VERSION ""

NS_ :

BS_:

BU_: BCM BSM DASM DIAG_TEST ESM ETM EVCU IPC LTM ORC SGW TBM
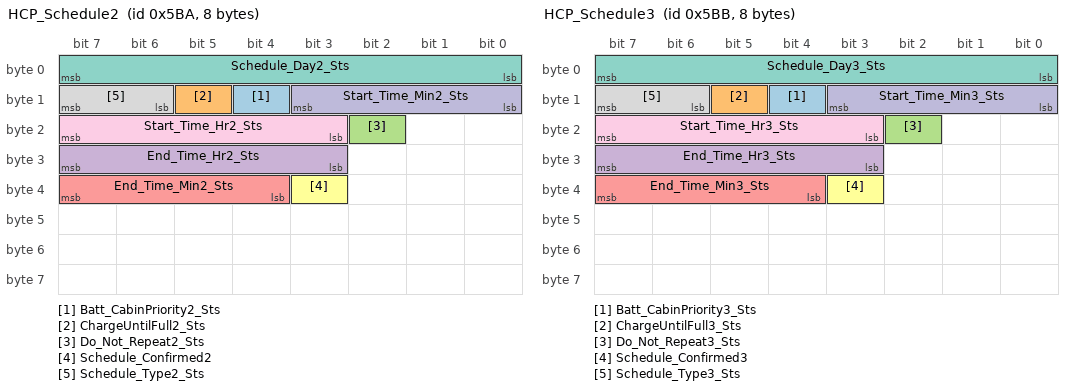
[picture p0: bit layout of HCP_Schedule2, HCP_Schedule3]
BO_ 1466 HCP_Schedule2: 8 EVCU
 SG_ Batt_CabinPriority2_Sts : 12|1@0+ (1,0) [0|1] "-" ETM,LTM,TBM
 SG_ ChargeUntilFull2_Sts : 13|1@0+ (1,0) [0|1] "-" ETM,LTM,TBM
 SG_ Do_Not_Repeat2_Sts : 18|1@0+ (1,0) [0|1] "-" ETM,LTM,TBM
 SG_ End_Time_Hr2_Sts : 31|5@0+ (1,0) [0|23] "Hours" ETM,LTM,TBM
 SG_ End_Time_Min2_Sts : 39|4@0+ (5,0) [0|55] "min" ETM,LTM,TBM
 SG_ Schedule_Confirmed2 : 35|1@0+ (1,0) [0|1] "-" ETM,LTM,TBM
 SG_ Schedule_Day2_Sts : 7|8@0+ (1,0) [0|255] "-" ETM,LTM,TBM
 SG_ Schedule_Type2_Sts : 15|2@0+ (1,0) [0|3] "-" ETM,LTM,TBM
 SG_ Start_Time_Hr2_Sts : 23|5@0+ (1,0) [0|23] "Hours" ETM,LTM,TBM
 SG_ Start_Time_Min2_Sts : 11|4@0+ (5,0) [0|55] "min" ETM,LTM,TBM

BO_ 1467 HCP_Schedule3: 8 EVCU
 SG_ Batt_CabinPriority3_Sts : 12|1@0+ (1,0) [0|1] "-" ETM,LTM,TBM
 SG_ ChargeUntilFull3_Sts : 13|1@0+ (1,0) [0|1] "-" ETM,LTM,TBM
 SG_ Do_Not_Repeat3_Sts : 18|1@0+ (1,0) [0|1] "-" ETM,LTM,TBM
 SG_ End_Time_Hr3_Sts : 31|5@0+ (1,0) [0|23] "Hours" ETM,LTM,TBM
 SG_ End_Time_Min3_Sts : 39|4@0+ (5,0) [0|55] "min" ETM,LTM,TBM
 SG_ Schedule_Confirmed3 : 35|1@0+ (1,0) [0|1] "-" ETM,LTM,TBM
 SG_ Schedule_Day3_Sts : 7|8@0+ (1,0) [0|255] "-" ETM,LTM,TBM
 SG_ Schedule_Type3_Sts : 15|2@0+ (1,0) [0|3] "-" ETM,LTM,TBM
 SG_ Start_Time_Hr3_Sts : 23|5@0+ (1,0) [0|23] "Hours" ETM,LTM,TBM
 SG_ Start_Time_Min3_Sts : 11|4@0+ (5,0) [0|55] "min" ETM,LTM,TBM

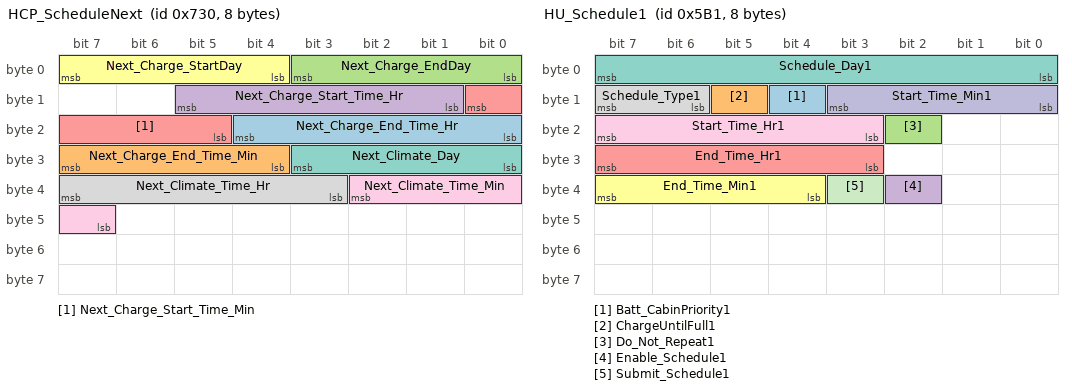
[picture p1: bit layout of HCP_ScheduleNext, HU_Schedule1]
BO_ 1840 HCP_ScheduleNext: 8 EVCU
 SG_ Next_Charge_End_Time_Hr : 20|5@0+ (1,0) [0|23] "Hours" ETM,IPC,LTM
 SG_ Next_Charge_End_Time_Min : 31|4@0+ (5,0) [0|55] "min" ETM,IPC,LTM
 SG_ Next_Charge_EndDay : 3|4@0+ (1,0) [0|15] "-" ETM,IPC,LTM
 SG_ Next_Charge_Start_Time_Hr : 13|5@0+ (1,0) [0|23] "Hours" ETM,IPC,LTM
 SG_ Next_Charge_Start_Time_Min : 8|4@0+ (5,0) [0|55] "min" ETM,IPC,LTM
 SG_ Next_Charge_StartDay : 7|4@0+ (1,0) [0|15] "-" ETM,IPC,LTM
 SG_ Next_Climate_Day : 27|4@0+ (1,0) [0|15] "-" ETM,LTM
 SG_ Next_Climate_Time_Hr : 39|5@0+ (1,0) [0|23] "Hours" ETM,LTM
 SG_ Next_Climate_Time_Min : 34|4@0+ (5,0) [0|55] "min" ETM,LTM

BO_ 2147565809 HP_DIAGNOSTIC_REQUEST_BCM: 8 DIAG_TEST
 SG_ N_PDU : 7|64@0+ (1,0) [0|0] "" BCM

BO_ 2147566833 HP_DIAGNOSTIC_REQUEST_BPCM: 8 DIAG_TEST
 SG_ N_PDU : 7|64@0+ (1,0) [0|0] "" EVCU

BO_ 2147560177 HP_DIAGNOSTIC_REQUEST_DASM: 8 DIAG_TEST
 SG_ N_PDU : 7|64@0+ (1,0) [0|0] "" DASM

BO_ 2147566321 HP_DIAGNOSTIC_REQUEST_EVCU: 8 DIAG_TEST
 SG_ N_PDU : 7|64@0+ (1,0) [0|0] "" EVCU

BO_ 2147569905 HP_DIAGNOSTIC_REQUEST_IDCM: 8 DIAG_TEST
 SG_ N_PDU : 7|64@0+ (1,0) [0|0] "" EVCU

BO_ 2147574001 HP_DIAGNOSTIC_REQUEST_IPC: 8 DIAG_TEST
 SG_ N_PDU : 7|64@0+ (1,0) [0|0] "-" IPC

BO_ 2147569649 HP_DIAGNOSTIC_REQUEST_RCU: 8 DIAG_TEST
 SG_ N_PDU : 7|64@0+ (1,0) [0|0] "" BCM

BO_ 2147601393 HP_DIAGNOSTIC_REQUEST_SGW: 8 DIAG_TEST
 SG_ N_PDU : 7|64@0+ (1,0) [0|0] "" SGW

BO_ 2147557361 HP_DIAGNOSTIC_REQUEST_SHIFTER: 8 DIAG_TEST
 SG_ N_PDU : 7|64@0+ (1,0) [0|0] "" ESM

BO_ 2147600113 HP_DIAGNOSTIC_REQUEST_TBM: 8 DIAG_TEST
 SG_ N_PDU : 7|64@0+ (1,0) [0|0] "" TBM

BO_ 2147571441 HP_DIAGNOSTIC_REQUEST_WSMD: 8 DIAG_TEST
 SG_ N_PDU : 7|64@0+ (1,0) [0|0] "" BCM

BO_ 2147571697 HP_DIAGNOSTIC_REQUEST_WSMP: 8 DIAG_TEST
 SG_ N_PDU : 7|64@0+ (1,0) [0|0] "" BCM

BO_ 1457 HU_Schedule1: 8 BCM
 SG_ Batt_CabinPriority1 : 12|1@0+ (1,0) [0|1] "-" EVCU
 SG_ ChargeUntilFull1 : 13|1@0+ (1,0) [0|1] "-" EVCU
 SG_ Do_Not_Repeat1 : 18|1@0+ (1,0) [0|1] "-" EVCU
 SG_ Enable_Schedule1 : 34|1@0+ (1,0) [0|1] "-" EVCU
 SG_ End_Time_Hr1 : 31|5@0+ (1,0) [0|23] "Hours" EVCU
 SG_ End_Time_Min1 : 39|4@0+ (5,0) [0|55] "min" EVCU
 SG_ Schedule_Day1 : 7|8@0+ (1,0) [0|255] "-" EVCU
 SG_ Schedule_Type1 : 15|2@0+ (1,0) [0|3] "-" EVCU
 SG_ Start_Time_Hr1 : 23|5@0+ (1,0) [0|23] "Hours" EVCU
 SG_ Start_Time_Min1 : 11|4@0+ (5,0) [0|55] "min" EVCU
 SG_ Submit_Schedule1 : 35|1@0+ (1,0) [0|1] "-" EVCU

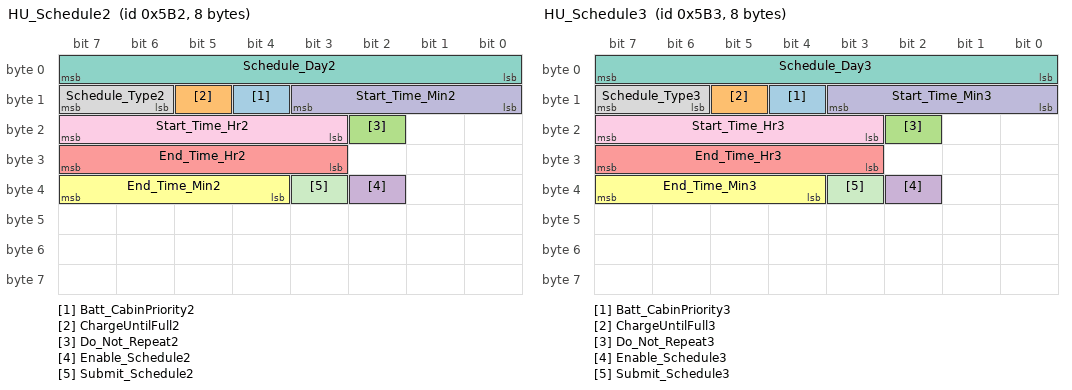
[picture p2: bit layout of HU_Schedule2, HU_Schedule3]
BO_ 1458 HU_Schedule2: 8 BCM
 SG_ Batt_CabinPriority2 : 12|1@0+ (1,0) [0|1] "-" EVCU
 SG_ ChargeUntilFull2 : 13|1@0+ (1,0) [0|1] "-" EVCU
 SG_ Do_Not_Repeat2 : 18|1@0+ (1,0) [0|1] "-" EVCU
 SG_ Enable_Schedule2 : 34|1@0+ (1,0) [0|1] "-" EVCU
 SG_ End_Time_Hr2 : 31|5@0+ (1,0) [0|23] "Hours" EVCU
 SG_ End_Time_Min2 : 39|4@0+ (5,0) [0|55] "min" EVCU
 SG_ Schedule_Day2 : 7|8@0+ (1,0) [0|255] "-" EVCU
 SG_ Schedule_Type2 : 15|2@0+ (1,0) [0|3] "-" EVCU
 SG_ Start_Time_Hr2 : 23|5@0+ (1,0) [0|23] "Hours" EVCU
 SG_ Start_Time_Min2 : 11|4@0+ (5,0) [0|55] "min" EVCU
 SG_ Submit_Schedule2 : 35|1@0+ (1,0) [0|1] "-" EVCU

BO_ 1459 HU_Schedule3: 8 BCM
 SG_ Batt_CabinPriority3 : 12|1@0+ (1,0) [0|1] "-" EVCU
 SG_ ChargeUntilFull3 : 13|1@0+ (1,0) [0|1] "-" EVCU
 SG_ Do_Not_Repeat3 : 18|1@0+ (1,0) [0|1] "-" EVCU
 SG_ Enable_Schedule3 : 34|1@0+ (1,0) [0|1] "-" EVCU
 SG_ End_Time_Hr3 : 31|5@0+ (1,0) [0|23] "Hours" EVCU
 SG_ End_Time_Min3 : 39|4@0+ (5,0) [0|55] "min" EVCU
 SG_ Schedule_Day3 : 7|8@0+ (1,0) [0|255] "-" EVCU
 SG_ Schedule_Type3 : 15|2@0+ (1,0) [0|3] "-" EVCU
 SG_ Start_Time_Hr3 : 23|5@0+ (1,0) [0|23] "Hours" EVCU
 SG_ Start_Time_Min3 : 11|4@0+ (5,0) [0|55] "min" EVCU
 SG_ Submit_Schedule3 : 35|1@0+ (1,0) [0|1] "-" EVCU

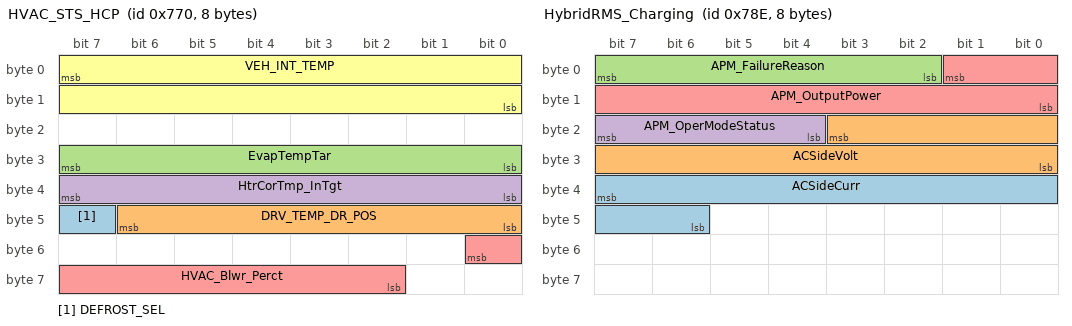
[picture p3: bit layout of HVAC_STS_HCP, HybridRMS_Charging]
BO_ 1904 HVAC_STS_HCP: 8 BCM
 SG_ DEFROST_SEL : 47|1@0+ (1,0) [0|1] "" EVCU
 SG_ DRV_TEMP_DR_POS : 46|7@0+ (1,0) [0|100] "%" EVCU
 SG_ EvapTempTar : 31|8@0+ (0.5,-20) [-20|107] "°C" EVCU
 SG_ HtrCorTmp_InTgt : 39|8@0+ (1,-40) [-40|214] "°C" EVCU
 SG_ HVAC_Blwr_Perct : 48|7@0+ (1,0) [0|100] "%" EVCU
 SG_ VEH_INT_TEMP : 7|16@0+ (0.01,-40) [-40|85] "°C" EVCU

BO_ 1933 HybridRMS_CellVoltage25: 8 Vector__XXX
 SG_ HVBatCellVltMax : 7|13@0+ (0.001,0) [0|5] "Volts" TBM

BO_ 1934 HybridRMS_Charging: 8 EVCU
 SG_ ACSideCurr : 39|10@0+ (0.1,-50) [-50|50] "Amp" TBM
 SG_ ACSideVolt : 19|12@0+ (0.1,0) [0|300] "Volt" TBM
 SG_ APM_FailureReason : 7|6@0+ (1,0) [0|62] "1" TBM
 SG_ APM_OperModeStatus : 23|4@0+ (1,0) [0|14] "" TBM
 SG_ APM_OutputPower : 1|10@0+ (3,0) [0|3066] "W" TBM

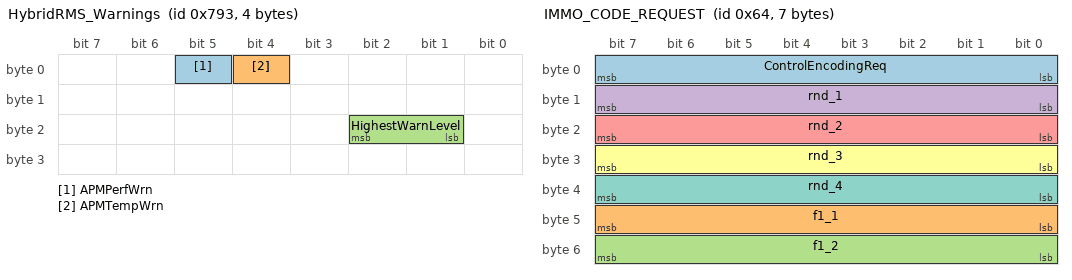
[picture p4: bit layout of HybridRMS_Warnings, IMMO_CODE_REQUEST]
BO_ 1939 HybridRMS_Warnings: 4 EVCU
 SG_ APMPerfWrn : 5|1@0+ (1,0) [0|1] "" Vector__XXX
 SG_ APMTempWrn : 4|1@0+ (1,0) [0|1] "" Vector__XXX
 SG_ HighestWarnLevel : 18|2@0+ (1,0) [0|3] "" TBM

BO_ 100 IMMO_CODE_REQUEST: 7 EVCU
 SG_ ControlEncodingReq : 7|8@0+ (1,0) [0|255] "-" BCM
 SG_ f1_1 : 47|8@0+ (1,0) [0|255] "-" BCM
 SG_ f1_2 : 55|8@0+ (1,0) [0|255] "-" BCM
 SG_ rnd_1 : 15|8@0+ (1,0) [0|255] "-" BCM
 SG_ rnd_2 : 23|8@0+ (1,0) [0|255] "-" BCM
 SG_ rnd_3 : 31|8@0+ (1,0) [0|255] "-" BCM
 SG_ rnd_4 : 39|8@0+ (1,0) [0|255] "-" BCM

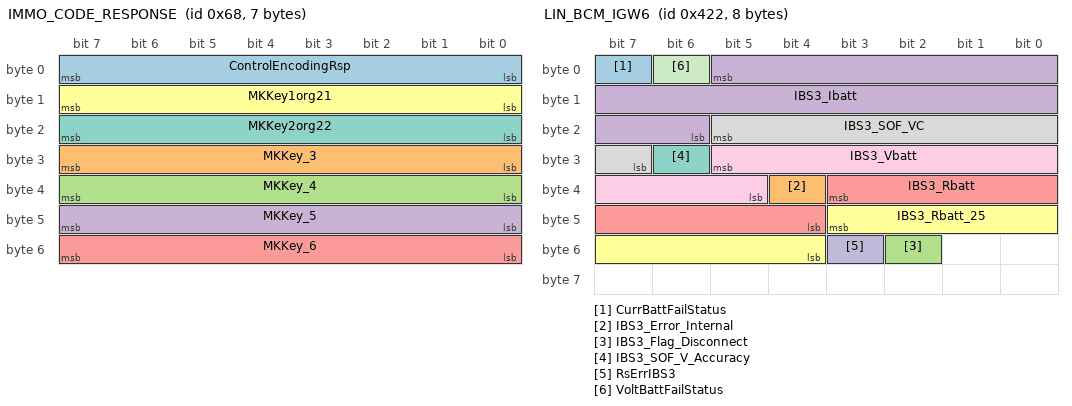
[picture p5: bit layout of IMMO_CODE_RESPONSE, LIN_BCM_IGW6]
BO_ 104 IMMO_CODE_RESPONSE: 7 BCM
 SG_ ControlEncodingRsp : 7|8@0+ (1,0) [0|255] "-" EVCU
 SG_ MKKey_3 : 31|8@0+ (1,0) [0|255] "-" EVCU
 SG_ MKKey_4 : 39|8@0+ (1,0) [0|255] "-" EVCU
 SG_ MKKey_5 : 47|8@0+ (1,0) [0|255] "-" EVCU
 SG_ MKKey_6 : 55|8@0+ (1,0) [0|255] "-" EVCU
 SG_ MKKey1org21 : 15|8@0+ (1,0) [0|255] "-" EVCU
 SG_ MKKey2org22 : 23|8@0+ (1,0) [0|255] "-" EVCU

BO_ 346 IMPACT_INFO: 4 ORC
 SG_ CRC_II : 31|8@0+ (1,0) [0|255] "" BCM,TBM
 SG_ IMPACT_A : 4|1@0+ (1,0) [0|1] "" TBM
 SG_ IMPACT_B : 3|1@0+ (1,0) [0|1] "" TBM
 SG_ IMPACT_C : 2|1@0+ (1,0) [0|1] "" TBM
 SG_ IMPACT_D : 1|1@0+ (1,0) [0|1] "" TBM
 SG_ IMPACT_E : 0|1@0+ (1,0) [0|1] "" TBM
 SG_ IMPACT_F : 15|1@0+ (1,0) [0|1] "" TBM
 SG_ IMPACT_G : 14|1@0+ (1,0) [0|1] "" TBM
 SG_ IMPACT_H : 13|1@0+ (1,0) [0|1] "" TBM
 SG_ IMPACT_I : 12|1@0+ (1,0) [0|1] "" TBM
 SG_ IMPACT_K : 11|1@0+ (1,0) [0|1] "" TBM
 SG_ IMPACT_L : 10|1@0+ (1,0) [0|1] "" TBM
 SG_ IMPACT_M : 9|1@0+ (1,0) [0|1] "" TBM
 SG_ IMPACT_O : 8|1@0+ (1,0) [0|1] "" TBM
 SG_ IMPACTCommand : 6|1@0+ (1,0) [0|1] "" BCM,EVCU,TBM
 SG_ IMPACTConfirm : 7|1@0+ (1,0) [0|1] "" BCM,EVCU,TBM
 SG_ IMPACTFailSts : 5|1@0+ (1,0) [0|1] "" BCM,TBM
 SG_ MessageCounter_II : 19|4@0+ (1,0) [0|15] "" BCM,TBM

BO_ 1058 LIN_BCM_IGW6: 8 BCM
 SG_ CurrBattFailStatus : 7|1@0+ (1,0) [0|1] "-" Vector__XXX
 SG_ IBS3_Error_Internal : 36|1@0+ (1,0) [0|1] "-" Vector__XXX
 SG_ IBS3_Flag_Disconnect : 50|1@0+ (1,0) [0|1] "-" Vector__XXX
 SG_ IBS3_Ibatt : 5|16@0+ (0.02,-1000) [-1000|310.7] "A" TBM
 SG_ IBS3_Rbatt : 35|8@0+ (0.1,0) [0|25.5] "mOhm" Vector__XXX
 SG_ IBS3_Rbatt_25 : 43|8@0+ (0.1,0) [0|25.5] "mOhm" Vector__XXX
 SG_ IBS3_SOF_V_Accuracy : 30|1@0+ (1,0) [0|1] "-" Vector__XXX
 SG_ IBS3_SOF_VC : 21|7@0+ (0.05,5) [5|11.35] "V" Vector__XXX
 SG_ IBS3_Vbatt : 29|9@0+ (0.025,5) [5|17.775] "V" EVCU,TBM
 SG_ RsErrIBS3 : 51|1@0+ (1,0) [0|1] "-" Vector__XXX
 SG_ VoltBattFailStatus : 6|1@0+ (1,0) [0|1] "-" EVCU

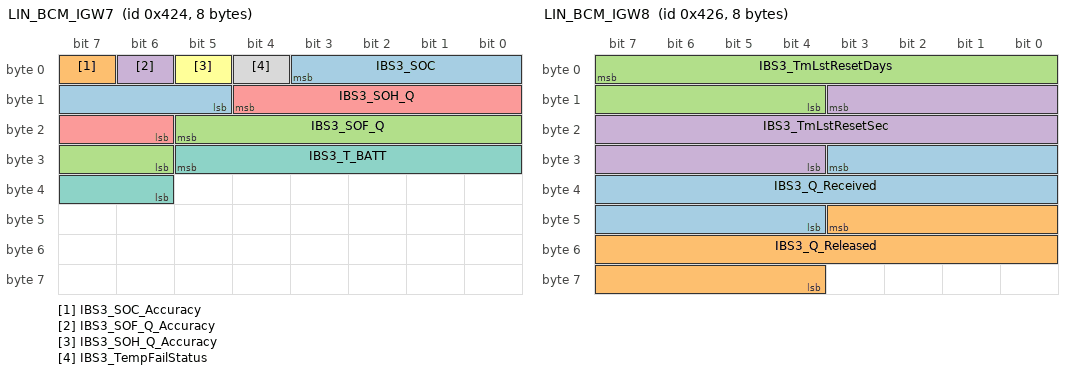
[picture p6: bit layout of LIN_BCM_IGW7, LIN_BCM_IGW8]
BO_ 1060 LIN_BCM_IGW7: 8 BCM
 SG_ IBS3_SOC : 3|7@0+ (1,0) [0|127] "%" EVCU,ORC,TBM
 SG_ IBS3_SOC_Accuracy : 7|1@0+ (1,0) [0|1] "-" EVCU,TBM
 SG_ IBS3_SOF_Q : 21|8@0+ (1,0) [0|255] "Ah" Vector__XXX
 SG_ IBS3_SOF_Q_Accuracy : 6|1@0+ (1,0) [0|1] "-" Vector__XXX
 SG_ IBS3_SOH_Q : 12|7@0+ (2,0) [0|254] "Ah" Vector__XXX
 SG_ IBS3_SOH_Q_Accuracy : 5|1@0+ (1,0) [0|1] "-" Vector__XXX
 SG_ IBS3_T_BATT : 29|8@0+ (1,-40) [-40|215] "°C" EVCU,TBM
 SG_ IBS3_TempFailStatus : 4|1@0+ (1,0) [0|1] "-" EVCU

BO_ 1062 LIN_BCM_IGW8: 8 BCM
 SG_ IBS3_Q_Received : 27|16@0+ (0.125,0) [0|8191] "Ah" Vector__XXX
 SG_ IBS3_Q_Released : 43|16@0+ (0.125,0) [0|8191] "Ah" Vector__XXX
 SG_ IBS3_TmLstResetDays : 7|12@0+ (1,0) [0|4094] "Days" Vector__XXX
 SG_ IBS3_TmLstResetSec : 11|16@0+ (2,0) [0|131068] "sec" Vector__XXX

BO_ 256 MOT_TRANSM1: 8 EVCU
 SG_ ECM_LHOM : 7|1@0+ (1,0) [0|1] "-" ORC

BO_ 500 MOT_TRANSM3: 8 EVCU
 SG_ CRC_MT3 : 63|8@0+ (1,0) [0|255] "" BCM,DASM
 SG_ Message_Counter_MT3 : 51|4@0+ (1,0) [0|15] "" BCM,DASM

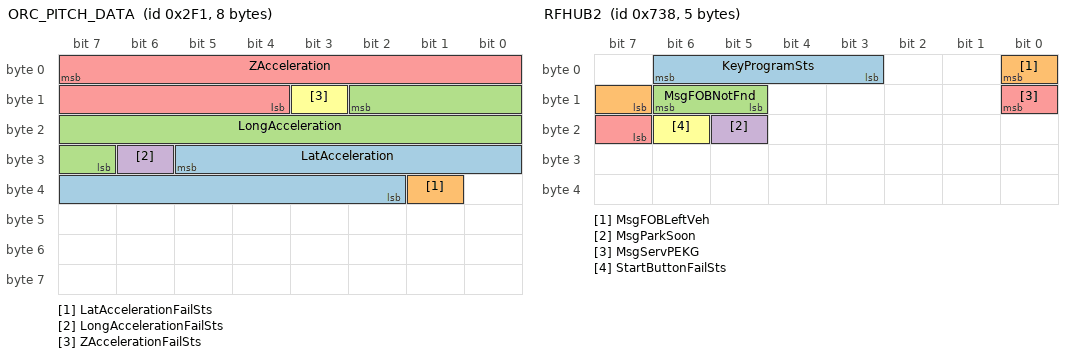
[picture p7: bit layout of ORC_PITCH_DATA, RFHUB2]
BO_ 753 ORC_PITCH_DATA: 8 ORC
 SG_ LatAcceleration : 29|12@0+ (0.02,-40.96) [-40.96|40.92] "m/s^2" Vector__XXX
 SG_ LatAccelerationFailSts : 33|1@0+ (1,0) [0|1] "-" Vector__XXX
 SG_ LongAcceleration : 10|12@0+ (0.02,-40.96) [-40.96|40.92] "m/s^2" Vector__XXX
 SG_ LongAccelerationFailSts : 30|1@0+ (1,0) [0|1] "-" Vector__XXX
 SG_ ZAcceleration : 7|12@0+ (0.02,-40.96) [-40.96|40.94] "m/s^2" TBM
 SG_ ZAccelerationFailSts : 11|1@0+ (1,0) [0|1] "-" Vector__XXX

BO_ 1848 RFHUB2: 5 BCM
 SG_ KeyProgramSts : 6|4@0+ (1,0) [0|15] "" IPC
 SG_ MsgFOBLeftVeh : 0|2@0+ (1,0) [0|2] "" IPC
 SG_ MsgFOBNotFnd : 14|2@0+ (1,0) [0|2] "" IPC
 SG_ MsgParkSoon : 21|1@0+ (1,0) [0|1] "" IPC
 SG_ MsgServPEKG : 8|2@0+ (1,0) [0|3] "" IPC
 SG_ StartButtonFailSts : 22|1@0+ (1,0) [0|1] "" IPC

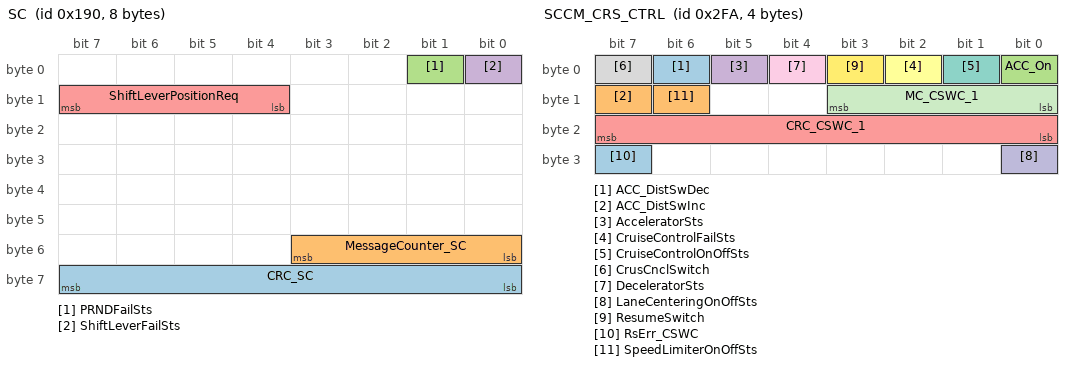
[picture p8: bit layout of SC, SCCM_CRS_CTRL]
BO_ 400 SC: 8 ESM
 SG_ CRC_SC : 63|8@0+ (1,0) [0|255] "" EVCU
 SG_ MessageCounter_SC : 51|4@0+ (1,0) [0|15] "" EVCU
 SG_ PRNDFailSts : 1|1@0+ (1,0) [0|1] "-" EVCU
 SG_ ShiftLeverFailSts : 0|1@0+ (1,0) [0|1] "-" EVCU,IPC
 SG_ ShiftLeverPositionReq : 15|4@0+ (1,0) [0|7] "-" EVCU

BO_ 762 SCCM_CRS_CTRL: 4 BCM
 SG_ ACC_DistSwDec : 6|1@0+ (1,0) [0|1] "" TBM
 SG_ ACC_DistSwInc : 15|1@0+ (1,0) [0|1] "" TBM
 SG_ ACC_On : 0|1@0+ (1,0) [0|1] "" EVCU,TBM
 SG_ AcceleratorSts : 5|1@0+ (1,0) [0|1] "" EVCU,TBM
 SG_ CRC_CSWC_1 : 23|8@0+ (1,0) [0|255] "" EVCU
 SG_ CruiseControlFailSts : 2|1@0+ (1,0) [0|1] "" EVCU,ORC
 SG_ CruiseControlOnOffSts : 1|1@0+ (1,0) [0|1] "" EVCU,ORC,TBM
 SG_ CrusCnclSwitch : 7|1@0+ (1,0) [0|1] "" EVCU,TBM
 SG_ DeceleratorSts : 4|1@0+ (1,0) [0|1] "" EVCU,TBM
 SG_ LaneCenteringOnOffSts : 24|1@0+ (1,0) [0|1] "" EVCU
 SG_ MC_CSWC_1 : 11|4@0+ (1,0) [0|15] "" EVCU
 SG_ ResumeSwitch : 3|1@0+ (1,0) [0|1] "" EVCU,TBM
 SG_ RsErr_CSWC : 31|1@0+ (1,0) [0|1] "" Vector__XXX
 SG_ SpeedLimiterOnOffSts : 14|1@0+ (1,0) [0|1] "" EVCU

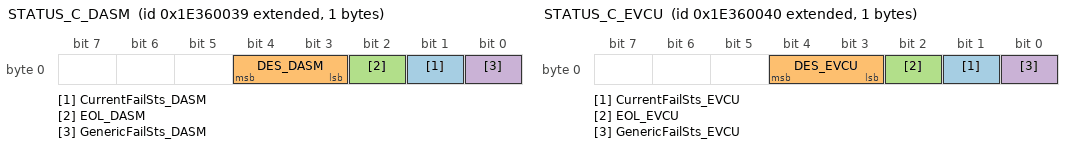
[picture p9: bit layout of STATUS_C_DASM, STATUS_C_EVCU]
BO_ 2654339129 STATUS_C_DASM: 1 DASM
 SG_ CurrentFailSts_DASM : 1|1@0+ (1,0) [0|1] "-" BCM
 SG_ DES_DASM : 4|2@0+ (1,0) [0|2] "-" Vector__XXX
 SG_ EOL_DASM : 2|1@0+ (1,0) [0|1] "-" BCM
 SG_ GenericFailSts_DASM : 0|1@0+ (1,0) [0|1] "-" BCM

BO_ 2654339136 STATUS_C_EVCU: 1 EVCU
 SG_ CurrentFailSts_EVCU : 1|1@0+ (1,0) [0|1] "-" BCM,TBM
 SG_ DES_EVCU : 4|2@0+ (1,0) [0|2] "-" Vector__XXX
 SG_ EOL_EVCU : 2|1@0+ (1,0) [0|1] "-" BCM
 SG_ GenericFailSts_EVCU : 0|1@0+ (1,0) [0|1] "-" BCM,TBM

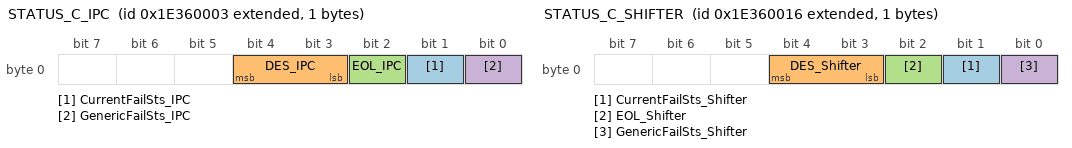
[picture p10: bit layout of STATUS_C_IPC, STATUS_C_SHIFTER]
BO_ 2654339075 STATUS_C_IPC: 1 IPC
 SG_ CurrentFailSts_IPC : 1|1@0+ (1,0) [0|1] "-" BCM
 SG_ DES_IPC : 4|2@0+ (1,0) [0|2] "-" Vector__XXX
 SG_ EOL_IPC : 2|1@0+ (1,0) [0|1] "-" BCM
 SG_ GenericFailSts_IPC : 0|1@0+ (1,0) [0|1] "-" BCM

BO_ 2654339094 STATUS_C_SHIFTER: 1 ESM
 SG_ CurrentFailSts_Shifter : 1|1@0+ (1,0) [0|1] "-" BCM
 SG_ DES_Shifter : 4|2@0+ (1,0) [0|2] "-" Vector__XXX
 SG_ EOL_Shifter : 2|1@0+ (1,0) [0|1] "-" BCM
 SG_ GenericFailSts_Shifter : 0|1@0+ (1,0) [0|1] "-" BCM

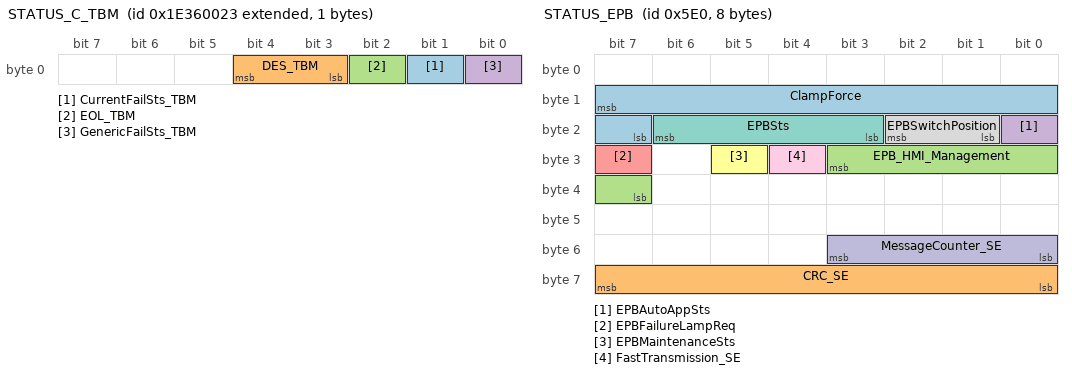
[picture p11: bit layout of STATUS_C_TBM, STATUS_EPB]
BO_ 2654339107 STATUS_C_TBM: 1 TBM
 SG_ CurrentFailSts_TBM : 1|1@0+ (1,0) [0|1] "-" BCM
 SG_ DES_TBM : 4|2@0+ (1,0) [0|2] "-" Vector__XXX
 SG_ EOL_TBM : 2|1@0+ (1,0) [0|1] "-" BCM
 SG_ GenericFailSts_TBM : 0|1@0+ (1,0) [0|1] "-" BCM

BO_ 1504 STATUS_EPB: 8 BSM
 SG_ ClampForce : 15|9@0+ (0.1,-0.1) [0|51] "KN" Vector__XXX
 SG_ CRC_SE : 63|8@0+ (1,0) [0|255] "" BCM,DASM,EVCU
 SG_ EPB_HMI_Management : 27|5@0+ (1,0) [0|31] "" IPC
 SG_ EPBAutoAppSts : 16|1@0+ (1,0) [0|1] "" IPC
 SG_ EPBFailureLampReq : 31|1@0+ (1,0) [0|1] "" IPC,ORC,TBM
 SG_ EPBMaintenanceSts : 29|1@0+ (1,0) [0|1] "" IPC
 SG_ EPBSts : 22|4@0+ (1,0) [0|14] "-" BCM,EVCU,IPC,ORC,TBM
 SG_ EPBSwitchPosition : 18|2@0+ (1,0) [0|3] "" Vector__XXX
 SG_ FastTransmission_SE : 28|1@0+ (1,0) [0|1] "" Vector__XXX
 SG_ MessageCounter_SE : 51|4@0+ (1,0) [0|15] "" BCM,DASM,EVCU

BO_ 1941 STATUS_EVCU: 8 EVCU
 SG_ PowerModeSts_EVCU : 7|2@0+ (1,0) [0|3] "-" BCM,TBM

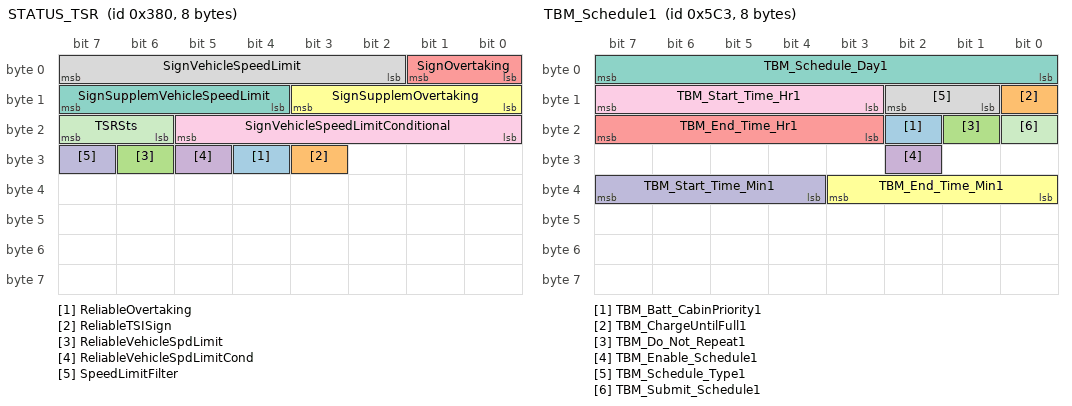
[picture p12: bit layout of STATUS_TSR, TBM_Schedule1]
BO_ 896 STATUS_TSR: 8 BCM
 SG_ ReliableOvertaking : 28|1@0+ (1,0) [0|1] "" IPC
 SG_ ReliableTSISign : 27|1@0+ (1,0) [0|1] "" IPC
 SG_ ReliableVehicleSpdLimit : 30|1@0+ (1,0) [0|1] "" IPC
 SG_ ReliableVehicleSpdLimitCond : 29|1@0+ (1,0) [0|1] "" IPC
 SG_ SignOvertaking : 1|2@0+ (1,0) [0|3] "" IPC
 SG_ SignSupplemOvertaking : 11|4@0+ (1,0) [0|15] "" IPC
 SG_ SignSupplemVehicleSpeedLimit : 15|4@0+ (1,0) [0|15] "" IPC
 SG_ SignVehicleSpeedLimit : 7|6@0+ (1,0) [0|63] "" IPC
 SG_ SignVehicleSpeedLimitConditional : 21|6@0+ (1,0) [0|63] "" IPC
 SG_ SpeedLimitFilter : 31|1@0+ (1,0) [0|1] "" IPC
 SG_ TSRSts : 23|2@0+ (1,0) [0|3] "" ETM,EVCU,IPC

BO_ 1475 TBM_Schedule1: 8 BCM
 SG_ TBM_Batt_CabinPriority1 : 18|1@0+ (1,0) [0|1] "-" EVCU
 SG_ TBM_ChargeUntilFull1 : 8|1@0+ (1,0) [0|1] "-" EVCU
 SG_ TBM_Do_Not_Repeat1 : 17|1@0+ (1,0) [0|1] "-" EVCU
 SG_ TBM_Enable_Schedule1 : 26|1@0+ (1,0) [0|1] "-" EVCU
 SG_ TBM_End_Time_Hr1 : 23|5@0+ (1,0) [0|23] "Hours" EVCU
 SG_ TBM_End_Time_Min1 : 35|4@0+ (5,0) [0|55] "min" EVCU
 SG_ TBM_Schedule_Day1 : 7|8@0+ (1,0) [0|255] "-" EVCU
 SG_ TBM_Schedule_Type1 : 10|2@0+ (1,0) [0|3] "-" EVCU
 SG_ TBM_Start_Time_Hr1 : 15|5@0+ (1,0) [0|23] "Hours" EVCU
 SG_ TBM_Start_Time_Min1 : 39|4@0+ (5,0) [0|55] "min" EVCU
 SG_ TBM_Submit_Schedule1 : 16|1@0+ (1,0) [0|1] "-" EVCU

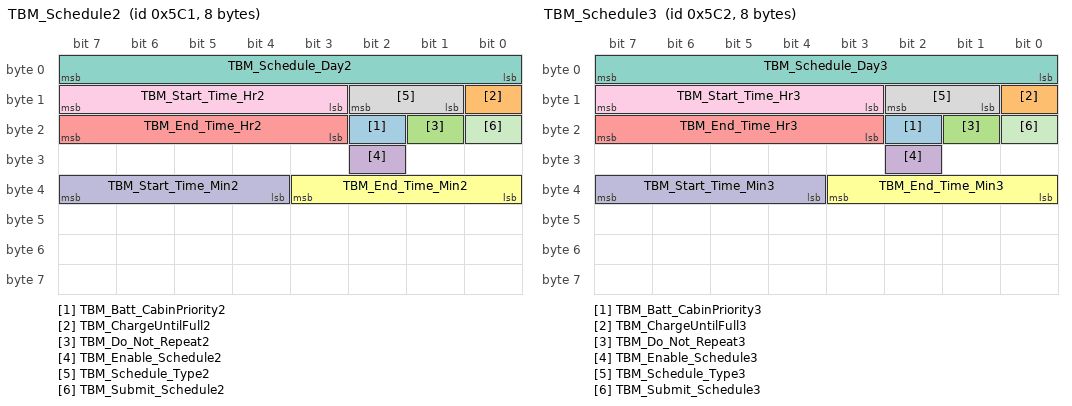
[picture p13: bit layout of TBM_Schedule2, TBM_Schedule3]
BO_ 1473 TBM_Schedule2: 8 BCM
 SG_ TBM_Batt_CabinPriority2 : 18|1@0+ (1,0) [0|1] "-" EVCU
 SG_ TBM_ChargeUntilFull2 : 8|1@0+ (1,0) [0|1] "-" EVCU
 SG_ TBM_Do_Not_Repeat2 : 17|1@0+ (1,0) [0|1] "-" EVCU
 SG_ TBM_Enable_Schedule2 : 26|1@0+ (1,0) [0|1] "-" EVCU
 SG_ TBM_End_Time_Hr2 : 23|5@0+ (1,0) [0|23] "Hours" EVCU
 SG_ TBM_End_Time_Min2 : 35|4@0+ (5,0) [0|55] "min" EVCU
 SG_ TBM_Schedule_Day2 : 7|8@0+ (1,0) [0|255] "-" EVCU
 SG_ TBM_Schedule_Type2 : 10|2@0+ (1,0) [0|3] "-" EVCU
 SG_ TBM_Start_Time_Hr2 : 15|5@0+ (1,0) [0|23] "Hours" EVCU
 SG_ TBM_Start_Time_Min2 : 39|4@0+ (5,0) [0|55] "min" EVCU
 SG_ TBM_Submit_Schedule2 : 16|1@0+ (1,0) [0|1] "-" EVCU

BO_ 1474 TBM_Schedule3: 8 BCM
 SG_ TBM_Batt_CabinPriority3 : 18|1@0+ (1,0) [0|1] "-" EVCU
 SG_ TBM_ChargeUntilFull3 : 8|1@0+ (1,0) [0|1] "-" EVCU
 SG_ TBM_Do_Not_Repeat3 : 17|1@0+ (1,0) [0|1] "-" EVCU
 SG_ TBM_Enable_Schedule3 : 26|1@0+ (1,0) [0|1] "-" EVCU
 SG_ TBM_End_Time_Hr3 : 23|5@0+ (1,0) [0|23] "Hours" EVCU
 SG_ TBM_End_Time_Min3 : 35|4@0+ (5,0) [0|55] "min" EVCU
 SG_ TBM_Schedule_Day3 : 7|8@0+ (1,0) [0|255] "-" EVCU
 SG_ TBM_Schedule_Type3 : 10|2@0+ (1,0) [0|3] "-" EVCU
 SG_ TBM_Start_Time_Hr3 : 15|5@0+ (1,0) [0|23] "Hours" EVCU
 SG_ TBM_Start_Time_Min3 : 39|4@0+ (5,0) [0|55] "min" EVCU
 SG_ TBM_Submit_Schedule3 : 16|1@0+ (1,0) [0|1] "-" EVCU

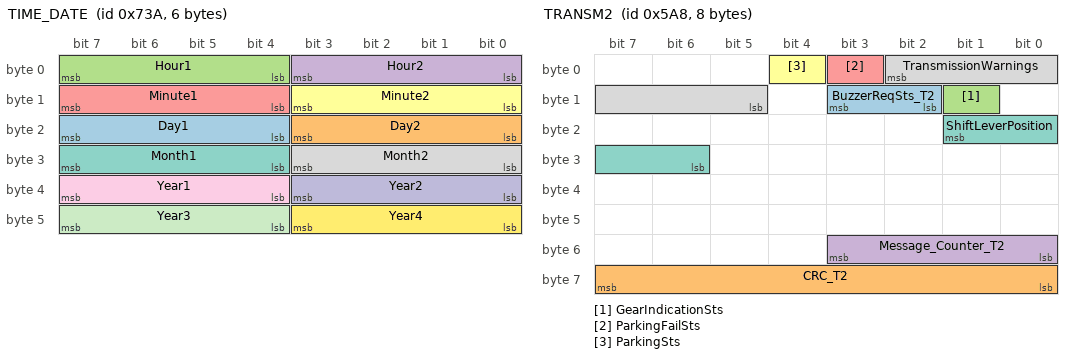
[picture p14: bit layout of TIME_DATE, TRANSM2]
BO_ 1850 TIME_DATE: 6 IPC
 SG_ Day1 : 23|4@0+ (1,0) [0|9] "-" BCM,BSM,EVCU
 SG_ Day2 : 19|4@0+ (1,0) [0|9] "-" BCM,BSM,EVCU
 SG_ Hour1 : 7|4@0+ (1,0) [0|9] "-" BCM,BSM,EVCU
 SG_ Hour2 : 3|4@0+ (1,0) [0|9] "-" BCM,BSM,EVCU
 SG_ Minute1 : 15|4@0+ (1,0) [0|9] "-" BCM,BSM,EVCU
 SG_ Minute2 : 11|4@0+ (1,0) [0|9] "-" BCM,BSM,EVCU
 SG_ Month1 : 31|4@0+ (1,0) [0|9] "-" BCM,BSM,EVCU
 SG_ Month2 : 27|4@0+ (1,0) [0|9] "-" BCM,BSM,EVCU
 SG_ Year1 : 39|4@0+ (1,0) [0|9] "-" BCM,BSM,EVCU
 SG_ Year2 : 35|4@0+ (1,0) [0|9] "-" BCM,BSM,EVCU
 SG_ Year3 : 47|4@0+ (1,0) [0|9] "-" BCM,BSM,EVCU
 SG_ Year4 : 43|4@0+ (1,0) [0|9] "-" BCM,BSM,EVCU

BO_ 1000 TPM_CAL: 1 BSM
 SG_ CalibrationAck : 5|2@0+ (1,0) [0|3] "-" IPC
 SG_ CalibrationSts : 7|2@0+ (1,0) [0|3] "-" Vector__XXX

BO_ 1448 TRANSM2: 8 EVCU
 SG_ BuzzerReqSts_T2 : 11|2@0+ (1,0) [0|3] "" IPC
 SG_ CRC_T2 : 63|8@0+ (1,0) [0|255] "count" BCM,BSM,DASM,ESM
 SG_ GearIndicationSts : 9|1@0+ (1,0) [0|1] "-" ESM,IPC
 SG_ Message_Counter_T2 : 51|4@0+ (1,0) [0|15] "" BCM,BSM,DASM,ESM
 SG_ ParkingFailSts : 3|1@0+ (1,0) [0|1] "-" BCM,IPC,TBM
 SG_ ParkingSts : 4|1@0+ (1,0) [0|1] "-" BCM
 SG_ ShiftLeverPosition : 17|4@0+ (1,0) [0|15] "-" BCM,BSM,ESM,ETM,IPC,LTM,TBM
 SG_ TransmissionWarnings : 2|6@0+ (1,0) [0|63] "-" IPC,TBM

BO_ 344 TRANSM3: 4 EVCU
 SG_ Vehicle_Hold_Rq : 5|1@0+ (1,0) [0|1] "-" BSM

BO_ 253 TRM_CODE_RESPONSE: 6 BCM
 SG_ TxpFound : 31|1@0+ (1,0) [0|1] "-" Vector__XXX
 SG_ TxpID : 30|4@0+ (1,0) [0|15] "-" Vector__XXX

BO_ 1046 VIN: 8 BCM
 SG_ VIN_DATA : 15|56@0+ (1,0) [0|7.20575940379279E+16] "" DASM,ESM,EVCU,IPC,ORC
 SG_ VIN_MSG : 1|2@0+ (1,0) [0|3] "" DASM,ESM,EVCU,IPC,ORC

BO_ 2654208000 WAKE_C_BCM: 8 BCM
 SG_ MainWakeSts_BCM : 7|1@0+ (1,0) [0|1] "-" BSM,ESM,EVCU,IPC,TBM
 SG_ Node0 : 40|1@0+ (1,0) [0|1] "-" BSM,ESM,EVCU,IPC,TBM
 SG_ Node1 : 41|1@0+ (1,0) [0|1] "-" BSM,ESM,EVCU,IPC,TBM
 SG_ Node10 : 34|1@0+ (1,0) [0|1] "-" BSM,ESM,EVCU,IPC,TBM
 SG_ Node11 : 35|1@0+ (1,0) [0|1] "-" BSM,ESM,EVCU,IPC,TBM
 SG_ Node12 : 36|1@0+ (1,0) [0|1] "-" BSM,ESM,EVCU,IPC,TBM
 SG_ Node13 : 37|1@0+ (1,0) [0|1] "-" BSM,ESM,EVCU,IPC,TBM
 SG_ Node14 : 38|1@0+ (1,0) [0|1] "-" BSM,ESM,EVCU,IPC,TBM
 SG_ Node15 : 39|1@0+ (1,0) [0|1] "-" BSM,ESM,EVCU,IPC,TBM
 SG_ Node16 : 24|1@0+ (1,0) [0|1] "-" BSM,ESM,EVCU,IPC,TBM
 SG_ Node17 : 25|1@0+ (1,0) [0|1] "-" BSM,ESM,EVCU,IPC,TBM
 SG_ Node18 : 26|1@0+ (1,0) [0|1] "-" BSM,ESM,EVCU,IPC,TBM
 SG_ Node19 : 27|1@0+ (1,0) [0|1] "-" BSM,ESM,EVCU,IPC,TBM
 SG_ Node2 : 42|1@0+ (1,0) [0|1] "-" BSM,ESM,EVCU,IPC,TBM
 SG_ Node20 : 28|1@0+ (1,0) [0|1] "-" BSM,ESM,EVCU,IPC,TBM
 SG_ Node21 : 29|1@0+ (1,0) [0|1] "-" BSM,ESM,EVCU,IPC,TBM
 SG_ Node22 : 30|1@0+ (1,0) [0|1] "-" BSM,ESM,EVCU,IPC,TBM
 SG_ Node23 : 31|1@0+ (1,0) [0|1] "-" BSM,ESM,EVCU,IPC,TBM
 SG_ Node24 : 16|1@0+ (1,0) [0|1] "-" BSM,ESM,EVCU,IPC,TBM
 SG_ Node25 : 17|1@0+ (1,0) [0|1] "-" BSM,ESM,EVCU,IPC,TBM
 SG_ Node26 : 18|1@0+ (1,0) [0|1] "-" BSM,ESM,EVCU,IPC,TBM
 SG_ Node27 : 19|1@0+ (1,0) [0|1] "-" BSM,ESM,EVCU,IPC,TBM
 SG_ Node28 : 20|1@0+ (1,0) [0|1] "-" BSM,ESM,EVCU,IPC,TBM
 SG_ Node29 : 21|1@0+ (1,0) [0|1] "-" BSM,ESM,EVCU,IPC,TBM
 SG_ Node3 : 43|1@0+ (1,0) [0|1] "-" BSM,ESM,EVCU,IPC,TBM
 SG_ Node30 : 22|1@0+ (1,0) [0|1] "-" BSM,ESM,EVCU,IPC,TBM
 SG_ Node31 : 23|1@0+ (1,0) [0|1] "-" BSM,ESM,EVCU,IPC,TBM
 SG_ Node4 : 44|1@0+ (1,0) [0|1] "-" BSM,ESM,EVCU,IPC,TBM
 SG_ Node5 : 45|1@0+ (1,0) [0|1] "-" BSM,ESM,EVCU,IPC,TBM
 SG_ Node6 : 46|1@0+ (1,0) [0|1] "-" BSM,ESM,EVCU,IPC,TBM
 SG_ Node7 : 47|1@0+ (1,0) [0|1] "-" BSM,ESM,EVCU,IPC,TBM
 SG_ Node8 : 32|1@0+ (1,0) [0|1] "-" BSM,ESM,EVCU,IPC,TBM
 SG_ Node9 : 33|1@0+ (1,0) [0|1] "-" BSM,ESM,EVCU,IPC,TBM
 SG_ WakeCntr_BCM : 15|8@0+ (1,0) [0|255] "-" Vector__XXX
 SG_ WakeRsn_BCM : 6|7@0+ (1,0) [0|127] "-" Vector__XXX

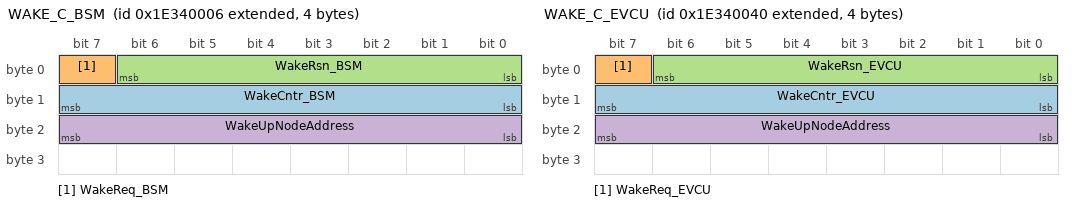
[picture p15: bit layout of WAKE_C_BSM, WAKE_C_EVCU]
BO_ 2654208006 WAKE_C_BSM: 4 BSM
 SG_ WakeCntr_BSM : 15|8@0+ (1,0) [0|255] "" Vector__XXX
 SG_ WakeReq_BSM : 7|1@0+ (1,0) [0|1] "" BCM
 SG_ WakeRsn_BSM : 6|7@0+ (1,0) [0|127] "" Vector__XXX
 SG_ WakeUpNodeAddress : 23|8@0+ (1,0) [0|255] "" BCM

BO_ 2654208064 WAKE_C_EVCU: 4 EVCU
 SG_ WakeCntr_EVCU : 15|8@0+ (1,0) [0|255] "" Vector__XXX
 SG_ WakeReq_EVCU : 7|1@0+ (1,0) [0|1] "" BCM
 SG_ WakeRsn_EVCU : 6|7@0+ (1,0) [0|127] "" TBM
 SG_ WakeUpNodeAddress : 23|8@0+ (1,0) [0|255] "" BCM

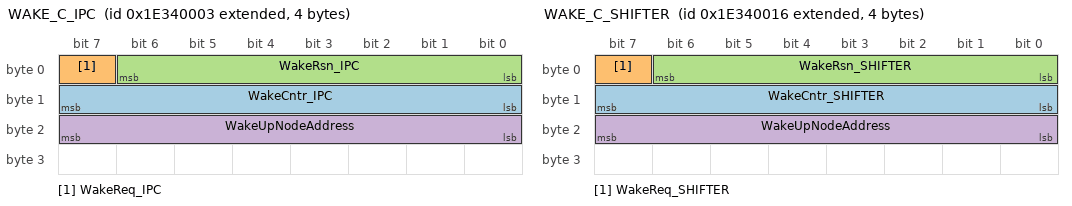
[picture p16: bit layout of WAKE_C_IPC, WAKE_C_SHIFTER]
BO_ 2654208003 WAKE_C_IPC: 4 IPC
 SG_ WakeCntr_IPC : 15|8@0+ (1,0) [0|255] "" Vector__XXX
 SG_ WakeReq_IPC : 7|1@0+ (1,0) [0|1] "" BCM
 SG_ WakeRsn_IPC : 6|7@0+ (1,0) [0|127] "" Vector__XXX
 SG_ WakeUpNodeAddress : 23|8@0+ (1,0) [0|255] "" BCM

BO_ 2654208022 WAKE_C_SHIFTER: 4 ESM
 SG_ WakeCntr_SHIFTER : 15|8@0+ (1,0) [0|255] "" Vector__XXX
 SG_ WakeReq_SHIFTER : 7|1@0+ (1,0) [0|1] "" BCM
 SG_ WakeRsn_SHIFTER : 6|7@0+ (1,0) [0|127] "" Vector__XXX
 SG_ WakeUpNodeAddress : 23|8@0+ (1,0) [0|255] "" BCM

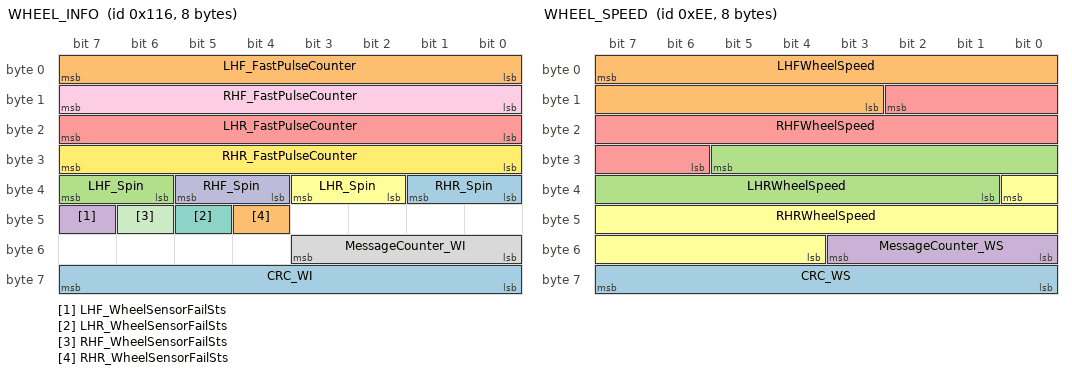
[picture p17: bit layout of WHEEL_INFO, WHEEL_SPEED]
BO_ 278 WHEEL_INFO: 8 BSM
 SG_ CRC_WI : 63|8@0+ (1,0) [0|255] "-" BCM,DASM
 SG_ LHF_FastPulseCounter : 7|8@0+ (1,0) [0|255] "pulse" BCM,DASM,TBM
 SG_ LHF_Spin : 39|2@0+ (1,0) [0|3] "-" EVCU,TBM
 SG_ LHF_WheelSensorFailSts : 47|1@0+ (1,0) [0|1] "-" BCM,DASM,EVCU,TBM
 SG_ LHR_FastPulseCounter : 23|8@0+ (1,0) [0|255] "pulse" BCM,DASM,ORC,TBM
 SG_ LHR_Spin : 35|2@0+ (1,0) [0|3] "-" BCM,DASM,EVCU,TBM
 SG_ LHR_WheelSensorFailSts : 45|1@0+ (1,0) [0|1] "-" BCM,DASM,EVCU,TBM
 SG_ MessageCounter_WI : 51|4@0+ (1,0) [0|15] "-" BCM,DASM
 SG_ RHF_FastPulseCounter : 15|8@0+ (1,0) [0|255] "pulse" BCM,DASM,TBM
 SG_ RHF_Spin : 37|2@0+ (1,0) [0|3] "-" EVCU,TBM
 SG_ RHF_WheelSensorFailSts : 46|1@0+ (1,0) [0|1] "-" BCM,DASM,EVCU,TBM
 SG_ RHR_FastPulseCounter : 31|8@0+ (1,0) [0|255] "pulse" BCM,DASM,ORC,TBM
 SG_ RHR_Spin : 33|2@0+ (1,0) [0|3] "-" BCM,DASM,EVCU,TBM
 SG_ RHR_WheelSensorFailSts : 44|1@0+ (1,0) [0|1] "-" BCM,DASM,EVCU,TBM

BO_ 238 WHEEL_SPEED: 8 BSM
 SG_ CRC_WS : 63|8@0+ (1,0) [0|255] "" DASM,EVCU
 SG_ LHFWheelSpeed : 7|13@0+ (0.0625,0) [0|511.875] "Km/h" DASM,EVCU,ORC,TBM
 SG_ LHRWheelSpeed : 29|13@0+ (0.0625,0) [0|511.875] "Km/h" DASM,EVCU,ORC,TBM
 SG_ MessageCounter_WS : 51|4@0+ (1,0) [0|15] "" DASM,EVCU
 SG_ RHFWheelSpeed : 10|13@0+ (0.0625,0) [0|511.875] "Km/h" DASM,EVCU,ORC,TBM
 SG_ RHRWheelSpeed : 32|13@0+ (0.0625,0) [0|511.875] "Km/h" DASM,EVCU,ORC,TBM

CM_ SG_ 1466 Batt_CabinPriority2_Sts "Confirmation to the bit to prioritize battery charging or cabin conditioning under schedule 2";
CM_ SG_ 1466 ChargeUntilFull2_Sts "Charge until battery is fully charged with schedule 2 confirmation";
CM_ SG_ 1466 Do_Not_Repeat2_Sts "Do not repeat the set Schedule confirmation";
CM_ SG_ 1466 End_Time_Hr2_Sts "End Time of schedule  2 (hours in 24 hrs. format) feedback";
CM_ SG_ 1466 End_Time_Min2_Sts "End Time of schedule  2 (Minutes) feedback";
CM_ SG_ 1466 Schedule_Confirmed2 "Confirm the requested schedule 2";
CM_ SG_ 1466 Schedule_Day2_Sts "Scheduled#2 Day for charging or cabin conditioning confirmation";
CM_ SG_ 1466 Schedule_Type2_Sts "Type of charging and climate schedule confirmation";
CM_ SG_ 1466 Start_Time_Hr2_Sts "Start Time of schedule  2(hours in 24 hrs. format) feedback";
CM_ SG_ 1466 Start_Time_Min2_Sts "Start Time of schedule  2 (minutes) feedback";
CM_ SG_ 1467 Batt_CabinPriority3_Sts "Confirmation to the bit to prioritize battery charging or cabin conditioning under schedule 3";
CM_ SG_ 1467 ChargeUntilFull3_Sts "Charge until battery is fully charged with schedule 3 confirmation";
CM_ SG_ 1467 Do_Not_Repeat3_Sts "Do not repeat the set Schedule confirmation";
CM_ SG_ 1467 End_Time_Hr3_Sts "End Time of schedule 3 (hours in 24 hrs. format) feedback";
CM_ SG_ 1467 End_Time_Min3_Sts "End Time of schedule 3 (Minutes) feedback";
CM_ SG_ 1467 Schedule_Confirmed3 "Confirm the requested schedule 3";
CM_ SG_ 1467 Schedule_Day3_Sts "Scheduled#3 Day for charging or cabin conditioning confirmation";
CM_ SG_ 1467 Schedule_Type3_Sts "Type of charging and climate schedule confirmation";
CM_ SG_ 1467 Start_Time_Hr3_Sts "Start Time of schedule 3 (hours in 24 hrs. format) feedback";
CM_ SG_ 1467 Start_Time_Min3_Sts "Start Time of schedule 3 (minutes) feedback";
CM_ SG_ 1840 Next_Charge_End_Time_Hr "End Time of next charge schedule (hours in 24 hrs. format)";
CM_ SG_ 1840 Next_Charge_End_Time_Min "End Time of next charge schedule (Minutes)";
CM_ SG_ 1840 Next_Charge_EndDay "Next Schedule End Day to stop charging";
CM_ SG_ 1840 Next_Charge_Start_Time_Hr "Start Time of next charge schedule (hours in 24 hrs. format)";
CM_ SG_ 1840 Next_Charge_Start_Time_Min "Start Time of next charge schedule (minutes)";
CM_ SG_ 1840 Next_Charge_StartDay "Next Schedule Start Day for charging.";
CM_ SG_ 1840 Next_Climate_Day "Next Climate schedule departure day.";
CM_ SG_ 1840 Next_Climate_Time_Hr "Next Climate schedule departure time (hours in 24 hrs. format).";
CM_ SG_ 1840 Next_Climate_Time_Min "Next Climate schedule departure time (Minutes).";
CM_ SG_ 2147565809 N_PDU "This signal is used for diagnostic purposes";
CM_ SG_ 2147566833 N_PDU "This signal is used for diagnostic purposes";
CM_ SG_ 2147560177 N_PDU "This signal is used for diagnostic purposes";
CM_ SG_ 2147566321 N_PDU "This signal is used for diagnostic purposes";
CM_ SG_ 2147569905 N_PDU "This signal is used for diagnostic purposes";
CM_ SG_ 2147574001 N_PDU "-";
CM_ SG_ 2147569649 N_PDU "This signal is used for diagnostic purposes";
CM_ SG_ 2147601393 N_PDU "This signal is used for diagnostic purposes";
CM_ SG_ 2147557361 N_PDU "This signal is used for diagnostic purposes.";
CM_ SG_ 2147600113 N_PDU "This signal is used for diagnostic purposes";
CM_ SG_ 2147571441 N_PDU "This signal is used for diagnostic purposes";
CM_ SG_ 2147571697 N_PDU "This signal is used for diagnostic purposes";
CM_ SG_ 1457 Batt_CabinPriority1 "Bit to prioritize cabin conditioning under schedule 1";
CM_ SG_ 1457 ChargeUntilFull1 "Charge until battery is fully charged with schedule 1";
CM_ SG_ 1457 Do_Not_Repeat1 "Do not repeat the set Schedule";
CM_ SG_ 1457 Enable_Schedule1 "Schedule 1 checkbox enabled";
CM_ SG_ 1457 End_Time_Hr1 "End Time of schedule 1 (hours in 24 hrs. format)";
CM_ SG_ 1457 End_Time_Min1 "End Time of schedule 1(Minutes)";
CM_ SG_ 1457 Schedule_Day1 "Schedule#1 Day for charging or cabin conditioning";
CM_ SG_ 1457 Schedule_Type1 "Type of charging and climate schedule";
CM_ SG_ 1457 Start_Time_Hr1 "Start Time of schedule  1 (hours in 24 hrs. format)";
CM_ SG_ 1457 Start_Time_Min1 "Start Time of schedule  1 (minutes)";
CM_ SG_ 1457 Submit_Schedule1 "Schedule 1 submitted";
CM_ SG_ 1458 Batt_CabinPriority2 "Bit to prioritize battery charging or cabin conditioning under schedule 2";
CM_ SG_ 1458 ChargeUntilFull2 "Charge until battery is fully charged with schedule 2";
CM_ SG_ 1458 Do_Not_Repeat2 "Do not repeat the set Schedule";
CM_ SG_ 1458 Enable_Schedule2 "Schedule 2 checkbox enabled";
CM_ SG_ 1458 End_Time_Hr2 "End Time of schedule  2 (hours in 24 hrs. format)";
CM_ SG_ 1458 End_Time_Min2 "End Time of schedule  2(Minutes)";
CM_ SG_ 1458 Schedule_Day2 "Schedule#2 Day for charging or cabin conditioning";
CM_ SG_ 1458 Schedule_Type2 "Type of charging and climate schedule";
CM_ SG_ 1458 Start_Time_Hr2 "Start Time of schedule  2(hours in 24 hrs. format)";
CM_ SG_ 1458 Start_Time_Min2 "Start Time of schedule  2 (minutes)";
CM_ SG_ 1458 Submit_Schedule2 "Schedule 2 submitted";
CM_ SG_ 1459 Batt_CabinPriority3 "Bit to prioritize battery charging or cabin conditioning under schedule 3";
CM_ SG_ 1459 ChargeUntilFull3 "Charge until battery is fully charged with schedule 3";
CM_ SG_ 1459 Do_Not_Repeat3 "Do not repeat the set Schedule";
CM_ SG_ 1459 Enable_Schedule3 "Schedule 3 checkbox enabled";
CM_ SG_ 1459 End_Time_Hr3 "End Time of schedule  3 (hours in 24 hrs. format)";
CM_ SG_ 1459 End_Time_Min3 "End Time of schedule  3 (Minutes)";
CM_ SG_ 1459 Schedule_Day3 "Schedule#3 Day for charging or cabin conditioning";
CM_ SG_ 1459 Schedule_Type3 "Type of charging and climate schedule";
CM_ SG_ 1459 Start_Time_Hr3 "Start Time of schedule  3 (hours in 24 hrs. format)";
CM_ SG_ 1459 Start_Time_Min3 "Start Time of schedule  3 (minutes)";
CM_ SG_ 1459 Submit_Schedule3 "Schedule 3 submitted";
CM_ SG_ 1904 DEFROST_SEL "Defrost select switch";
CM_ SG_ 1904 DRV_TEMP_DR_POS "Driver temperature door postion";
CM_ SG_ 1904 EvapTempTar "Evaporator temperature target";
CM_ SG_ 1904 HtrCorTmp_InTgt "Heater core temp target";
CM_ SG_ 1904 HVAC_Blwr_Perct "HVAC blower PWM percentage for service mode";
CM_ SG_ 1904 VEH_INT_TEMP "Vehicle interior temperature";
CM_ SG_ 1933 HVBatCellVltMax "Max cell voltage";
CM_ SG_ 1934 ACSideCurr "AC side current";
CM_ SG_ 1934 ACSideVolt "AC side voltage";
CM_ SG_ 1934 APM_FailureReason "FailureReason";
CM_ SG_ 1934 APM_OperModeStatus "APM Operation  mode  Status";
CM_ SG_ 1934 APM_OutputPower "APM output power";
CM_ SG_ 1939 APMPerfWrn "APM performance warning";
CM_ SG_ 1939 APMTempWrn "APM temperature warning";
CM_ SG_ 1939 HighestWarnLevel "Highest warning level detected";
CM_ SG_ 100 ControlEncodingReq "This signal is used for IMMO communication";
CM_ SG_ 100 f1_1 "This signal is used for IMMO communication";
CM_ SG_ 100 f1_2 "This signal is used for IMMO communication";
CM_ SG_ 100 rnd_1 "This signal is used for IMMO communication";
CM_ SG_ 100 rnd_2 "This signal is used for IMMO communication";
CM_ SG_ 100 rnd_3 "This signal is used for IMMO communication";
CM_ SG_ 100 rnd_4 "This signal is used for IMMO communication";
CM_ SG_ 104 ControlEncodingRsp "This signal is used for IMMO communication";
CM_ SG_ 104 MKKey_3 "This signal is used for IMMO communication";
CM_ SG_ 104 MKKey_4 "This signal is used for IMMO communication";
CM_ SG_ 104 MKKey_5 "This signal is used for IMMO communication";
CM_ SG_ 104 MKKey_6 "This signal is used for IMMO communication";
CM_ SG_ 104 MKKey1org21 "This signal is used for IMMO communication";
CM_ SG_ 104 MKKey2org22 "This signal is used for IMMO communication";
CM_ SG_ 346 CRC_II "CRC according to SAE J1850 standard that has to be calculated from bit 63 to bit 8 at each frame transmission.";
CM_ SG_ 346 IMPACT_A "Front Pretensioner Event";
CM_ SG_ 346 IMPACT_B "EARS Rear Event";
CM_ SG_ 346 IMPACT_C "EARS Higher Severity Front Event";
CM_ SG_ 346 IMPACT_D "Less Severe Side Event";
CM_ SG_ 346 IMPACT_E "Rear Event";
CM_ SG_ 346 IMPACT_F "EARS Lower Severity Front Event";
CM_ SG_ 346 IMPACT_G "Not Used";
CM_ SG_ 346 IMPACT_H "Non-EARS RolloverEvent";
CM_ SG_ 346 IMPACT_I "EARS RolloverEvent";
CM_ SG_ 346 IMPACT_K "EARS Driver/Left Side Event";
CM_ SG_ 346 IMPACT_L "EARS Side Event";
CM_ SG_ 346 IMPACT_M "EARS Passenger/Right Side Event";
CM_ SG_ 346 IMPACT_O "Pedestrain Crash Event";
CM_ SG_ 346 IMPACTCommand "This signal is used to indicate that a crash happened";
CM_ SG_ 346 IMPACTConfirm "This signal is used to confirm that a crash happened";
CM_ SG_ 346 IMPACTFailSts "This signal is used to inform that an internal fault is present in the ORC";
CM_ SG_ 346 MessageCounter_II "This signal is a counter used for safety checks strategies. This counter is incremented of 1 (one) unit at each frame transmission.";
CM_ SG_ 1058 CurrBattFailStatus "Signal about the IBS3";
CM_ SG_ 1058 IBS3_Error_Internal "Signal about the IBS3";
CM_ SG_ 1058 IBS3_Flag_Disconnect "Signal about the IBS3";
CM_ SG_ 1058 IBS3_Ibatt "Signal about the IBS3";
CM_ SG_ 1058 IBS3_Rbatt "Signal about the IBS3";
CM_ SG_ 1058 IBS3_Rbatt_25 "Signal about the IBS3";
CM_ SG_ 1058 IBS3_SOF_V_Accuracy "Signal about the IBS3";
CM_ SG_ 1058 IBS3_SOF_VC "Signal about the IBS3";
CM_ SG_ 1058 IBS3_Vbatt "Signal about the IBS3";
CM_ SG_ 1058 RsErrIBS3 "Signal about the IBS3";
CM_ SG_ 1058 VoltBattFailStatus "Signal about the IBS3";
CM_ SG_ 1060 IBS3_SOC "Signal about the IBS3";
CM_ SG_ 1060 IBS3_SOC_Accuracy "Signal about the IBS3";
CM_ SG_ 1060 IBS3_SOF_Q "Signal about the IBS3";
CM_ SG_ 1060 IBS3_SOF_Q_Accuracy "Signal about the IBS3";
CM_ SG_ 1060 IBS3_SOH_Q "Signal about the IBS3";
CM_ SG_ 1060 IBS3_SOH_Q_Accuracy "Signal about the IBS3";
CM_ SG_ 1060 IBS3_T_BATT "Signal about the IBS3";
CM_ SG_ 1060 IBS3_TempFailStatus "Signal about the IBS3";
CM_ SG_ 1062 IBS3_Q_Received "Signal about the IBS3";
CM_ SG_ 1062 IBS3_Q_Released "Signal about the IBS3";
CM_ SG_ 1062 IBS3_TmLstResetDays "Signal about the IBS3";
CM_ SG_ 1062 IBS3_TmLstResetSec "Signal about the IBS3";
CM_ SG_ 753 LatAcceleration "This signal indicates the Lateral Acceleration Value";
CM_ SG_ 753 LatAccelerationFailSts "This signal indicates the status of Lateral acceleration signal";
CM_ SG_ 753 LongAcceleration "This signal indicates the Longitudinal Acceleration Value";
CM_ SG_ 753 LongAccelerationFailSts "This signal indicates the status of Longitudinal acceleration signal";
CM_ SG_ 753 ZAcceleration "This signal indicates the Z Acceleration Value";
CM_ SG_ 753 ZAccelerationFailSts "This signal indicates the status of Z acceleration signal";
CM_ SG_ 1848 MsgFOBLeftVeh "FOB left vehicle";
CM_ SG_ 1848 MsgFOBNotFnd "FOB Not Detected.";
CM_ SG_ 1848 MsgParkSoon "Signal used to activate the indication for soon Park position insertion.";
CM_ SG_ 1848 StartButtonFailSts "This signal is used to inform about the fail status of stop start button.";
CM_ SG_ 762 ACC_DistSwDec "ACC distance switch decrement";
CM_ SG_ 762 ACC_DistSwInc "ACC distance switch increment";
CM_ SG_ 762 ACC_On "ACC on/off";
CM_ SG_ 762 AcceleratorSts "This signal is used to give information about cruise control accelerator button activation.";
CM_ SG_ 762 CRC_CSWC_1 "CRC according to SAE J1850 standard that has to be calculated from bit 63 to bit 48 at each frame transmission.";
CM_ SG_ 762 CruiseControlFailSts "This signal is used to give information about a fault on cruise control commands.";
CM_ SG_ 762 CruiseControlOnOffSts "This signal is used to give information about cruise control on/off button activation.";
CM_ SG_ 762 CrusCnclSwitch "Cruise Switch:  Cancel Pressed.";
CM_ SG_ 762 DeceleratorSts "This signal is used to give information about cruise control decelerator button activation.";
CM_ SG_ 762 LaneCenteringOnOffSts "This signal is used to give information about Lane Centering on/off button activation.";
CM_ SG_ 762 MC_CSWC_1 "This signal is a counter used for safety checks strategies. This counter is incremented of 1 (one) unit at each frame transmission.";
CM_ SG_ 762 ResumeSwitch "This signal is used to give information about cruise control RESUME button activation.";
CM_ SG_ 762 SpeedLimiterOnOffSts "The signal is sent from SCCM to the ECM for turning the Speed Limter Function ON and OFF.";
CM_ SG_ 2654339129 CurrentFailSts_DASM "The signal indicates that a present fault exists on node";
CM_ SG_ 2654339129 DES_DASM "The signal indicates the CAN Controller status";
CM_ SG_ 2654339129 EOL_DASM "This signal indicates if it is required/not required to the node to partecipate to the PROXI procedure.";
CM_ SG_ 2654339129 GenericFailSts_DASM "The signal indicates that one or more cells containing fault information exist on node memory.";
CM_ SG_ 2654339136 CurrentFailSts_EVCU "The signal indicates that a present fault exists on node";
CM_ SG_ 2654339136 DES_EVCU "The signal indicates the CAN Controller status";
CM_ SG_ 2654339136 EOL_EVCU "This signal indicates if it is required/not required to the node to partecipate to the PROXI procedure.";
CM_ SG_ 2654339136 GenericFailSts_EVCU "The signal indicates that one or more cells containing fault information exist on node memory.";
CM_ SG_ 2654339075 CurrentFailSts_IPC "The signal indicates that a present fault exists on node";
CM_ SG_ 2654339075 DES_IPC "The signal indicates the CAN Controller status";
CM_ SG_ 2654339075 EOL_IPC "This signal indicates if it is required/not required to the node to partecipate to the PROXI procedure.";
CM_ SG_ 2654339075 GenericFailSts_IPC "The signal indicates that one or more cells containing fault information exist on node memory.";
CM_ SG_ 2654339094 CurrentFailSts_Shifter "The signal indicates that a present fault exists on node";
CM_ SG_ 2654339094 DES_Shifter "The signal indicates the CAN Controller status";
CM_ SG_ 2654339094 EOL_Shifter "This signal indicates if it is required/not required to the node to partecipate to the PROXI procedure.";
CM_ SG_ 2654339094 GenericFailSts_Shifter "The signal indicates that one or more cells containing fault information exist on node memory.";
CM_ SG_ 2654339107 CurrentFailSts_TBM "The signal indicates that a present fault exists on node";
CM_ SG_ 2654339107 DES_TBM "The signal indicates the CAN Controller status";
CM_ SG_ 2654339107 EOL_TBM "This signal indicates if it is required/not required to the node to partecipate to the PROXI procedure.";
CM_ SG_ 2654339107 GenericFailSts_TBM "The signal indicates that one or more cells containing fault information exist on node memory.";
CM_ SG_ 1504 ClampForce "This signal is used to give information about the EPB Clamp Force";
CM_ SG_ 1504 EPB_HMI_Management "Management IPC/VP pop-up";
CM_ SG_ 1504 EPBAutoAppSts "Status of AutoApply Functionality";
CM_ SG_ 1504 EPBFailureLampReq "This signal is used to request the EPB failure indication";
CM_ SG_ 1504 EPBMaintenanceSts "Status of Maintenance Functionality";
CM_ SG_ 1504 EPBSts "This signal describes the EPB status";
CM_ SG_ 1504 EPBSwitchPosition "This signal is used to give information about the postition of the EPB switch";
CM_ SG_ 896 ReliableOvertaking "This signal indicates the reliability of road sign of overtaking";
CM_ SG_ 896 ReliableTSISign "This signal indicates the reliability of road Sign for TSI";
CM_ SG_ 896 ReliableVehicleSpdLimit "This signal indicates the reliability of inconditional sign of vehicle speed limit";
CM_ SG_ 896 ReliableVehicleSpdLimitCond "This signal indicates the reliability of conditional sign of vehicle speed limit";
CM_ SG_ 896 SignOvertaking "This signal indicates the road sign of no overtaking";
CM_ SG_ 896 SignSupplemOvertaking "This signal indicates the supplementary road sign related to no overtaking";
CM_ SG_ 896 SignSupplemVehicleSpeedLimit "This signal indicates the supplementary road sign  related to vehicle speed limit";
CM_ SG_ 896 SignVehicleSpeedLimit "This signal indicates the road sign of vehicle speed limit";
CM_ SG_ 896 SignVehicleSpeedLimitConditional "This signal indicates the conditional road sign of vehicle speed limit";
CM_ SG_ 896 SpeedLimitFilter "This signal indicates which road sign of vehicle speed limit shall be shown from IPC";
CM_ SG_ 896 TSRSts "This signal indicates the Traffic Sign Recognition status";
CM_ SG_ 1475 TBM_Batt_CabinPriority1 "Bit to prioritize cabin conditioning under schedule 1";
CM_ SG_ 1475 TBM_ChargeUntilFull1 "Charge until battery is fully charged with schedule 1";
CM_ SG_ 1475 TBM_Do_Not_Repeat1 "Do not repeat the set Schedule";
CM_ SG_ 1475 TBM_Enable_Schedule1 "Schedule 1 checkbox enabled";
CM_ SG_ 1475 TBM_End_Time_Hr1 "End Time of schedule 1 (hours in 24 hrs. format)";
CM_ SG_ 1475 TBM_End_Time_Min1 "End Time of schedule 1(Minutes)";
CM_ SG_ 1475 TBM_Schedule_Day1 "Schedule#1 Day for charging or cabin conditioning";
CM_ SG_ 1475 TBM_Schedule_Type1 "Type of charging and climate schedule";
CM_ SG_ 1475 TBM_Start_Time_Hr1 "Start Time of schedule  1 (hours in 24 hrs. format)";
CM_ SG_ 1475 TBM_Start_Time_Min1 "Start Time of schedule  1 (minutes)";
CM_ SG_ 1475 TBM_Submit_Schedule1 "Schedule 1 submitted";
CM_ SG_ 1473 TBM_Batt_CabinPriority2 "Bit to prioritize battery charging or cabin conditioning under schedule 2";
CM_ SG_ 1473 TBM_ChargeUntilFull2 "Charge until battery is fully charged with schedule 2";
CM_ SG_ 1473 TBM_Do_Not_Repeat2 "Do not repeat the set Schedule";
CM_ SG_ 1473 TBM_Enable_Schedule2 "Schedule 2 checkbox enabled";
CM_ SG_ 1473 TBM_End_Time_Hr2 "End Time of schedule  2 (hours in 24 hrs. format)";
CM_ SG_ 1473 TBM_End_Time_Min2 "End Time of schedule  2(Minutes)";
CM_ SG_ 1473 TBM_Schedule_Day2 "Schedule#2 Day for charging or cabin conditioning";
CM_ SG_ 1473 TBM_Schedule_Type2 "Type of charging and climate schedule";
CM_ SG_ 1473 TBM_Start_Time_Hr2 "Start Time of schedule  2(hours in 24 hrs. format)";
CM_ SG_ 1473 TBM_Start_Time_Min2 "Start Time of schedule  2 (minutes)";
CM_ SG_ 1473 TBM_Submit_Schedule2 "Schedule 2 submitted";
CM_ SG_ 1474 TBM_Batt_CabinPriority3 "Bit to prioritize battery charging or cabin conditioning under schedule 3";
CM_ SG_ 1474 TBM_ChargeUntilFull3 "Charge until battery is fully charged with schedule 3";
CM_ SG_ 1474 TBM_Do_Not_Repeat3 "Do not repeat the set Schedule";
CM_ SG_ 1474 TBM_Enable_Schedule3 "Schedule 3 checkbox enabled";
CM_ SG_ 1474 TBM_End_Time_Hr3 "End Time of schedule  3 (hours in 24 hrs. format)";
CM_ SG_ 1474 TBM_End_Time_Min3 "End Time of schedule  3 (Minutes)";
CM_ SG_ 1474 TBM_Schedule_Day3 "Schedule#3 Day for charging or cabin conditioning";
CM_ SG_ 1474 TBM_Schedule_Type3 "Type of charging and climate schedule";
CM_ SG_ 1474 TBM_Start_Time_Hr3 "Start Time of schedule  3 (hours in 24 hrs. format)";
CM_ SG_ 1474 TBM_Start_Time_Min3 "Start Time of schedule  3 (minutes)";
CM_ SG_ 1474 TBM_Submit_Schedule3 "Schedule 3 submitted";
CM_ SG_ 1850 Day1 "It is the first digit of the day for the date visualization";
CM_ SG_ 1850 Day2 "It is the second digit of the day for the date visualization";
CM_ SG_ 1850 Hour1 "It is the first digit of the hours for the clock visualization";
CM_ SG_ 1850 Hour2 "It is the second digit of the hours for the clock visualization";
CM_ SG_ 1850 Minute1 "It is  the first digit of the minutes for the clock visualization";
CM_ SG_ 1850 Minute2 "It is the second digit of the minutes for the clock visualization";
CM_ SG_ 1850 Month1 "It is the first digit of the month for the date visualization";
CM_ SG_ 1850 Month2 "It is the second digit of the month for the date visualization";
CM_ SG_ 1850 Year1 "It is the first digit of the year for the date visualization";
CM_ SG_ 1850 Year2 "It is the second digit of the year for the date visualization";
CM_ SG_ 1850 Year3 "It is the third digit of the year for the date visualization";
CM_ SG_ 1850 Year4 "It is the fourth digit of the year for the date visualization";
CM_ SG_ 1000 CalibrationAck "It indicates the acknoledgment of calibration procedure request.";
CM_ SG_ 1000 CalibrationSts "It indicates the current status of the calibration procedure.";
CM_ SG_ 1448 ShiftLeverPosition "This signal indicates the executed shift lever position.";
CM_ SG_ 344 Vehicle_Hold_Rq "Transmission vehicle hold request";
CM_ SG_ 253 TxpFound "This signal is used to give information about the presence of a transponder";
CM_ SG_ 253 TxpID "This signal is used to give information about the transponder authentication.";
CM_ SG_ 1046 VIN_DATA "VIN Digits (8 bit ascii encoded)";
CM_ SG_ 1046 VIN_MSG "VIN Message Information";
CM_ SG_ 2654208000 MainWakeSts_BCM "Main wakeup status from BCM";
CM_ SG_ 2654208000 Node0 "Node 0 wakeup active";
CM_ SG_ 2654208000 Node1 "Node 1 wakeup active";
CM_ SG_ 2654208000 Node10 "Node 10 wakeup active";
CM_ SG_ 2654208000 Node11 "Node 11 wakeup active";
CM_ SG_ 2654208000 Node12 "Node 12 wakeup active";
CM_ SG_ 2654208000 Node13 "Node 13 wakeup active";
CM_ SG_ 2654208000 Node14 "Node 14 wakeup active";
CM_ SG_ 2654208000 Node15 "Node 15 wakeup active";
CM_ SG_ 2654208000 Node16 "Node 16 wakeup active";
CM_ SG_ 2654208000 Node17 "Node 17 wakeup active";
CM_ SG_ 2654208000 Node18 "Node 18 wakeup active";
CM_ SG_ 2654208000 Node19 "Node 19 wakeup active";
CM_ SG_ 2654208000 Node2 "Node 2 wakeup active";
CM_ SG_ 2654208000 Node20 "Node 20 wakeup active";
CM_ SG_ 2654208000 Node21 "Node 21 wakeup active";
CM_ SG_ 2654208000 Node22 "Node 22 wakeup active";
CM_ SG_ 2654208000 Node23 "Node 23 wakeup active";
CM_ SG_ 2654208000 Node24 "Node 24 wakeup active";
CM_ SG_ 2654208000 Node25 "Node 25 wakeup active";
CM_ SG_ 2654208000 Node26 "Node 26 wakeup active";
CM_ SG_ 2654208000 Node27 "Node 27 wakeup active";
CM_ SG_ 2654208000 Node28 "Node 28 wakeup active";
CM_ SG_ 2654208000 Node29 "Node 29 wakeup active";
CM_ SG_ 2654208000 Node3 "Node 3 wakeup active";
CM_ SG_ 2654208000 Node30 "Node 30 wakeup active";
CM_ SG_ 2654208000 Node31 "Node 31 wakeup active";
CM_ SG_ 2654208000 Node4 "Node 4 wakeup active";
CM_ SG_ 2654208000 Node5 "Node 5 wakeup active";
CM_ SG_ 2654208000 Node6 "Node 6 wakeup active";
CM_ SG_ 2654208000 Node7 "Node 7 wakeup active";
CM_ SG_ 2654208000 Node8 "Node 8 wakeup active";
CM_ SG_ 2654208000 Node9 "Node 9 wakeup active";
CM_ SG_ 2654208000 WakeCntr_BCM "Wakeup counter for BCM";
CM_ SG_ 2654208000 WakeRsn_BCM "Wakeup reason for BCM";
CM_ SG_ 2654208006 WakeCntr_BSM "Wakeup counter for BSM.";
CM_ SG_ 2654208006 WakeReq_BSM "Wakeup request bit for BSM.";
CM_ SG_ 2654208006 WakeRsn_BSM "Wakeup reason for BSM.";
CM_ SG_ 2654208064 WakeCntr_EVCU "Wakeup counter for EVCU";
CM_ SG_ 2654208064 WakeReq_EVCU "Wakeup request bit for EVCU";
CM_ SG_ 2654208064 WakeRsn_EVCU "Wakeup reason for EVCU";
CM_ SG_ 2654208003 WakeCntr_IPC "Wakeup counter for IPC";
CM_ SG_ 2654208003 WakeReq_IPC "Wakeup request bit for IPC";
CM_ SG_ 2654208003 WakeRsn_IPC "Wakeup reason for IPC";
CM_ SG_ 2654208022 WakeCntr_SHIFTER "Wakeup counter for ESM";
CM_ SG_ 2654208022 WakeReq_SHIFTER "Wakeup request bit for ESM";
CM_ SG_ 2654208022 WakeRsn_SHIFTER "Wakeup reason for ESM";
CM_ SG_ 278 CRC_WI "CRC according to SAE J1850 standard that has to be calculated from bit 63 to bit 8 at each frame transmission.";
CM_ SG_ 278 LHF_FastPulseCounter "This signal is the left front wheel pulse counter.";
CM_ SG_ 278 LHF_Spin "This signal indicates the left hand front wheel status";
CM_ SG_ 278 LHF_WheelSensorFailSts "This signal indicates the fail status of LHF sensor";
CM_ SG_ 278 LHR_FastPulseCounter "This signal is the left rear wheel pulse counter.";
CM_ SG_ 278 LHR_Spin "This signal indicates the left hand rear wheel status";
CM_ SG_ 278 LHR_WheelSensorFailSts "This signal indicates the fail status of LHR sensor";
CM_ SG_ 278 MessageCounter_WI "This signal is a counter used for safety checks strategies. This counter is incremented of 1 (one) unit at each frame transmission.";
CM_ SG_ 278 RHF_FastPulseCounter "This signal is the right front wheel pulse counter.";
CM_ SG_ 278 RHF_Spin "This signal indicates the right hand front wheel status";
CM_ SG_ 278 RHF_WheelSensorFailSts "This signal indicates the fail status of RHF sensor";
CM_ SG_ 278 RHR_FastPulseCounter "This signal is the right rear wheel pulse counter.";
CM_ SG_ 278 RHR_Spin "This signal indicates the right hand rear wheel status";
CM_ SG_ 278 RHR_WheelSensorFailSts "This signal indicates the fail status of RHR sensor";
CM_ SG_ 238 CRC_WS "CRC according to SAE J1850 standard that has to be calculated from bit 63 to bit 8 at each frame transmission.";
CM_ SG_ 238 LHFWheelSpeed "This is the value of the left front wheel speed";
CM_ SG_ 238 LHRWheelSpeed "This is the value of the left rear wheel speed";
CM_ SG_ 238 MessageCounter_WS "This signal is a counter used for safety checks strategies. This counter is incremented of 1 (one) unit at each frame transmission.";
CM_ SG_ 238 RHFWheelSpeed "This is the value of the right front wheel speed";
CM_ SG_ 238 RHRWheelSpeed "This is the value of the right rear wheel speed";

BA_DEF_ SG_ "Accuracy" STRING ;
BA_DEF_ SG_ "Event trans." ENUM "Yes","No";
BA_DEF_ SG_ "GenSigStartValue" INT 0 2147483647;
BA_DEF_ SG_ "GenSigInactiveValue" INT 0 2147483647;
BA_DEF_ SG_ "GenSigSendType" ENUM "NotUsed","OnWrite","OnWriteWithRepetition","OnChange","OnChangeWithRepetition","IfActive","IfActiveWithRepetition","NoSigSendType";
BA_DEF_ BO_ "DiagRequest" ENUM "No","Yes";
BA_DEF_ BO_ "Period [ms]" INT 0 65535;
BA_DEF_ BO_ "Type" ENUM "P","C","PE","COC","PE_Cntrl","E","E_Cntrl","OC","S","BAF","DC","EM","MM","-";
BA_DEF_ BO_ "DiagResponse" ENUM "No","Yes";
BA_DEF_ BO_ "NmMessage" ENUM "No","Yes";
BA_DEF_ BO_ "GenMsgSendType" ENUM "Cyclic","NotUsed","NotUsed","NotUsed","NotUsed","NotUsed","NotUsed","NotUsed","NoMsgSendType";
BA_DEF_ BO_ "GenMsgTimeoutTime" INT 0 10000;
BA_DEF_ BO_ "GenMsgNrOfRepetition" INT 0 255;
BA_DEF_ BO_ "GenMsgILSupport" ENUM "No","Yes";
BA_DEF_ BO_ "GenMsgStartDelayTime" INT 0 65535;
BA_DEF_ BO_ "GenMsgCycleTimeFast" INT 0 65535;
BA_DEF_ BO_ "GenMsgCycleTime" INT 0 65535;
BA_DEF_ BO_ "GenMsgDelayTime" INT 0 65535;
BA_DEF_ BO_ "DiagState" ENUM "No","Yes";
BA_DEF_DEF_ "Accuracy" "";
BA_DEF_DEF_ "Event trans." "No";
BA_DEF_DEF_ "GenSigStartValue" 0;
BA_DEF_DEF_ "GenSigInactiveValue" 0;
BA_DEF_DEF_ "GenSigSendType" "NoSigSendType";
BA_DEF_DEF_ "DiagRequest" "No";
BA_DEF_DEF_ "Period [ms]" 0;
BA_DEF_DEF_ "Type" "-";
BA_DEF_DEF_ "DiagResponse" "No";
BA_DEF_DEF_ "NmMessage" "No";
BA_DEF_DEF_ "GenMsgSendType" "NoMsgSendType";
BA_DEF_DEF_ "GenMsgTimeoutTime" 0;
BA_DEF_DEF_ "GenMsgNrOfRepetition" 0;
BA_DEF_DEF_ "GenMsgILSupport" "No";
BA_DEF_DEF_ "GenMsgStartDelayTime" 0;
BA_DEF_DEF_ "GenMsgCycleTimeFast" 0;
BA_DEF_DEF_ "GenMsgCycleTime" 0;
BA_DEF_DEF_ "GenMsgDelayTime" 0;
BA_DEF_DEF_ "DiagState" "No";
BA_ "Period [ms]" BO_ 1466 1000;
BA_ "Type" BO_ 1466 3;
BA_ "GenMsgSendType" BO_ 1466 0;
BA_ "GenMsgILSupport" BO_ 1466 1;
BA_ "GenMsgCycleTime" BO_ 1466 1000;
BA_ "GenMsgDelayTime" BO_ 1466 20;
BA_ "Period [ms]" BO_ 1467 1000;
BA_ "Type" BO_ 1467 3;
BA_ "GenMsgSendType" BO_ 1467 0;
BA_ "GenMsgILSupport" BO_ 1467 1;
BA_ "GenMsgCycleTime" BO_ 1467 1000;
BA_ "GenMsgDelayTime" BO_ 1467 20;
BA_ "Period [ms]" BO_ 1840 1000;
BA_ "Type" BO_ 1840 1;
BA_ "GenMsgSendType" BO_ 1840 0;
BA_ "GenMsgILSupport" BO_ 1840 1;
BA_ "GenMsgCycleTime" BO_ 1840 1000;
BA_ "GenMsgDelayTime" BO_ 1840 20;
BA_ "DiagRequest" BO_ 2147565809 1;
BA_ "Type" BO_ 2147565809 8;
BA_ "DiagRequest" BO_ 2147566833 1;
BA_ "Type" BO_ 2147566833 8;
BA_ "DiagRequest" BO_ 2147560177 1;
BA_ "Type" BO_ 2147560177 8;
BA_ "GenMsgTimeoutTime" BO_ 2147560177 2500;
BA_ "DiagRequest" BO_ 2147566321 1;
BA_ "Type" BO_ 2147566321 8;
BA_ "DiagRequest" BO_ 2147569905 1;
BA_ "Type" BO_ 2147569905 8;
BA_ "DiagRequest" BO_ 2147574001 1;
BA_ "Type" BO_ 2147574001 8;
BA_ "DiagRequest" BO_ 2147569649 1;
BA_ "Type" BO_ 2147569649 8;
BA_ "DiagRequest" BO_ 2147601393 1;
BA_ "Type" BO_ 2147601393 8;
BA_ "GenMsgTimeoutTime" BO_ 2147601393 2500;
BA_ "DiagRequest" BO_ 2147557361 1;
BA_ "Type" BO_ 2147557361 8;
BA_ "DiagRequest" BO_ 2147600113 1;
BA_ "Type" BO_ 2147600113 8;
BA_ "DiagRequest" BO_ 2147571441 1;
BA_ "Type" BO_ 2147571441 8;
BA_ "DiagRequest" BO_ 2147571697 1;
BA_ "Type" BO_ 2147571697 8;
BA_ "Period [ms]" BO_ 1457 1000;
BA_ "Type" BO_ 1457 3;
BA_ "GenMsgSendType" BO_ 1457 0;
BA_ "GenMsgILSupport" BO_ 1457 1;
BA_ "GenMsgCycleTime" BO_ 1457 1000;
BA_ "GenMsgDelayTime" BO_ 1457 20;
BA_ "Period [ms]" BO_ 1458 1000;
BA_ "Type" BO_ 1458 3;
BA_ "GenMsgSendType" BO_ 1458 0;
BA_ "GenMsgILSupport" BO_ 1458 1;
BA_ "GenMsgCycleTime" BO_ 1458 1000;
BA_ "GenMsgDelayTime" BO_ 1458 20;
BA_ "Period [ms]" BO_ 1459 1000;
BA_ "Type" BO_ 1459 3;
BA_ "GenMsgSendType" BO_ 1459 0;
BA_ "GenMsgILSupport" BO_ 1459 1;
BA_ "GenMsgCycleTime" BO_ 1459 1000;
BA_ "GenMsgDelayTime" BO_ 1459 20;
BA_ "Period [ms]" BO_ 1904 1000;
BA_ "Type" BO_ 1904 1;
BA_ "GenMsgSendType" BO_ 1904 0;
BA_ "GenMsgILSupport" BO_ 1904 1;
BA_ "GenMsgCycleTime" BO_ 1904 1000;
BA_ "GenMsgDelayTime" BO_ 1904 20;
BA_ "Period [ms]" BO_ 1933 1000;
BA_ "Type" BO_ 1933 1;
BA_ "GenMsgSendType" BO_ 1933 0;
BA_ "GenMsgTimeoutTime" BO_ 1933 2500;
BA_ "GenMsgILSupport" BO_ 1933 1;
BA_ "GenMsgCycleTime" BO_ 1933 1000;
BA_ "Period [ms]" BO_ 1934 1000;
BA_ "Type" BO_ 1934 1;
BA_ "GenMsgSendType" BO_ 1934 0;
BA_ "GenMsgTimeoutTime" BO_ 1934 2500;
BA_ "GenMsgILSupport" BO_ 1934 1;
BA_ "GenMsgStartDelayTime" BO_ 1934 400;
BA_ "GenMsgCycleTime" BO_ 1934 1000;
BA_ "Period [ms]" BO_ 1939 1000;
BA_ "Type" BO_ 1939 1;
BA_ "GenMsgSendType" BO_ 1939 0;
BA_ "GenMsgTimeoutTime" BO_ 1939 2500;
BA_ "GenMsgILSupport" BO_ 1939 1;
BA_ "GenMsgStartDelayTime" BO_ 1939 400;
BA_ "GenMsgCycleTime" BO_ 1939 1000;
BA_ "Type" BO_ 100 8;
BA_ "GenMsgILSupport" BO_ 100 1;
BA_ "GenMsgDelayTime" BO_ 100 10;
BA_ "Type" BO_ 104 11;
BA_ "GenMsgILSupport" BO_ 104 1;
BA_ "GenMsgDelayTime" BO_ 104 10;
BA_ "Period [ms]" BO_ 346 500;
BA_ "Type" BO_ 346 10;
BA_ "GenMsgSendType" BO_ 346 0;
BA_ "GenMsgILSupport" BO_ 346 1;
BA_ "GenMsgStartDelayTime" BO_ 346 500;
BA_ "GenMsgCycleTimeFast" BO_ 346 10;
BA_ "GenMsgCycleTime" BO_ 346 500;
BA_ "GenMsgDelayTime" BO_ 346 10;
BA_ "Period [ms]" BO_ 1058 100;
BA_ "Type" BO_ 1058 1;
BA_ "GenMsgSendType" BO_ 1058 0;
BA_ "GenMsgILSupport" BO_ 1058 1;
BA_ "GenMsgCycleTime" BO_ 1058 100;
BA_ "Period [ms]" BO_ 1060 100;
BA_ "Type" BO_ 1060 1;
BA_ "GenMsgSendType" BO_ 1060 0;
BA_ "GenMsgILSupport" BO_ 1060 1;
BA_ "GenMsgCycleTime" BO_ 1060 100;
BA_ "Period [ms]" BO_ 1062 100;
BA_ "Type" BO_ 1062 1;
BA_ "GenMsgSendType" BO_ 1062 0;
BA_ "GenMsgILSupport" BO_ 1062 1;
BA_ "GenMsgCycleTime" BO_ 1062 100;
BA_ "Period [ms]" BO_ 256 10;
BA_ "Type" BO_ 256 1;
BA_ "GenMsgSendType" BO_ 256 0;
BA_ "GenMsgILSupport" BO_ 256 1;
BA_ "GenMsgStartDelayTime" BO_ 256 6;
BA_ "GenMsgCycleTime" BO_ 256 10;
BA_ "Period [ms]" BO_ 500 20;
BA_ "Type" BO_ 500 1;
BA_ "GenMsgSendType" BO_ 500 0;
BA_ "GenMsgILSupport" BO_ 500 1;
BA_ "GenMsgStartDelayTime" BO_ 500 10;
BA_ "GenMsgCycleTime" BO_ 500 20;
BA_ "Period [ms]" BO_ 753 50;
BA_ "Type" BO_ 753 1;
BA_ "GenMsgSendType" BO_ 753 0;
BA_ "GenMsgILSupport" BO_ 753 1;
BA_ "GenMsgStartDelayTime" BO_ 753 20;
BA_ "GenMsgCycleTime" BO_ 753 50;
BA_ "Period [ms]" BO_ 1848 1000;
BA_ "Type" BO_ 1848 3;
BA_ "GenMsgSendType" BO_ 1848 0;
BA_ "GenMsgILSupport" BO_ 1848 1;
BA_ "GenMsgStartDelayTime" BO_ 1848 500;
BA_ "GenMsgCycleTime" BO_ 1848 1000;
BA_ "GenMsgDelayTime" BO_ 1848 20;
BA_ "Period [ms]" BO_ 400 50;
BA_ "Type" BO_ 400 3;
BA_ "GenMsgSendType" BO_ 400 0;
BA_ "GenMsgILSupport" BO_ 400 1;
BA_ "GenMsgCycleTime" BO_ 400 50;
BA_ "GenMsgDelayTime" BO_ 400 10;
BA_ "Type" BO_ 762 11;
BA_ "GenMsgTimeoutTime" BO_ 762 2500;
BA_ "GenMsgILSupport" BO_ 762 1;
BA_ "Period [ms]" BO_ 2654339129 1000;
BA_ "Type" BO_ 2654339129 1;
BA_ "GenMsgSendType" BO_ 2654339129 0;
BA_ "GenMsgTimeoutTime" BO_ 2654339129 2500;
BA_ "GenMsgILSupport" BO_ 2654339129 1;
BA_ "GenMsgStartDelayTime" BO_ 2654339129 500;
BA_ "GenMsgCycleTime" BO_ 2654339129 1000;
BA_ "Period [ms]" BO_ 2654339136 1000;
BA_ "Type" BO_ 2654339136 1;
BA_ "GenMsgSendType" BO_ 2654339136 0;
BA_ "GenMsgTimeoutTime" BO_ 2654339136 2500;
BA_ "GenMsgILSupport" BO_ 2654339136 1;
BA_ "GenMsgCycleTime" BO_ 2654339136 1000;
BA_ "Period [ms]" BO_ 2654339075 1000;
BA_ "Type" BO_ 2654339075 1;
BA_ "GenMsgSendType" BO_ 2654339075 0;
BA_ "GenMsgTimeoutTime" BO_ 2654339075 2500;
BA_ "GenMsgILSupport" BO_ 2654339075 1;
BA_ "GenMsgStartDelayTime" BO_ 2654339075 250;
BA_ "GenMsgCycleTime" BO_ 2654339075 1000;
BA_ "Period [ms]" BO_ 2654339094 1000;
BA_ "Type" BO_ 2654339094 1;
BA_ "GenMsgSendType" BO_ 2654339094 0;
BA_ "GenMsgTimeoutTime" BO_ 2654339094 2500;
BA_ "GenMsgILSupport" BO_ 2654339094 1;
BA_ "GenMsgStartDelayTime" BO_ 2654339094 500;
BA_ "GenMsgCycleTime" BO_ 2654339094 1000;
BA_ "Period [ms]" BO_ 2654339107 1000;
BA_ "Type" BO_ 2654339107 1;
BA_ "GenMsgSendType" BO_ 2654339107 0;
BA_ "GenMsgTimeoutTime" BO_ 2654339107 2500;
BA_ "GenMsgILSupport" BO_ 2654339107 1;
BA_ "GenMsgCycleTime" BO_ 2654339107 1000;
BA_ "Period [ms]" BO_ 1504 250;
BA_ "Type" BO_ 1504 10;
BA_ "GenMsgSendType" BO_ 1504 0;
BA_ "GenMsgILSupport" BO_ 1504 1;
BA_ "GenMsgStartDelayTime" BO_ 1504 130;
BA_ "GenMsgCycleTimeFast" BO_ 1504 20;
BA_ "GenMsgCycleTime" BO_ 1504 250;
BA_ "GenMsgDelayTime" BO_ 1504 10;
BA_ "Period [ms]" BO_ 1941 1000;
BA_ "Type" BO_ 1941 1;
BA_ "GenMsgSendType" BO_ 1941 0;
BA_ "GenMsgILSupport" BO_ 1941 1;
BA_ "GenMsgStartDelayTime" BO_ 1941 400;
BA_ "GenMsgCycleTime" BO_ 1941 1000;
BA_ "GenMsgDelayTime" BO_ 1941 20;
BA_ "Type" BO_ 896 11;
BA_ "GenMsgILSupport" BO_ 896 1;
BA_ "GenMsgDelayTime" BO_ 896 10;
BA_ "Period [ms]" BO_ 1475 1000;
BA_ "Type" BO_ 1475 3;
BA_ "GenMsgSendType" BO_ 1475 0;
BA_ "GenMsgTimeoutTime" BO_ 1475 2500;
BA_ "GenMsgILSupport" BO_ 1475 1;
BA_ "GenMsgCycleTime" BO_ 1475 1000;
BA_ "GenMsgDelayTime" BO_ 1475 20;
BA_ "Period [ms]" BO_ 1473 1000;
BA_ "Type" BO_ 1473 3;
BA_ "GenMsgSendType" BO_ 1473 0;
BA_ "GenMsgTimeoutTime" BO_ 1473 2500;
BA_ "GenMsgILSupport" BO_ 1473 1;
BA_ "GenMsgCycleTime" BO_ 1473 1000;
BA_ "GenMsgDelayTime" BO_ 1473 20;
BA_ "Period [ms]" BO_ 1474 1000;
BA_ "Type" BO_ 1474 3;
BA_ "GenMsgSendType" BO_ 1474 0;
BA_ "GenMsgTimeoutTime" BO_ 1474 2500;
BA_ "GenMsgILSupport" BO_ 1474 1;
BA_ "GenMsgCycleTime" BO_ 1474 1000;
BA_ "GenMsgDelayTime" BO_ 1474 20;
BA_ "Period [ms]" BO_ 1850 1000;
BA_ "Type" BO_ 1850 3;
BA_ "GenMsgSendType" BO_ 1850 0;
BA_ "GenMsgILSupport" BO_ 1850 1;
BA_ "GenMsgStartDelayTime" BO_ 1850 750;
BA_ "GenMsgCycleTime" BO_ 1850 1000;
BA_ "GenMsgDelayTime" BO_ 1850 20;
BA_ "Type" BO_ 1000 9;
BA_ "GenMsgNrOfRepetition" BO_ 1000 3;
BA_ "GenMsgILSupport" BO_ 1000 1;
BA_ "GenMsgCycleTimeFast" BO_ 1000 500;
BA_ "GenMsgDelayTime" BO_ 1000 10;
BA_ "Period [ms]" BO_ 1448 1000;
BA_ "Type" BO_ 1448 3;
BA_ "GenMsgSendType" BO_ 1448 0;
BA_ "GenMsgILSupport" BO_ 1448 1;
BA_ "GenMsgCycleTime" BO_ 1448 1000;
BA_ "GenMsgDelayTime" BO_ 1448 20;
BA_ "Period [ms]" BO_ 344 500;
BA_ "Type" BO_ 344 10;
BA_ "GenMsgSendType" BO_ 344 0;
BA_ "GenMsgNrOfRepetition" BO_ 344 3;
BA_ "GenMsgILSupport" BO_ 344 1;
BA_ "GenMsgCycleTimeFast" BO_ 344 10;
BA_ "GenMsgCycleTime" BO_ 344 500;
BA_ "GenMsgDelayTime" BO_ 344 10;
BA_ "Type" BO_ 253 8;
BA_ "GenMsgTimeoutTime" BO_ 253 2500;
BA_ "GenMsgILSupport" BO_ 253 1;
BA_ "GenMsgDelayTime" BO_ 253 10;
BA_ "Period [ms]" BO_ 1046 100;
BA_ "Type" BO_ 1046 1;
BA_ "GenMsgSendType" BO_ 1046 0;
BA_ "GenMsgILSupport" BO_ 1046 1;
BA_ "GenMsgStartDelayTime" BO_ 1046 40;
BA_ "GenMsgCycleTime" BO_ 1046 100;
BA_ "Period [ms]" BO_ 2654208000 200;
BA_ "Type" BO_ 2654208000 3;
BA_ "NmMessage" BO_ 2654208000 1;
BA_ "GenMsgSendType" BO_ 2654208000 0;
BA_ "GenMsgTimeoutTime" BO_ 2654208000 2500;
BA_ "GenMsgCycleTime" BO_ 2654208000 200;
BA_ "GenMsgDelayTime" BO_ 2654208000 10;
BA_ "Type" BO_ 2654208006 8;
BA_ "NmMessage" BO_ 2654208006 1;
BA_ "GenMsgDelayTime" BO_ 2654208006 10;
BA_ "Type" BO_ 2654208064 8;
BA_ "NmMessage" BO_ 2654208064 1;
BA_ "GenMsgDelayTime" BO_ 2654208064 10;
BA_ "Type" BO_ 2654208003 8;
BA_ "NmMessage" BO_ 2654208003 1;
BA_ "GenMsgTimeoutTime" BO_ 2654208003 2500;
BA_ "GenMsgDelayTime" BO_ 2654208003 10;
BA_ "Type" BO_ 2654208022 8;
BA_ "NmMessage" BO_ 2654208022 1;
BA_ "GenMsgDelayTime" BO_ 2654208022 10;
BA_ "Period [ms]" BO_ 278 10;
BA_ "Type" BO_ 278 1;
BA_ "GenMsgSendType" BO_ 278 0;
BA_ "GenMsgILSupport" BO_ 278 1;
BA_ "GenMsgStartDelayTime" BO_ 278 10;
BA_ "GenMsgCycleTime" BO_ 278 10;
BA_ "Period [ms]" BO_ 238 10;
BA_ "Type" BO_ 238 1;
BA_ "GenMsgSendType" BO_ 238 0;
BA_ "GenMsgILSupport" BO_ 238 1;
BA_ "GenMsgCycleTime" BO_ 238 10;
BA_ "Event trans." SG_ 1466 Batt_CabinPriority2_Sts 0;
BA_ "GenSigSendType" SG_ 1466 Batt_CabinPriority2_Sts 3;
BA_ "Event trans." SG_ 1466 ChargeUntilFull2_Sts 0;
BA_ "GenSigSendType" SG_ 1466 ChargeUntilFull2_Sts 3;
BA_ "Event trans." SG_ 1466 Do_Not_Repeat2_Sts 0;
BA_ "GenSigSendType" SG_ 1466 Do_Not_Repeat2_Sts 3;
BA_ "Event trans." SG_ 1466 End_Time_Hr2_Sts 0;
BA_ "GenSigSendType" SG_ 1466 End_Time_Hr2_Sts 3;
BA_ "Event trans." SG_ 1466 End_Time_Min2_Sts 0;
BA_ "GenSigSendType" SG_ 1466 End_Time_Min2_Sts 3;
BA_ "Event trans." SG_ 1466 Schedule_Confirmed2 0;
BA_ "GenSigSendType" SG_ 1466 Schedule_Confirmed2 3;
BA_ "Event trans." SG_ 1466 Schedule_Day2_Sts 0;
BA_ "GenSigSendType" SG_ 1466 Schedule_Day2_Sts 3;
BA_ "Event trans." SG_ 1466 Schedule_Type2_Sts 0;
BA_ "GenSigSendType" SG_ 1466 Schedule_Type2_Sts 3;
BA_ "Event trans." SG_ 1466 Start_Time_Hr2_Sts 0;
BA_ "GenSigSendType" SG_ 1466 Start_Time_Hr2_Sts 3;
BA_ "Event trans." SG_ 1466 Start_Time_Min2_Sts 0;
BA_ "GenSigSendType" SG_ 1466 Start_Time_Min2_Sts 3;
BA_ "Event trans." SG_ 1467 Batt_CabinPriority3_Sts 0;
BA_ "GenSigSendType" SG_ 1467 Batt_CabinPriority3_Sts 3;
BA_ "Event trans." SG_ 1467 ChargeUntilFull3_Sts 0;
BA_ "GenSigSendType" SG_ 1467 ChargeUntilFull3_Sts 3;
BA_ "Event trans." SG_ 1467 Do_Not_Repeat3_Sts 0;
BA_ "GenSigSendType" SG_ 1467 Do_Not_Repeat3_Sts 3;
BA_ "Event trans." SG_ 1467 End_Time_Hr3_Sts 0;
BA_ "GenSigSendType" SG_ 1467 End_Time_Hr3_Sts 3;
BA_ "Event trans." SG_ 1467 End_Time_Min3_Sts 0;
BA_ "GenSigSendType" SG_ 1467 End_Time_Min3_Sts 3;
BA_ "Event trans." SG_ 1467 Schedule_Confirmed3 0;
BA_ "GenSigSendType" SG_ 1467 Schedule_Confirmed3 3;
BA_ "Event trans." SG_ 1467 Schedule_Day3_Sts 0;
BA_ "GenSigSendType" SG_ 1467 Schedule_Day3_Sts 3;
BA_ "Event trans." SG_ 1467 Schedule_Type3_Sts 0;
BA_ "GenSigSendType" SG_ 1467 Schedule_Type3_Sts 3;
BA_ "Event trans." SG_ 1467 Start_Time_Hr3_Sts 0;
BA_ "GenSigSendType" SG_ 1467 Start_Time_Hr3_Sts 3;
BA_ "Event trans." SG_ 1467 Start_Time_Min3_Sts 0;
BA_ "GenSigSendType" SG_ 1467 Start_Time_Min3_Sts 3;
BA_ "Accuracy" SG_ 2147574001 N_PDU "-";
BA_ "Event trans." SG_ 1457 Batt_CabinPriority1 0;
BA_ "GenSigSendType" SG_ 1457 Batt_CabinPriority1 3;
BA_ "Event trans." SG_ 1457 ChargeUntilFull1 0;
BA_ "GenSigSendType" SG_ 1457 ChargeUntilFull1 3;
BA_ "Event trans." SG_ 1457 Do_Not_Repeat1 0;
BA_ "GenSigSendType" SG_ 1457 Do_Not_Repeat1 3;
BA_ "Event trans." SG_ 1457 Enable_Schedule1 0;
BA_ "GenSigSendType" SG_ 1457 Enable_Schedule1 3;
BA_ "Event trans." SG_ 1457 End_Time_Hr1 0;
BA_ "GenSigSendType" SG_ 1457 End_Time_Hr1 3;
BA_ "Event trans." SG_ 1457 End_Time_Min1 0;
BA_ "GenSigSendType" SG_ 1457 End_Time_Min1 3;
BA_ "Event trans." SG_ 1457 Schedule_Day1 0;
BA_ "GenSigSendType" SG_ 1457 Schedule_Day1 3;
BA_ "Event trans." SG_ 1457 Schedule_Type1 0;
BA_ "GenSigSendType" SG_ 1457 Schedule_Type1 3;
BA_ "Event trans." SG_ 1457 Start_Time_Hr1 0;
BA_ "GenSigSendType" SG_ 1457 Start_Time_Hr1 3;
BA_ "Event trans." SG_ 1457 Start_Time_Min1 0;
BA_ "GenSigSendType" SG_ 1457 Start_Time_Min1 3;
BA_ "Event trans." SG_ 1457 Submit_Schedule1 0;
BA_ "GenSigSendType" SG_ 1457 Submit_Schedule1 3;
BA_ "Event trans." SG_ 1458 Batt_CabinPriority2 0;
BA_ "GenSigSendType" SG_ 1458 Batt_CabinPriority2 3;
BA_ "Event trans." SG_ 1458 ChargeUntilFull2 0;
BA_ "GenSigSendType" SG_ 1458 ChargeUntilFull2 3;
BA_ "Event trans." SG_ 1458 Do_Not_Repeat2 0;
BA_ "GenSigSendType" SG_ 1458 Do_Not_Repeat2 3;
BA_ "Event trans." SG_ 1458 Enable_Schedule2 0;
BA_ "GenSigSendType" SG_ 1458 Enable_Schedule2 3;
BA_ "Event trans." SG_ 1458 End_Time_Hr2 0;
BA_ "GenSigSendType" SG_ 1458 End_Time_Hr2 3;
BA_ "Event trans." SG_ 1458 End_Time_Min2 0;
BA_ "GenSigSendType" SG_ 1458 End_Time_Min2 3;
BA_ "Event trans." SG_ 1458 Schedule_Day2 0;
BA_ "GenSigSendType" SG_ 1458 Schedule_Day2 3;
BA_ "Event trans." SG_ 1458 Schedule_Type2 0;
BA_ "GenSigSendType" SG_ 1458 Schedule_Type2 3;
BA_ "Event trans." SG_ 1458 Start_Time_Hr2 0;
BA_ "GenSigSendType" SG_ 1458 Start_Time_Hr2 3;
BA_ "Event trans." SG_ 1458 Start_Time_Min2 0;
BA_ "GenSigSendType" SG_ 1458 Start_Time_Min2 3;
BA_ "Event trans." SG_ 1458 Submit_Schedule2 0;
BA_ "GenSigSendType" SG_ 1458 Submit_Schedule2 3;
BA_ "Event trans." SG_ 1459 Batt_CabinPriority3 0;
BA_ "GenSigSendType" SG_ 1459 Batt_CabinPriority3 3;
BA_ "Event trans." SG_ 1459 ChargeUntilFull3 0;
BA_ "GenSigSendType" SG_ 1459 ChargeUntilFull3 3;
BA_ "Event trans." SG_ 1459 Do_Not_Repeat3 0;
BA_ "GenSigSendType" SG_ 1459 Do_Not_Repeat3 3;
BA_ "Event trans." SG_ 1459 Enable_Schedule3 0;
BA_ "GenSigSendType" SG_ 1459 Enable_Schedule3 3;
BA_ "Event trans." SG_ 1459 End_Time_Hr3 0;
BA_ "GenSigSendType" SG_ 1459 End_Time_Hr3 3;
BA_ "Event trans." SG_ 1459 End_Time_Min3 0;
BA_ "GenSigSendType" SG_ 1459 End_Time_Min3 3;
BA_ "Event trans." SG_ 1459 Schedule_Day3 0;
BA_ "GenSigSendType" SG_ 1459 Schedule_Day3 3;
BA_ "Event trans." SG_ 1459 Schedule_Type3 0;
BA_ "GenSigSendType" SG_ 1459 Schedule_Type3 3;
BA_ "Event trans." SG_ 1459 Start_Time_Hr3 0;
BA_ "GenSigSendType" SG_ 1459 Start_Time_Hr3 3;
BA_ "Event trans." SG_ 1459 Start_Time_Min3 0;
BA_ "GenSigSendType" SG_ 1459 Start_Time_Min3 3;
BA_ "Event trans." SG_ 1459 Submit_Schedule3 0;
BA_ "GenSigSendType" SG_ 1459 Submit_Schedule3 3;
BA_ "Accuracy" SG_ 1904 DEFROST_SEL "-";
BA_ "Accuracy" SG_ 1904 DRV_TEMP_DR_POS "-";
BA_ "GenSigStartValue" SG_ 1904 DRV_TEMP_DR_POS 127;
BA_ "Accuracy" SG_ 1904 EvapTempTar "-";
BA_ "Accuracy" SG_ 1904 HtrCorTmp_InTgt "-";
BA_ "GenSigStartValue" SG_ 1904 HtrCorTmp_InTgt 215;
BA_ "Accuracy" SG_ 1904 HVAC_Blwr_Perct "-";
BA_ "GenSigStartValue" SG_ 1904 HVAC_Blwr_Perct 127;
BA_ "Accuracy" SG_ 1904 VEH_INT_TEMP "-";
BA_ "GenSigStartValue" SG_ 1904 VEH_INT_TEMP 65535;
BA_ "Accuracy" SG_ 100 ControlEncodingReq "-";
BA_ "Event trans." SG_ 100 ControlEncodingReq 0;
BA_ "GenSigSendType" SG_ 100 ControlEncodingReq 1;
BA_ "Accuracy" SG_ 100 f1_1 "-";
BA_ "Accuracy" SG_ 100 f1_2 "-";
BA_ "Accuracy" SG_ 100 rnd_1 "-";
BA_ "Accuracy" SG_ 100 rnd_2 "-";
BA_ "Accuracy" SG_ 100 rnd_3 "-";
BA_ "Accuracy" SG_ 100 rnd_4 "-";
BA_ "Accuracy" SG_ 104 ControlEncodingRsp "-";
BA_ "Event trans." SG_ 104 ControlEncodingRsp 0;
BA_ "GenSigSendType" SG_ 104 ControlEncodingRsp 1;
BA_ "Accuracy" SG_ 104 MKKey_3 "-";
BA_ "Accuracy" SG_ 104 MKKey_4 "-";
BA_ "Accuracy" SG_ 104 MKKey_5 "-";
BA_ "Accuracy" SG_ 104 MKKey_6 "-";
BA_ "Accuracy" SG_ 104 MKKey1org21 "-";
BA_ "Accuracy" SG_ 104 MKKey2org22 "-";
BA_ "Event trans." SG_ 346 IMPACTCommand 0;
BA_ "GenSigSendType" SG_ 346 IMPACTCommand 5;
BA_ "Event trans." SG_ 346 IMPACTConfirm 0;
BA_ "GenSigStartValue" SG_ 346 IMPACTConfirm 1;
BA_ "GenSigInactiveValue" SG_ 346 IMPACTConfirm 1;
BA_ "GenSigSendType" SG_ 346 IMPACTConfirm 5;
BA_ "Event trans." SG_ 346 IMPACTFailSts 0;
BA_ "GenSigSendType" SG_ 346 IMPACTFailSts 5;
BA_ "GenSigStartValue" SG_ 1058 IBS3_Ibatt 65535;
BA_ "GenSigStartValue" SG_ 1058 IBS3_Rbatt 255;
BA_ "GenSigStartValue" SG_ 1058 IBS3_Rbatt_25 255;
BA_ "GenSigStartValue" SG_ 1058 IBS3_Vbatt 511;
BA_ "GenSigStartValue" SG_ 1060 IBS3_SOC 127;
BA_ "GenSigStartValue" SG_ 1060 IBS3_SOF_Q 255;
BA_ "GenSigStartValue" SG_ 1060 IBS3_SOH_Q 127;
BA_ "GenSigStartValue" SG_ 1060 IBS3_T_BATT 255;
BA_ "GenSigStartValue" SG_ 1062 IBS3_Q_Received 65535;
BA_ "GenSigStartValue" SG_ 1062 IBS3_Q_Released 65535;
BA_ "Accuracy" SG_ 753 LatAcceleration "0,02";
BA_ "Accuracy" SG_ 753 LatAccelerationFailSts "-";
BA_ "Accuracy" SG_ 753 LongAcceleration "0,02";
BA_ "Accuracy" SG_ 753 LongAccelerationFailSts "-";
BA_ "Accuracy" SG_ 753 ZAcceleration "0,02";
BA_ "Accuracy" SG_ 753 ZAccelerationFailSts "-";
BA_ "Event trans." SG_ 1848 KeyProgramSts 0;
BA_ "GenSigSendType" SG_ 1848 KeyProgramSts 3;
BA_ "Event trans." SG_ 1848 MsgFOBLeftVeh 0;
BA_ "GenSigSendType" SG_ 1848 MsgFOBLeftVeh 3;
BA_ "Event trans." SG_ 1848 MsgFOBNotFnd 0;
BA_ "GenSigSendType" SG_ 1848 MsgFOBNotFnd 3;
BA_ "Event trans." SG_ 1848 MsgParkSoon 0;
BA_ "GenSigSendType" SG_ 1848 MsgParkSoon 3;
BA_ "Event trans." SG_ 1848 MsgServPEKG 0;
BA_ "GenSigSendType" SG_ 1848 MsgServPEKG 3;
BA_ "Event trans." SG_ 1848 StartButtonFailSts 0;
BA_ "GenSigSendType" SG_ 1848 StartButtonFailSts 3;
BA_ "Event trans." SG_ 400 ShiftLeverPositionReq 0;
BA_ "GenSigSendType" SG_ 400 ShiftLeverPositionReq 3;
BA_ "Event trans." SG_ 762 ACC_DistSwDec 0;
BA_ "GenSigSendType" SG_ 762 ACC_DistSwDec 1;
BA_ "Event trans." SG_ 762 ACC_DistSwInc 0;
BA_ "GenSigSendType" SG_ 762 ACC_DistSwInc 1;
BA_ "Event trans." SG_ 762 ACC_On 0;
BA_ "GenSigSendType" SG_ 762 ACC_On 1;
BA_ "Event trans." SG_ 762 AcceleratorSts 0;
BA_ "GenSigSendType" SG_ 762 AcceleratorSts 1;
BA_ "Event trans." SG_ 762 CRC_CSWC_1 0;
BA_ "GenSigStartValue" SG_ 762 CRC_CSWC_1 255;
BA_ "GenSigSendType" SG_ 762 CRC_CSWC_1 1;
BA_ "Event trans." SG_ 762 CruiseControlFailSts 0;
BA_ "GenSigSendType" SG_ 762 CruiseControlFailSts 1;
BA_ "Event trans." SG_ 762 CruiseControlOnOffSts 0;
BA_ "GenSigSendType" SG_ 762 CruiseControlOnOffSts 1;
BA_ "Event trans." SG_ 762 CrusCnclSwitch 0;
BA_ "GenSigSendType" SG_ 762 CrusCnclSwitch 1;
BA_ "Event trans." SG_ 762 DeceleratorSts 0;
BA_ "GenSigSendType" SG_ 762 DeceleratorSts 1;
BA_ "Event trans." SG_ 762 LaneCenteringOnOffSts 0;
BA_ "GenSigSendType" SG_ 762 LaneCenteringOnOffSts 1;
BA_ "Event trans." SG_ 762 MC_CSWC_1 0;
BA_ "GenSigSendType" SG_ 762 MC_CSWC_1 1;
BA_ "Event trans." SG_ 762 ResumeSwitch 0;
BA_ "GenSigSendType" SG_ 762 ResumeSwitch 1;
BA_ "Event trans." SG_ 762 RsErr_CSWC 0;
BA_ "GenSigSendType" SG_ 762 RsErr_CSWC 1;
BA_ "Event trans." SG_ 762 SpeedLimiterOnOffSts 0;
BA_ "GenSigSendType" SG_ 762 SpeedLimiterOnOffSts 1;
BA_ "Accuracy" SG_ 2654339129 CurrentFailSts_DASM "-";
BA_ "Accuracy" SG_ 2654339129 DES_DASM "-";
BA_ "Accuracy" SG_ 2654339129 EOL_DASM "-";
BA_ "Accuracy" SG_ 2654339129 GenericFailSts_DASM "-";
BA_ "Accuracy" SG_ 2654339136 CurrentFailSts_EVCU "-";
BA_ "Accuracy" SG_ 2654339136 DES_EVCU "-";
BA_ "Accuracy" SG_ 2654339136 EOL_EVCU "-";
BA_ "Accuracy" SG_ 2654339136 GenericFailSts_EVCU "-";
BA_ "Accuracy" SG_ 2654339075 CurrentFailSts_IPC "-";
BA_ "Accuracy" SG_ 2654339075 DES_IPC "-";
BA_ "Accuracy" SG_ 2654339075 EOL_IPC "-";
BA_ "Accuracy" SG_ 2654339075 GenericFailSts_IPC "-";
BA_ "Accuracy" SG_ 2654339094 CurrentFailSts_Shifter "-";
BA_ "Accuracy" SG_ 2654339094 DES_Shifter "-";
BA_ "Accuracy" SG_ 2654339094 EOL_Shifter "-";
BA_ "Accuracy" SG_ 2654339094 GenericFailSts_Shifter "-";
BA_ "Accuracy" SG_ 2654339107 CurrentFailSts_TBM "-";
BA_ "Accuracy" SG_ 2654339107 DES_TBM "-";
BA_ "Accuracy" SG_ 2654339107 EOL_TBM "-";
BA_ "Accuracy" SG_ 2654339107 GenericFailSts_TBM "-";
BA_ "GenSigStartValue" SG_ 1504 EPBAutoAppSts 1;
BA_ "Event trans." SG_ 1504 FastTransmission_SE 0;
BA_ "GenSigSendType" SG_ 1504 FastTransmission_SE 5;
BA_ "Accuracy" SG_ 1941 PowerModeSts_EVCU "-";
BA_ "Event trans." SG_ 896 ReliableOvertaking 0;
BA_ "GenSigSendType" SG_ 896 ReliableOvertaking 1;
BA_ "Event trans." SG_ 896 ReliableTSISign 0;
BA_ "GenSigSendType" SG_ 896 ReliableTSISign 1;
BA_ "Event trans." SG_ 896 ReliableVehicleSpdLimit 0;
BA_ "GenSigSendType" SG_ 896 ReliableVehicleSpdLimit 1;
BA_ "Event trans." SG_ 896 ReliableVehicleSpdLimitCond 0;
BA_ "GenSigSendType" SG_ 896 ReliableVehicleSpdLimitCond 1;
BA_ "Event trans." SG_ 896 SignOvertaking 0;
BA_ "GenSigSendType" SG_ 896 SignOvertaking 1;
BA_ "Event trans." SG_ 896 SignSupplemOvertaking 0;
BA_ "GenSigSendType" SG_ 896 SignSupplemOvertaking 1;
BA_ "Event trans." SG_ 896 SignSupplemVehicleSpeedLimit 0;
BA_ "GenSigSendType" SG_ 896 SignSupplemVehicleSpeedLimit 1;
BA_ "Event trans." SG_ 896 SignVehicleSpeedLimit 0;
BA_ "GenSigSendType" SG_ 896 SignVehicleSpeedLimit 1;
BA_ "Event trans." SG_ 896 SignVehicleSpeedLimitConditional 0;
BA_ "GenSigSendType" SG_ 896 SignVehicleSpeedLimitConditional 1;
BA_ "Event trans." SG_ 896 SpeedLimitFilter 0;
BA_ "GenSigSendType" SG_ 896 SpeedLimitFilter 1;
BA_ "Event trans." SG_ 896 TSRSts 0;
BA_ "GenSigSendType" SG_ 896 TSRSts 1;
BA_ "Event trans." SG_ 1475 TBM_Batt_CabinPriority1 0;
BA_ "GenSigSendType" SG_ 1475 TBM_Batt_CabinPriority1 3;
BA_ "Event trans." SG_ 1475 TBM_ChargeUntilFull1 0;
BA_ "GenSigSendType" SG_ 1475 TBM_ChargeUntilFull1 3;
BA_ "Event trans." SG_ 1475 TBM_Do_Not_Repeat1 0;
BA_ "GenSigSendType" SG_ 1475 TBM_Do_Not_Repeat1 3;
BA_ "Event trans." SG_ 1475 TBM_Enable_Schedule1 0;
BA_ "GenSigSendType" SG_ 1475 TBM_Enable_Schedule1 3;
BA_ "Event trans." SG_ 1475 TBM_End_Time_Hr1 0;
BA_ "GenSigSendType" SG_ 1475 TBM_End_Time_Hr1 3;
BA_ "Event trans." SG_ 1475 TBM_End_Time_Min1 0;
BA_ "GenSigSendType" SG_ 1475 TBM_End_Time_Min1 3;
BA_ "Event trans." SG_ 1475 TBM_Schedule_Day1 0;
BA_ "GenSigSendType" SG_ 1475 TBM_Schedule_Day1 3;
BA_ "Event trans." SG_ 1475 TBM_Schedule_Type1 0;
BA_ "GenSigSendType" SG_ 1475 TBM_Schedule_Type1 3;
BA_ "Event trans." SG_ 1475 TBM_Start_Time_Hr1 0;
BA_ "GenSigSendType" SG_ 1475 TBM_Start_Time_Hr1 3;
BA_ "Event trans." SG_ 1475 TBM_Start_Time_Min1 0;
BA_ "GenSigSendType" SG_ 1475 TBM_Start_Time_Min1 3;
BA_ "Event trans." SG_ 1475 TBM_Submit_Schedule1 0;
BA_ "GenSigSendType" SG_ 1475 TBM_Submit_Schedule1 3;
BA_ "Event trans." SG_ 1473 TBM_Batt_CabinPriority2 0;
BA_ "GenSigSendType" SG_ 1473 TBM_Batt_CabinPriority2 3;
BA_ "Event trans." SG_ 1473 TBM_ChargeUntilFull2 0;
BA_ "GenSigSendType" SG_ 1473 TBM_ChargeUntilFull2 3;
BA_ "Event trans." SG_ 1473 TBM_Do_Not_Repeat2 0;
BA_ "GenSigSendType" SG_ 1473 TBM_Do_Not_Repeat2 3;
BA_ "Event trans." SG_ 1473 TBM_Enable_Schedule2 0;
BA_ "GenSigSendType" SG_ 1473 TBM_Enable_Schedule2 3;
BA_ "Event trans." SG_ 1473 TBM_End_Time_Hr2 0;
BA_ "GenSigSendType" SG_ 1473 TBM_End_Time_Hr2 3;
BA_ "Event trans." SG_ 1473 TBM_End_Time_Min2 0;
BA_ "GenSigSendType" SG_ 1473 TBM_End_Time_Min2 3;
BA_ "Event trans." SG_ 1473 TBM_Schedule_Day2 0;
BA_ "GenSigSendType" SG_ 1473 TBM_Schedule_Day2 3;
BA_ "Event trans." SG_ 1473 TBM_Schedule_Type2 0;
BA_ "GenSigSendType" SG_ 1473 TBM_Schedule_Type2 3;
BA_ "Event trans." SG_ 1473 TBM_Start_Time_Hr2 0;
BA_ "GenSigSendType" SG_ 1473 TBM_Start_Time_Hr2 3;
BA_ "Event trans." SG_ 1473 TBM_Start_Time_Min2 0;
BA_ "GenSigSendType" SG_ 1473 TBM_Start_Time_Min2 3;
BA_ "Event trans." SG_ 1473 TBM_Submit_Schedule2 0;
BA_ "GenSigSendType" SG_ 1473 TBM_Submit_Schedule2 3;
BA_ "Event trans." SG_ 1474 TBM_Batt_CabinPriority3 0;
BA_ "GenSigSendType" SG_ 1474 TBM_Batt_CabinPriority3 3;
BA_ "Event trans." SG_ 1474 TBM_ChargeUntilFull3 0;
BA_ "GenSigSendType" SG_ 1474 TBM_ChargeUntilFull3 3;
BA_ "Event trans." SG_ 1474 TBM_Do_Not_Repeat3 0;
BA_ "GenSigSendType" SG_ 1474 TBM_Do_Not_Repeat3 3;
BA_ "Event trans." SG_ 1474 TBM_Enable_Schedule3 0;
BA_ "GenSigSendType" SG_ 1474 TBM_Enable_Schedule3 3;
BA_ "Event trans." SG_ 1474 TBM_End_Time_Hr3 0;
BA_ "GenSigSendType" SG_ 1474 TBM_End_Time_Hr3 3;
BA_ "Event trans." SG_ 1474 TBM_End_Time_Min3 0;
BA_ "GenSigSendType" SG_ 1474 TBM_End_Time_Min3 3;
BA_ "Event trans." SG_ 1474 TBM_Schedule_Day3 0;
BA_ "GenSigSendType" SG_ 1474 TBM_Schedule_Day3 3;
BA_ "Event trans." SG_ 1474 TBM_Schedule_Type3 0;
BA_ "GenSigSendType" SG_ 1474 TBM_Schedule_Type3 3;
BA_ "Event trans." SG_ 1474 TBM_Start_Time_Hr3 0;
BA_ "GenSigSendType" SG_ 1474 TBM_Start_Time_Hr3 3;
BA_ "Event trans." SG_ 1474 TBM_Start_Time_Min3 0;
BA_ "GenSigSendType" SG_ 1474 TBM_Start_Time_Min3 3;
BA_ "Event trans." SG_ 1474 TBM_Submit_Schedule3 0;
BA_ "GenSigSendType" SG_ 1474 TBM_Submit_Schedule3 3;
BA_ "Accuracy" SG_ 1850 Day1 "-";
BA_ "Event trans." SG_ 1850 Day1 0;
BA_ "GenSigSendType" SG_ 1850 Day1 3;
BA_ "Accuracy" SG_ 1850 Day2 "-";
BA_ "Event trans." SG_ 1850 Day2 0;
BA_ "GenSigSendType" SG_ 1850 Day2 3;
BA_ "Accuracy" SG_ 1850 Hour1 "-";
BA_ "Event trans." SG_ 1850 Hour1 0;
BA_ "GenSigSendType" SG_ 1850 Hour1 3;
BA_ "Accuracy" SG_ 1850 Hour2 "-";
BA_ "Event trans." SG_ 1850 Hour2 0;
BA_ "GenSigSendType" SG_ 1850 Hour2 3;
BA_ "Accuracy" SG_ 1850 Minute1 "-";
BA_ "Event trans." SG_ 1850 Minute1 0;
BA_ "GenSigSendType" SG_ 1850 Minute1 3;
BA_ "Accuracy" SG_ 1850 Minute2 "-";
BA_ "Event trans." SG_ 1850 Minute2 0;
BA_ "GenSigSendType" SG_ 1850 Minute2 3;
BA_ "Accuracy" SG_ 1850 Month1 "-";
BA_ "Event trans." SG_ 1850 Month1 0;
BA_ "GenSigSendType" SG_ 1850 Month1 3;
BA_ "Accuracy" SG_ 1850 Month2 "-";
BA_ "Event trans." SG_ 1850 Month2 0;
BA_ "GenSigSendType" SG_ 1850 Month2 3;
BA_ "Accuracy" SG_ 1850 Year1 "-";
BA_ "Event trans." SG_ 1850 Year1 0;
BA_ "GenSigSendType" SG_ 1850 Year1 3;
BA_ "Accuracy" SG_ 1850 Year2 "-";
BA_ "Event trans." SG_ 1850 Year2 0;
BA_ "GenSigSendType" SG_ 1850 Year2 3;
BA_ "Accuracy" SG_ 1850 Year3 "-";
BA_ "Event trans." SG_ 1850 Year3 0;
BA_ "GenSigSendType" SG_ 1850 Year3 3;
BA_ "Accuracy" SG_ 1850 Year4 "-";
BA_ "Event trans." SG_ 1850 Year4 0;
BA_ "GenSigSendType" SG_ 1850 Year4 3;
BA_ "Accuracy" SG_ 1000 CalibrationAck "-";
BA_ "Event trans." SG_ 1000 CalibrationAck 0;
BA_ "GenSigSendType" SG_ 1000 CalibrationAck 6;
BA_ "Accuracy" SG_ 1000 CalibrationSts "-";
BA_ "Event trans." SG_ 1000 CalibrationSts 0;
BA_ "GenSigSendType" SG_ 1000 CalibrationSts 4;
BA_ "Event trans." SG_ 1448 BuzzerReqSts_T2 0;
BA_ "GenSigSendType" SG_ 1448 BuzzerReqSts_T2 3;
BA_ "Event trans." SG_ 1448 GearIndicationSts 0;
BA_ "GenSigSendType" SG_ 1448 GearIndicationSts 3;
BA_ "Event trans." SG_ 1448 ParkingFailSts 0;
BA_ "GenSigSendType" SG_ 1448 ParkingFailSts 3;
BA_ "Event trans." SG_ 1448 ParkingSts 0;
BA_ "GenSigSendType" SG_ 1448 ParkingSts 3;
BA_ "Event trans." SG_ 1448 ShiftLeverPosition 0;
BA_ "GenSigSendType" SG_ 1448 ShiftLeverPosition 3;
BA_ "Event trans." SG_ 1448 TransmissionWarnings 0;
BA_ "GenSigSendType" SG_ 1448 TransmissionWarnings 3;
BA_ "Event trans." SG_ 344 Vehicle_Hold_Rq 0;
BA_ "GenSigSendType" SG_ 344 Vehicle_Hold_Rq 5;
BA_ "GenSigStartValue" SG_ 253 TxpFound 1;
BA_ "GenSigStartValue" SG_ 1046 VIN_MSG 3;
BA_ "Accuracy" SG_ 2654208000 MainWakeSts_BCM "-";
BA_ "Accuracy" SG_ 2654208000 Node0 "-";
BA_ "Accuracy" SG_ 2654208000 Node1 "-";
BA_ "Accuracy" SG_ 2654208000 Node10 "-";
BA_ "Accuracy" SG_ 2654208000 Node11 "-";
BA_ "Accuracy" SG_ 2654208000 Node12 "-";
BA_ "Accuracy" SG_ 2654208000 Node13 "-";
BA_ "Accuracy" SG_ 2654208000 Node14 "-";
BA_ "Accuracy" SG_ 2654208000 Node15 "-";
BA_ "Accuracy" SG_ 2654208000 Node16 "-";
BA_ "Accuracy" SG_ 2654208000 Node17 "-";
BA_ "Accuracy" SG_ 2654208000 Node18 "-";
BA_ "Accuracy" SG_ 2654208000 Node19 "-";
BA_ "Accuracy" SG_ 2654208000 Node2 "-";
BA_ "Accuracy" SG_ 2654208000 Node20 "-";
BA_ "Accuracy" SG_ 2654208000 Node21 "-";
BA_ "Accuracy" SG_ 2654208000 Node22 "-";
BA_ "Accuracy" SG_ 2654208000 Node23 "-";
BA_ "Accuracy" SG_ 2654208000 Node24 "-";
BA_ "Accuracy" SG_ 2654208000 Node25 "-";
BA_ "Accuracy" SG_ 2654208000 Node26 "-";
BA_ "Accuracy" SG_ 2654208000 Node27 "-";
BA_ "Accuracy" SG_ 2654208000 Node28 "-";
BA_ "Accuracy" SG_ 2654208000 Node29 "-";
BA_ "Accuracy" SG_ 2654208000 Node3 "-";
BA_ "Accuracy" SG_ 2654208000 Node30 "-";
BA_ "Accuracy" SG_ 2654208000 Node31 "-";
BA_ "Accuracy" SG_ 2654208000 Node4 "-";
BA_ "Accuracy" SG_ 2654208000 Node5 "-";
BA_ "Accuracy" SG_ 2654208000 Node6 "-";
BA_ "Accuracy" SG_ 2654208000 Node7 "-";
BA_ "Accuracy" SG_ 2654208000 Node8 "-";
BA_ "Accuracy" SG_ 2654208000 Node9 "-";
BA_ "Accuracy" SG_ 2654208000 WakeCntr_BCM "-";
BA_ "Accuracy" SG_ 2654208000 WakeRsn_BCM "-";
BA_ "GenSigStartValue" SG_ 2654208006 WakeUpNodeAddress 1;
BA_ "GenSigStartValue" SG_ 2654208064 WakeUpNodeAddress 10;
BA_ "GenSigStartValue" SG_ 2654208003 WakeUpNodeAddress 6;
BA_ "GenSigStartValue" SG_ 2654208022 WakeUpNodeAddress 13;
BA_ "Accuracy" SG_ 278 CRC_WI "-";
BA_ "Accuracy" SG_ 278 LHF_FastPulseCounter "-";
BA_ "Accuracy" SG_ 278 LHF_Spin "-";
BA_ "Accuracy" SG_ 278 LHF_WheelSensorFailSts "-";
BA_ "Accuracy" SG_ 278 LHR_FastPulseCounter "-";
BA_ "Accuracy" SG_ 278 LHR_Spin "-";
BA_ "Accuracy" SG_ 278 LHR_WheelSensorFailSts "-";
BA_ "Accuracy" SG_ 278 MessageCounter_WI "-";
BA_ "Accuracy" SG_ 278 RHF_FastPulseCounter "-";
BA_ "Accuracy" SG_ 278 RHF_Spin "-";
BA_ "Accuracy" SG_ 278 RHF_WheelSensorFailSts "-";
BA_ "Accuracy" SG_ 278 RHR_FastPulseCounter "-";
BA_ "Accuracy" SG_ 278 RHR_Spin "-";
BA_ "Accuracy" SG_ 278 RHR_WheelSensorFailSts "-";
BA_ "Accuracy" SG_ 238 LHFWheelSpeed "-";
BA_ "Accuracy" SG_ 238 LHRWheelSpeed "-";
BA_ "Accuracy" SG_ 238 RHFWheelSpeed "-";
BA_ "Accuracy" SG_ 238 RHRWheelSpeed "-";
VAL_ 1466 Batt_CabinPriority2_Sts 0 "Battery charging on priority" 1 "Cabin conditioning on priority";
VAL_ 1466 ChargeUntilFull2_Sts 0 "Charge Until Full Not selected" 1 "Charge Until Full";
VAL_ 1466 Do_Not_Repeat2_Sts 0 "Repeat" 1 "Do Not Repeat";
VAL_ 1466 End_Time_Hr2_Sts 31 "SNA";
VAL_ 1466 End_Time_Min2_Sts 15 "SNA";
VAL_ 1466 Schedule_Confirmed2 0 "Disable" 1 "Enable";
VAL_ 1466 Schedule_Day2_Sts 0 "No Selection" 1 "M" 2 "T" 3 "TM" 4 "W" 5 "WM" 6 "WT" 7 "WTM" 8 "Th" 9 "ThM" 10 "ThT" 11 "ThTM" 12 "ThW" 13 "ThWM" 14 "ThWT" 15 "ThWTM" 16 "F" 17 "FM" 18 "FT" 19 "FTM" 20 "FW" 21 "FWM" 22 "FWT" 23 "FWTM" 24 "FTh" 25 "FThM" 26 "FThT" 27 "FThTM" 28 "FThW" 29 "FThWM" 30 "FThWT" 31 "FThWTM" 32 "S" 33 "SM" 34 "ST" 35 "STM" 36 "SW" 37 "SWM" 38 "SWT" 39 "SWTM" 40 "STh" 41 "SThM" 42 "SThT" 43 "SThTM" 44 "SThW" 45 "SThWM" 46 "SThWT" 47 "SThWTM" 48 "SF" 49 "SFM" 50 "SFT" 51 "SFTM" 52 "SFW" 53 "SFWM" 54 "SFWT" 55 "SFWTM" 56 "SFTh" 57 "SFThM" 58 "SFThT" 59 "SFThTM" 60 "SFThW" 61 "SFThWM" 62 "SFThWT" 63 "SFThWTM" 64 "Sa" 65 "SaM" 66 "SaT" 67 "SaTM" 68 "SaW" 69 "SaWM" 70 "SaWT" 71 "SaWTM" 72 "SaTh" 73 "SaThM" 74 "SaThT" 75 "SaThTM" 76 "SaThW" 77 "SaThWM" 78 "SaThWT" 79 "SaThWTM" 80 "SaF" 81 "SaFM" 82 "SaFT" 83 "SaFTM" 84 "SaFW" 85 "SaFWM" 86 "SaFWT" 87 "SaFWTM" 88 "SaFTh" 89 "SaFThM" 90 "SaFThT" 91 "SaFThTM" 92 "SaFThW" 93 "SaFThWM" 94 "SaFThWT" 95 "SaFThWTM" 96 "SaS" 97 "SaSM" 98 "SaST" 99 "SaSTM" 100 "SaSW" 101 "SaSWM" 102 "SaSWT" 103 "SaSWTM" 104 "SaSTh" 105 "SaSThM" 106 "SaSThT" 107 "SaSThTM" 108 "SaSThW" 109 "SaSThWM" 110 "SaSThWT" 111 "SaSThWTM" 112 "SaSF" 113 "SaSFM" 114 "SaSFT" 115 "SaSFTM" 116 "SaSFW" 117 "SaSFWM" 118 "SaSFWT" 119 "SaSFWTM" 120 "SaSFTh" 121 "SaSFThM" 122 "SaSFThT" 123 "SaSFThTM" 124 "SaSFThW" 125 "SaSFThWM" 126 "SaSFThWT" 127 "SaSFThWTM" 255 "SNA";
VAL_ 1466 Schedule_Type2_Sts 0 "No Selection" 1 "Departure Time" 2 "Charge Interval" 3 "SNA";
VAL_ 1466 Start_Time_Hr2_Sts 31 "SNA";
VAL_ 1466 Start_Time_Min2_Sts 15 "SNA";
VAL_ 1467 Batt_CabinPriority3_Sts 0 "Battery charging on priority" 1 "Cabin conditioning on priority";
VAL_ 1467 ChargeUntilFull3_Sts 0 "Charge Until Full Not selected" 1 "Charge Until Full";
VAL_ 1467 Do_Not_Repeat3_Sts 0 "Repeat" 1 "Do Not Repeat";
VAL_ 1467 End_Time_Hr3_Sts 31 "SNA";
VAL_ 1467 End_Time_Min3_Sts 15 "SNA";
VAL_ 1467 Schedule_Confirmed3 0 "Disable" 1 "Enable";
VAL_ 1467 Schedule_Day3_Sts 0 "No Selection" 1 "M" 2 "T" 3 "TM" 4 "W" 5 "WM" 6 "WT" 7 "WTM" 8 "Th" 9 "ThM" 10 "ThT" 11 "ThTM" 12 "ThW" 13 "ThWM" 14 "ThWT" 15 "ThWTM" 16 "F" 17 "FM" 18 "FT" 19 "FTM" 20 "FW" 21 "FWM" 22 "FWT" 23 "FWTM" 24 "FTh" 25 "FThM" 26 "FThT" 27 "FThTM" 28 "FThW" 29 "FThWM" 30 "FThWT" 31 "FThWTM" 32 "S" 33 "SM" 34 "ST" 35 "STM" 36 "SW" 37 "SWM" 38 "SWT" 39 "SWTM" 40 "STh" 41 "SThM" 42 "SThT" 43 "SThTM" 44 "SThW" 45 "SThWM" 46 "SThWT" 47 "SThWTM" 48 "SF" 49 "SFM" 50 "SFT" 51 "SFTM" 52 "SFW" 53 "SFWM" 54 "SFWT" 55 "SFWTM" 56 "SFTh" 57 "SFThM" 58 "SFThT" 59 "SFThTM" 60 "SFThW" 61 "SFThWM" 62 "SFThWT" 63 "SFThWTM" 64 "Sa" 65 "SaM" 66 "SaT" 67 "SaTM" 68 "SaW" 69 "SaWM" 70 "SaWT" 71 "SaWTM" 72 "SaTh" 73 "SaThM" 74 "SaThT" 75 "SaThTM" 76 "SaThW" 77 "SaThWM" 78 "SaThWT" 79 "SaThWTM" 80 "SaF" 81 "SaFM" 82 "SaFT" 83 "SaFTM" 84 "SaFW" 85 "SaFWM" 86 "SaFWT" 87 "SaFWTM" 88 "SaFTh" 89 "SaFThM" 90 "SaFThT" 91 "SaFThTM" 92 "SaFThW" 93 "SaFThWM" 94 "SaFThWT" 95 "SaFThWTM" 96 "SaS" 97 "SaSM" 98 "SaST" 99 "SaSTM" 100 "SaSW" 101 "SaSWM" 102 "SaSWT" 103 "SaSWTM" 104 "SaSTh" 105 "SaSThM" 106 "SaSThT" 107 "SaSThTM" 108 "SaSThW" 109 "SaSThWM" 110 "SaSThWT" 111 "SaSThWTM" 112 "SaSF" 113 "SaSFM" 114 "SaSFT" 115 "SaSFTM" 116 "SaSFW" 117 "SaSFWM" 118 "SaSFWT" 119 "SaSFWTM" 120 "SaSFTh" 121 "SaSFThM" 122 "SaSFThT" 123 "SaSFThTM" 124 "SaSFThW" 125 "SaSFThWM" 126 "SaSFThWT" 127 "SaSFThWTM" 255 "SNA";
VAL_ 1467 Schedule_Type3_Sts 0 "No Selection" 1 "Departure Time" 2 "Charge Interval" 3 "SNA";
VAL_ 1467 Start_Time_Hr3_Sts 31 "SNA";
VAL_ 1467 Start_Time_Min3_Sts 15 "SNA";
VAL_ 1840 Next_Charge_End_Time_Hr 25 "Charge_Until_Full" 31 "SNA";
VAL_ 1840 Next_Charge_End_Time_Min 15 "SNA";
VAL_ 1840 Next_Charge_EndDay 0 "No_Selection" 1 "M" 2 "T" 3 "W" 4 "Th" 5 "F" 6 "Sa" 7 "S" 15 "SNA";
VAL_ 1840 Next_Charge_Start_Time_Hr 31 "SNA";
VAL_ 1840 Next_Charge_Start_Time_Min 15 "SNA";
VAL_ 1840 Next_Charge_StartDay 0 "No_Selection" 1 "M" 2 "T" 3 "W" 4 "Th" 5 "F" 6 "Sa" 7 "S" 9 "No_Schedule_Set" 15 "SNA";
VAL_ 1840 Next_Climate_Day 0 "No_Selection" 1 "M" 2 "T" 3 "W" 4 "Th" 5 "F" 6 "Sa" 7 "S" 9 "No_Schedule_Set" 15 "SNA";
VAL_ 1840 Next_Climate_Time_Hr 25 "Charge_Until_Full" 31 "SNA";
VAL_ 1840 Next_Climate_Time_Min 15 "SNA";
VAL_ 1457 Batt_CabinPriority1 0 "Checkbox Unselected" 1 "Checkbox Selected";
VAL_ 1457 ChargeUntilFull1 0 "Charge Until Full Not selected" 1 "Charge Until Full";
VAL_ 1457 Do_Not_Repeat1 0 "Repeat" 1 "Do Not Repeat";
VAL_ 1457 Enable_Schedule1 0 "Disable schedule1" 1 "Enable schedule1";
VAL_ 1457 End_Time_Hr1 31 "SNA";
VAL_ 1457 End_Time_Min1 15 "SNA";
VAL_ 1457 Schedule_Day1 0 "No Selection" 1 "M" 2 "T" 3 "TM" 4 "W" 5 "WM" 6 "WT" 7 "WTM" 8 "Th" 9 "ThM" 10 "ThT" 11 "ThTM" 12 "ThW" 13 "ThWM" 14 "ThWT" 15 "ThWTM" 16 "F" 17 "FM" 18 "FT" 19 "FTM" 20 "FW" 21 "FWM" 22 "FWT" 23 "FWTM" 24 "FTh" 25 "FThM" 26 "FThT" 27 "FThTM" 28 "FThW" 29 "FThWM" 30 "FThWT" 31 "FThWTM" 32 "S" 33 "SM" 34 "ST" 35 "STM" 36 "SW" 37 "SWM" 38 "SWT" 39 "SWTM" 40 "STh" 41 "SThM" 42 "SThT" 43 "SThTM" 44 "SThW" 45 "SThWM" 46 "SThWT" 47 "SThWTM" 48 "SF" 49 "SFM" 50 "SFT" 51 "SFTM" 52 "SFW" 53 "SFWM" 54 "SFWT" 55 "SFWTM" 56 "SFTh" 57 "SFThM" 58 "SFThT" 59 "SFThTM" 60 "SFThW" 61 "SFThWM" 62 "SFThWT" 63 "SFThWTM" 64 "Sa" 65 "SaM" 66 "SaT" 67 "SaTM" 68 "SaW" 69 "SaWM" 70 "SaWT" 71 "SaWTM" 72 "SaTh" 73 "SaThM" 74 "SaThT" 75 "SaThTM" 76 "SaThW" 77 "SaThWM" 78 "SaThWT" 79 "SaThWTM" 80 "SaF" 81 "SaFM" 82 "SaFT" 83 "SaFTM" 84 "SaFW" 85 "SaFWM" 86 "SaFWT" 87 "SaFWTM" 88 "SaFTh" 89 "SaFThM" 90 "SaFThT" 91 "SaFThTM" 92 "SaFThW" 93 "SaFThWM" 94 "SaFThWT" 95 "SaFThWTM" 96 "SaS" 97 "SaSM" 98 "SaST" 99 "SaSTM" 100 "SaSW" 101 "SaSWM" 102 "SaSWT" 103 "SaSWTM" 104 "SaSTh" 105 "SaSThM" 106 "SaSThT" 107 "SaSThTM" 108 "SaSThW" 109 "SaSThWM" 110 "SaSThWT" 111 "SaSThWTM" 112 "SaSF" 113 "SaSFM" 114 "SaSFT" 115 "SaSFTM" 116 "SaSFW" 117 "SaSFWM" 118 "SaSFWT" 119 "SaSFWTM" 120 "SaSFTh" 121 "SaSFThM" 122 "SaSFThT" 123 "SaSFThTM" 124 "SaSFThW" 125 "SaSFThWM" 126 "SaSFThWT" 127 "SaSFThWTM" 255 "SNA";
VAL_ 1457 Schedule_Type1 0 "No Selection" 1 "Departure Time" 2 "Charge Interval" 3 "SNA";
VAL_ 1457 Start_Time_Hr1 31 "SNA";
VAL_ 1457 Start_Time_Min1 15 "SNA";
VAL_ 1457 Submit_Schedule1 0 "No Change" 1 "Change in schedule 1";
VAL_ 1458 Batt_CabinPriority2 0 "Checkbox Unselected" 1 "Checkbox Selected";
VAL_ 1458 ChargeUntilFull2 0 "Charge Until Full Not selected" 1 "Charge Until Full";
VAL_ 1458 Do_Not_Repeat2 0 "Repeat" 1 "Do Not Repeat";
VAL_ 1458 Enable_Schedule2 0 "Disable schedule2" 1 "Enable schedule2";
VAL_ 1458 End_Time_Hr2 31 "SNA";
VAL_ 1458 End_Time_Min2 15 "SNA";
VAL_ 1458 Schedule_Day2 0 "No Selection" 1 "M" 2 "T" 3 "TM" 4 "W" 5 "WM" 6 "WT" 7 "WTM" 8 "Th" 9 "ThM" 10 "ThT" 11 "ThTM" 12 "ThW" 13 "ThWM" 14 "ThWT" 15 "ThWTM" 16 "F" 17 "FM" 18 "FT" 19 "FTM" 20 "FW" 21 "FWM" 22 "FWT" 23 "FWTM" 24 "FTh" 25 "FThM" 26 "FThT" 27 "FThTM" 28 "FThW" 29 "FThWM" 30 "FThWT" 31 "FThWTM" 32 "S" 33 "SM" 34 "ST" 35 "STM" 36 "SW" 37 "SWM" 38 "SWT" 39 "SWTM" 40 "STh" 41 "SThM" 42 "SThT" 43 "SThTM" 44 "SThW" 45 "SThWM" 46 "SThWT" 47 "SThWTM" 48 "SF" 49 "SFM" 50 "SFT" 51 "SFTM" 52 "SFW" 53 "SFWM" 54 "SFWT" 55 "SFWTM" 56 "SFTh" 57 "SFThM" 58 "SFThT" 59 "SFThTM" 60 "SFThW" 61 "SFThWM" 62 "SFThWT" 63 "SFThWTM" 64 "Sa" 65 "SaM" 66 "SaT" 67 "SaTM" 68 "SaW" 69 "SaWM" 70 "SaWT" 71 "SaWTM" 72 "SaTh" 73 "SaThM" 74 "SaThT" 75 "SaThTM" 76 "SaThW" 77 "SaThWM" 78 "SaThWT" 79 "SaThWTM" 80 "SaF" 81 "SaFM" 82 "SaFT" 83 "SaFTM" 84 "SaFW" 85 "SaFWM" 86 "SaFWT" 87 "SaFWTM" 88 "SaFTh" 89 "SaFThM" 90 "SaFThT" 91 "SaFThTM" 92 "SaFThW" 93 "SaFThWM" 94 "SaFThWT" 95 "SaFThWTM" 96 "SaS" 97 "SaSM" 98 "SaST" 99 "SaSTM" 100 "SaSW" 101 "SaSWM" 102 "SaSWT" 103 "SaSWTM" 104 "SaSTh" 105 "SaSThM" 106 "SaSThT" 107 "SaSThTM" 108 "SaSThW" 109 "SaSThWM" 110 "SaSThWT" 111 "SaSThWTM" 112 "SaSF" 113 "SaSFM" 114 "SaSFT" 115 "SaSFTM" 116 "SaSFW" 117 "SaSFWM" 118 "SaSFWT" 119 "SaSFWTM" 120 "SaSFTh" 121 "SaSFThM" 122 "SaSFThT" 123 "SaSFThTM" 124 "SaSFThW" 125 "SaSFThWM" 126 "SaSFThWT" 127 "SaSFThWTM" 255 "SNA";
VAL_ 1458 Schedule_Type2 0 "No Selection" 1 "Departure Time" 2 "Charge Interval" 3 "SNA";
VAL_ 1458 Start_Time_Hr2 31 "SNA";
VAL_ 1458 Start_Time_Min2 15 "SNA";
VAL_ 1458 Submit_Schedule2 0 "No Change" 1 "Change in schedule 2";
VAL_ 1459 Batt_CabinPriority3 0 "Checkbox Unselected" 1 "Checkbox Selected";
VAL_ 1459 ChargeUntilFull3 0 "Charge Until Full Not selected" 1 "Charge Until Full";
VAL_ 1459 Do_Not_Repeat3 0 "Repeat" 1 "Do Not Repeat";
VAL_ 1459 Enable_Schedule3 0 "Disable schedule3" 1 "Enable schedule3";
VAL_ 1459 End_Time_Hr3 31 "SNA";
VAL_ 1459 End_Time_Min3 15 "SNA";
VAL_ 1459 Schedule_Day3 0 "No Selection" 1 "M" 2 "T" 3 "TM" 4 "W" 5 "WM" 6 "WT" 7 "WTM" 8 "Th" 9 "ThM" 10 "ThT" 11 "ThTM" 12 "ThW" 13 "ThWM" 14 "ThWT" 15 "ThWTM" 16 "F" 17 "FM" 18 "FT" 19 "FTM" 20 "FW" 21 "FWM" 22 "FWT" 23 "FWTM" 24 "FTh" 25 "FThM" 26 "FThT" 27 "FThTM" 28 "FThW" 29 "FThWM" 30 "FThWT" 31 "FThWTM" 32 "S" 33 "SM" 34 "ST" 35 "STM" 36 "SW" 37 "SWM" 38 "SWT" 39 "SWTM" 40 "STh" 41 "SThM" 42 "SThT" 43 "SThTM" 44 "SThW" 45 "SThWM" 46 "SThWT" 47 "SThWTM" 48 "SF" 49 "SFM" 50 "SFT" 51 "SFTM" 52 "SFW" 53 "SFWM" 54 "SFWT" 55 "SFWTM" 56 "SFTh" 57 "SFThM" 58 "SFThT" 59 "SFThTM" 60 "SFThW" 61 "SFThWM" 62 "SFThWT" 63 "SFThWTM" 64 "Sa" 65 "SaM" 66 "SaT" 67 "SaTM" 68 "SaW" 69 "SaWM" 70 "SaWT" 71 "SaWTM" 72 "SaTh" 73 "SaThM" 74 "SaThT" 75 "SaThTM" 76 "SaThW" 77 "SaThWM" 78 "SaThWT" 79 "SaThWTM" 80 "SaF" 81 "SaFM" 82 "SaFT" 83 "SaFTM" 84 "SaFW" 85 "SaFWM" 86 "SaFWT" 87 "SaFWTM" 88 "SaFTh" 89 "SaFThM" 90 "SaFThT" 91 "SaFThTM" 92 "SaFThW" 93 "SaFThWM" 94 "SaFThWT" 95 "SaFThWTM" 96 "SaS" 97 "SaSM" 98 "SaST" 99 "SaSTM" 100 "SaSW" 101 "SaSWM" 102 "SaSWT" 103 "SaSWTM" 104 "SaSTh" 105 "SaSThM" 106 "SaSThT" 107 "SaSThTM" 108 "SaSThW" 109 "SaSThWM" 110 "SaSThWT" 111 "SaSThWTM" 112 "SaSF" 113 "SaSFM" 114 "SaSFT" 115 "SaSFTM" 116 "SaSFW" 117 "SaSFWM" 118 "SaSFWT" 119 "SaSFWTM" 120 "SaSFTh" 121 "SaSFThM" 122 "SaSFThT" 123 "SaSFThTM" 124 "SaSFThW" 125 "SaSFThWM" 126 "SaSFThWT" 127 "SaSFThWTM" 255 "SNA";
VAL_ 1459 Schedule_Type3 0 "No Selection" 1 "Departure Time" 2 "Charge Interval" 3 "SNA";
VAL_ 1459 Start_Time_Hr3 31 "SNA";
VAL_ 1459 Start_Time_Min3 15 "SNA";
VAL_ 1459 Submit_Schedule3 0 "No Change" 1 "Change in schedule 3";
VAL_ 1904 DEFROST_SEL 0 "Not_Active" 1 "Active";
VAL_ 1904 DRV_TEMP_DR_POS 127 "SNA";
VAL_ 1904 EvapTempTar 255 "SNA";
VAL_ 1904 HtrCorTmp_InTgt 255 "SNA";
VAL_ 1904 HVAC_Blwr_Perct 127 "SNA";
VAL_ 1904 VEH_INT_TEMP 65535 "SNA";
VAL_ 1933 HVBatCellVltMax 8191 "SNA";
VAL_ 1934 ACSideCurr 1023 "SNA";
VAL_ 1934 ACSideVolt 4095 "SNA";
VAL_ 1934 APM_FailureReason 0 "No_Failure" 1 "Fail_high_voltage_at_HV" 2 "Fail_low_voltage_at_HV" 3 "Fail_high_voltage_at_LV" 4 "Fail_low_voltage_at_LV" 5 "Fail_high_PCB_temperature" 6 "Fail_high_DBC_temperature" 7 "Fail_high_curr_at_LV" 8 "Fail_high_curr_at_HV" 9 "Fail_short_circ_at_LV" 10 "Fail_short_circ_at_HV" 11 "Fail_open_circ_at_LV" 12 "Fail_open_circ_at_HV" 13 "Fail_init_failure" 14 "Fail_wake_up_issue" 15 "Fail_internal_hardware" 16 "Fail_bat_fedd_low" 17 "Fail_bat_feed_high" 18 "Fail_Aux_OV" 19 "Fail_Aux_UV" 20 "Fail_HVIL_fault" 21 "Fail_LOC_with_HCP" 22 "Fail_LOC_with_BPCM" 23 "Fail_cont_not_closed" 24 "Fail_SBC_fault" 25 "Memory_Fail" 26 "Implausible_data_from_HCP" 27 "Implausible_data_from_BPCM" 28 "CAN_bus_off" 29 "Fail_temp_diff_is_high" 30 "Fail_high_voltage_diff_is_high" 31 "Fail_for_other_reason" 32 "LOC_ORC" 33 "Implausible_data_ORC" 63 "SNA";
VAL_ 1934 APM_OperModeStatus 0 "IDLE" 1 "Buck_CV" 2 "Buck_CC" 3 "Buck_CP" 4 "Buck_Special" 5 "Boost" 6 "Precharge" 7 "Discharge" 8 "Failure" 15 "SNA";
VAL_ 1934 APM_OutputPower 1023 "SNA";
VAL_ 1939 APMPerfWrn 0 "Normal" 1 "Warning";
VAL_ 1939 APMTempWrn 0 "Normal" 1 "Warning";
VAL_ 1939 HighestWarnLevel 0 "No_Faults" 1 "Level_1" 2 "Level_2" 3 "Level_3";
VAL_ 100 ControlEncodingReq 5 "ControlEncoding_ENQ" 6 "ControlEncoding_ACK" 21 "ControlEncoding_NACK" 132 "ControlEncoding_EOTp" 133 "ControlEncoding_ENQp" 134 "ControlEncoding_ACK1p" 135 "ControlEncoding_ACK2p";
VAL_ 100 f1_1 0 "Val1_f1_1" 81 "Val5_f1_1" 119 "Val2_f1_1" 145 "Val3_f1_1" 159 "Val4_f1_1";
VAL_ 100 f1_2 0 "Val1_f1_2" 5 "Val2_f1_2" 13 "Val4_f1_2" 14 "Val3_f1_2" 15 "Val5_f1_2";
VAL_ 100 rnd_1 0 "Val1_rnd_1" 58 "Val2_rnd_1" 59 "Val3_rnd_1" 60 "Val4_rnd_1" 61 "Val5_rnd_1" 62 "Val6_rnd_1" 63 "Val7_rnd_1" 64 "Val8_rnd_1" 65 "Val9_rnd_1" 66 "ValA_rnd_1" 67 "ValB_rnd_1" 68 "ValC_rnd_1" 69 "ValD_rnd_1" 70 "ValE_rnd_1" 71 "ValF_rnd_1";
VAL_ 100 rnd_2 0 "Val1_rnd_2" 26 "Val3_rnd_2" 43 "Val5_rnd_2" 79 "Val2_rnd_2" 168 "Val4_rnd_2";
VAL_ 100 rnd_3 0 "Val1_rnd_3" 19 "Val3_rnd_3" 21 "Val5_rnd_3" 32 "Val4_rnd_3" 129 "Val2_rnd_3";
VAL_ 100 rnd_4 0 "Val1_rnd_4" 170 "Val5_rnd_4" 203 "Val2_rnd_4" 221 "Val3_rnd_4" 238 "Val4_rnd_4";
VAL_ 104 MKKey_3 36 "FIX__MKKey_3";
VAL_ 104 MKKey_4 214 "FIX__MKKey_4";
VAL_ 104 MKKey_5 1 "FIX__MKKey_5";
VAL_ 104 MKKey_6 77 "FIX__MKKey_6";
VAL_ 104 MKKey1org21 84 "FIX__MKKey_1";
VAL_ 104 MKKey2org22 85 "FIX__MKKey_2";
VAL_ 346 IMPACT_A 0 "Do_Not_Actuate" 1 "Actuate";
VAL_ 346 IMPACT_B 0 "Do_Not_Actuate" 1 "Actuate";
VAL_ 346 IMPACT_C 0 "Do_Not_Actuate" 1 "Actuate";
VAL_ 346 IMPACT_D 0 "Do_Not_Actuate" 1 "Actuate";
VAL_ 346 IMPACT_E 0 "Do_Not_Actuate" 1 "Actuate";
VAL_ 346 IMPACT_F 0 "Do_Not_Actuate" 1 "Actuate";
VAL_ 346 IMPACT_G 0 "Do_Not_Actuate" 1 "Actuate";
VAL_ 346 IMPACT_H 0 "Do_Not_Actuate" 1 "Actuate";
VAL_ 346 IMPACT_I 0 "Do_Not_Actuate" 1 "Actuate";
VAL_ 346 IMPACT_K 0 "Do_Not_Actuate" 1 "Actuate";
VAL_ 346 IMPACT_L 0 "Do_Not_Actuate" 1 "Actuate";
VAL_ 346 IMPACT_M 0 "Do_Not_Actuate" 1 "Actuate";
VAL_ 346 IMPACT_O 0 "Do_Not_Actuate" 1 "Actuate";
VAL_ 346 IMPACTCommand 0 "Do_Not_Actuate" 1 "Actuate";
VAL_ 346 IMPACTConfirm 0 "Actuate" 1 "Do_Not_Actuate";
VAL_ 346 IMPACTFailSts 0 "Fail_Not_Present" 1 "Fail_Present";
VAL_ 1058 CurrBattFailStatus 0 "Fail_not_present" 1 "Fail_present";
VAL_ 1058 IBS3_Error_Internal 0 "No_error" 1 "Error";
VAL_ 1058 IBS3_Flag_Disconnect 0 "No_disconnect_since_last_key_cycle" 1 "Battery_disconnected_since_last_key_cycle";
VAL_ 1058 IBS3_Ibatt 65535 "SNA";
VAL_ 1058 IBS3_Rbatt 255 "SNA";
VAL_ 1058 IBS3_Rbatt_25 255 "SNA";
VAL_ 1058 IBS3_SOF_V_Accuracy 0 "Inaccurate" 1 "Accurate";
VAL_ 1058 IBS3_SOF_VC 127 "SNA";
VAL_ 1058 IBS3_Vbatt 511 "SNA";
VAL_ 1058 RsErrIBS3 0 "No_error" 1 "Error";
VAL_ 1058 VoltBattFailStatus 0 "Fail_not_present" 1 "Fail_present";
VAL_ 1060 IBS3_SOC 127 "SNA";
VAL_ 1060 IBS3_SOC_Accuracy 0 "Inaccurate" 1 "Accurate";
VAL_ 1060 IBS3_SOF_Q 255 "SNA";
VAL_ 1060 IBS3_SOF_Q_Accuracy 0 "Inaccurate" 1 "Accurate";
VAL_ 1060 IBS3_SOH_Q 127 "SNA";
VAL_ 1060 IBS3_SOH_Q_Accuracy 0 "Inaccurate" 1 "Accurate";
VAL_ 1060 IBS3_T_BATT 255 "SNA";
VAL_ 1060 IBS3_TempFailStatus 0 "Fail_not_present" 1 "Fail_present";
VAL_ 1062 IBS3_Q_Received 65535 "SNA";
VAL_ 1062 IBS3_Q_Released 65535 "SNA";
VAL_ 1062 IBS3_TmLstResetDays 4095 "SNA";
VAL_ 1062 IBS3_TmLstResetSec 65535 "SNA";
VAL_ 256 ECM_LHOM 0 "Not_In_Limp_Home" 1 "In_Limp_Home";
VAL_ 753 LatAcceleration 4095 "SNA";
VAL_ 753 LatAccelerationFailSts 0 "Fail_Not_Present" 1 "Fail_Present";
VAL_ 753 LongAcceleration 4095 "SNA";
VAL_ 753 LongAccelerationFailSts 0 "Fail_Not_Present" 1 "Fail_Present";
VAL_ 753 ZAcceleration 0 "Initialization" 4095 "SNA";
VAL_ 753 ZAccelerationFailSts 0 "Fail_Not_Present" 1 "Fail_Present";
VAL_ 1848 KeyProgramSts 0 "RKE_NORM_STAT" 1 "EN_KEY_PROG" 2 "PROG_ACT" 3 "EX_KEY_PROG" 4 "KEY_PROG" 5 "DMG_KEY" 6 "INV_KEY" 7 "EXCD_KEY" 8 "RKE_BATT_LO" 9 "SRV_SKREEM" 10 "BTN_DLY_ACT" 11 "BTN_DLY_INACT" 12 "KEY_NOT_PROG" 15 "SNA";
VAL_ 1848 MsgFOBLeftVeh 0 "MSG_DEFAULT" 1 "MSG_ACTIVE" 3 "SNA";
VAL_ 1848 MsgFOBNotFnd 0 "MSG_DEFAULT" 1 "MSG_ACTIVE" 3 "SNA";
VAL_ 1848 MsgParkSoon 0 "Not_Active" 1 "Active";
VAL_ 1848 MsgServPEKG 0 "MSG_DEFAULT" 1 "MSG_ACTIVE" 3 "SNA";
VAL_ 1848 StartButtonFailSts 0 "Fail_Not_Present" 1 "Fail_Present";
VAL_ 400 PRNDFailSts 0 "Fail_Not_Present" 1 "Fail_Present";
VAL_ 400 ShiftLeverFailSts 0 "Fail_not_present" 1 "Fail_present";
VAL_ 400 ShiftLeverPositionReq 0 "No_Selection_Active_Or_Available" 1 "P" 2 "R" 3 "N" 4 "D" 5 "L" 6 "TIP_Autostick" 7 "Plus" 8 "Minus" 9 "Sport" 10 "Both" 11 "Not_Used" 12 "Not_Used" 13 "Not_Used" 14 "Not_Used" 15 "SNA";
VAL_ 762 ACC_DistSwDec 0 "Not_Active" 1 "Active";
VAL_ 762 ACC_DistSwInc 0 "Not_Active" 1 "Active";
VAL_ 762 ACC_On 0 "Not_Active" 1 "Active";
VAL_ 762 AcceleratorSts 0 "Not_Active" 1 "Active";
VAL_ 762 CruiseControlFailSts 0 "Fail_Not_Present" 1 "Fail_Present";
VAL_ 762 CruiseControlOnOffSts 0 "Not_Active" 1 "Active";
VAL_ 762 CrusCnclSwitch 0 "Not_Active" 1 "Active";
VAL_ 762 DeceleratorSts 0 "Not_Active" 1 "Active";
VAL_ 762 LaneCenteringOnOffSts 0 "Not_Pressed" 1 "Pressed";
VAL_ 762 ResumeSwitch 0 "Not_Active" 1 "Active";
VAL_ 762 SpeedLimiterOnOffSts 0 "Not_Active" 1 "Active";
VAL_ 2654339129 DES_DASM 0 "Error_Active_state" 1 "Error_passive_warning_state" 2 "Bus_off_state" 3 "Not_used";
VAL_ 2654339129 EOL_DASM 0 "No_EOL_prog_at_FIAT" 1 "EOL_prog_at_FIAT";
VAL_ 2654339136 DES_EVCU 0 "Error_Active_state" 1 "Error_passive_warning_state" 2 "Bus_off_state" 3 "Not_used";
VAL_ 2654339136 EOL_EVCU 0 "No_EOL_prog_at_FIAT" 1 "EOL_prog_at_FIAT";
VAL_ 2654339075 DES_IPC 0 "Error_Active_state" 1 "Error_passive_warning_state" 2 "Bus_off_state" 3 "Not_used";
VAL_ 2654339075 EOL_IPC 0 "No_EOL_prog_at_FIAT" 1 "EOL_prog_at_FIAT";
VAL_ 2654339094 DES_Shifter 0 "Error_Active_state" 1 "Error_passive_warning_state" 2 "Bus_off_state" 3 "Not_used";
VAL_ 2654339094 EOL_Shifter 0 "No_EOL_prog_at_FIAT" 1 "EOL_prog_at_FIAT";
VAL_ 2654339107 DES_TBM 0 "Error_Active_state" 1 "Error_passive_warning_state" 2 "Bus_off_state" 3 "Not_used";
VAL_ 2654339107 EOL_TBM 0 "No_EOL_prog_at_FIAT" 1 "EOL_prog_at_FIAT";
VAL_ 1504 ClampForce 0 "Initialization" 511 "SNA";
VAL_ 1504 EPB_HMI_Management 0 "No_Ind" 1 "Ind1" 2 "Ind2" 3 "Ind3" 4 "Ind4" 5 "Ind5" 6 "Ind6" 7 "Ind7" 8 "Ind8" 9 "Ind9" 10 "Ind10" 11 "Ind11" 12 "Ind12" 13 "Ind13" 14 "Ind14" 15 "Ind15" 16 "Ind16" 17 "Ind17" 18 "Ind18" 19 "Ind19" 20 "Ind20" 21 "Ind21" 22 "Ind22" 23 "Ind23" 24 "Ind24" 25 "Ind25" 26 "Ind26" 27 "Ind27" 28 "Ind28" 29 "Ind29" 30 "Ind30" 31 "Ind31";
VAL_ 1504 EPBAutoAppSts 0 "AutoApply_Disable" 1 "AutoApply_Enable";
VAL_ 1504 EPBFailureLampReq 0 "lamp off" 1 "lamp on";
VAL_ 1504 EPBMaintenanceSts 0 "Maintenance_Disabled" 1 "Maintenance_Enabled";
VAL_ 1504 EPBSts 0 "Released" 1 "Applied" 2 "DynamicBrkESC" 3 "DynamicBrkEPB" 4 "Emergency_Braking" 5 "Applying" 6 "Maintenance_Mode" 7 "Assembly_Check" 8 "Inspection_Mode" 9 "Re_Clamping" 10 "Adjuste_Mode" 11 "Releasing" 12 "Fault_EPB_Released" 13 "Fault_EPB_Applied" 14 "Fault_Present" 15 "SNA";
VAL_ 1504 EPBSwitchPosition 0 "No request" 1 "Release request" 2 "Apply request" 3 "Error";
VAL_ 1504 FastTransmission_SE 0 "Slow" 1 "Fast";
VAL_ 1941 PowerModeSts_EVCU 0 "Standard_Power" 1 "Logistic_Mode_ON" 2 "Logistic_Mode_PR";
VAL_ 896 ReliableOvertaking 0 "New" 1 "Old";
VAL_ 896 ReliableTSISign 0 "Not_Active" 1 "Active";
VAL_ 896 ReliableVehicleSpdLimit 0 "New" 1 "Old";
VAL_ 896 ReliableVehicleSpdLimitCond 0 "New" 1 "Old";
VAL_ 896 SignOvertaking 0 "Sign_Not_Detected" 1 "Overtaking" 2 "No_Overtaking";
VAL_ 896 SignSupplemOvertaking 0 "Sign_Not_Detected" 1 "Generic_Sign" 2 "Fog" 3 "Rain" 4 "Snow" 5 "Trailer" 6 "Time" 7 "Right_Arrow" 8 "Left_Arrow" 9 "Night" 10 "School" 15 "End_Limit";
VAL_ 896 SignSupplemVehicleSpeedLimit 0 "Sign_Not_Detected" 1 "Generic_Sign" 2 "Fog" 3 "Rain" 4 "Snow" 5 "Trailer" 6 "Time" 7 "Right_Arrow" 8 "Left_Arrow" 9 "Night" 10 "School" 11 "School_Zone" 12 "Work_Zone" 13 "Truck" 15 "End_Limit";
VAL_ 896 SignVehicleSpeedLimit 0 "Sign_Not_Detected" 1 "Speed_Limit_5" 2 "Speed_Limit_10" 3 "Speed_Limit_15" 4 "Speed_Limit_20" 5 "Speed_Limit_25" 6 "Speed_Limit_30" 7 "Speed_Limit_35" 8 "Speed_Limit_40" 9 "Speed_Limit_45" 10 "Speed_Limit_50" 11 "Speed_Limit_55" 12 "Speed_Limit_60" 13 "Speed_Limit_65" 14 "Speed_Limit_70" 15 "Speed_Limit_75" 16 "Speed_Limit_80" 17 "Speed_Limit_85" 18 "Speed_Limit_90" 19 "Speed_Limit_95" 20 "Speed_Limit_100" 21 "Speed_Limit_105" 22 "Speed_Limit_110" 23 "Speed_Limit_115" 24 "Speed_Limit_120" 25 "Speed_Limit_125" 26 "Speed_Limit_130" 27 "Speed_Limit_135" 28 "Speed_Limit_140" 29 "Speed_Limit_145" 62 "Speed_Limit_Unlimited" 63 "End_Speed_Limit";
VAL_ 896 SignVehicleSpeedLimitConditional 0 "Sign_Not_Detected" 1 "Speed_Limit_5" 2 "Speed_Limit_10" 3 "Speed_Limit_15" 4 "Speed_Limit_20" 5 "Speed_Limit_25" 6 "Speed_Limit_30" 7 "Speed_Limit_35" 8 "Speed_Limit_40" 9 "Speed_Limit_45" 10 "Speed_Limit_50" 11 "Speed_Limit_55" 12 "Speed_Limit_60" 13 "Speed_Limit_65" 14 "Speed_Limit_70" 15 "Speed_Limit_75" 16 "Speed_Limit_80" 17 "Speed_Limit_85" 18 "Speed_Limit_90" 19 "Speed_Limit_95" 20 "Speed_Limit_100" 21 "Speed_Limit_105" 22 "Speed_Limit_110" 23 "Speed_Limit_115" 24 "Speed_Limit_120" 25 "Speed_Limit_125" 26 "Speed_Limit_130" 27 "Speed_Limit_135" 28 "Speed_Limit_140" 29 "Speed_Limit_145" 62 "Speed_Limit_Unlimited" 63 "End_Speed_Limit";
VAL_ 896 SpeedLimitFilter 0 "Inconditional" 1 "Conditional";
VAL_ 896 TSRSts 0 "Not_Active" 1 "Active" 2 "Blinded" 3 "Fault";
VAL_ 1475 TBM_Batt_CabinPriority1 0 "Checkbox Unselected" 1 "Checkbox Selected";
VAL_ 1475 TBM_ChargeUntilFull1 0 "Charge Until Full Not selected" 1 "Charge Until Full";
VAL_ 1475 TBM_Do_Not_Repeat1 0 "Repeat (Unchecked)" 1 "Do Not Repeat (Checked)";
VAL_ 1475 TBM_Enable_Schedule1 0 "Disable schedule1" 1 "Enable schedule1";
VAL_ 1475 TBM_End_Time_Hr1 31 "SNA";
VAL_ 1475 TBM_End_Time_Min1 15 "SNA";
VAL_ 1475 TBM_Schedule_Day1 0 "No Selection" 1 "M" 2 "T" 3 "TM" 4 "W" 5 "WM" 6 "WT" 7 "WTM" 8 "Th" 9 "ThM" 10 "ThT" 11 "ThTM" 12 "ThW" 13 "ThWM" 14 "ThWT" 15 "ThWTM" 16 "F" 17 "FM" 18 "FT" 19 "FTM" 20 "FW" 21 "FWM" 22 "FWT" 23 "FWTM" 24 "FTh" 25 "FThM" 26 "FThT" 27 "FThTM" 28 "FThW" 29 "FThWM" 30 "FThWT" 31 "FThWTM" 32 "S" 33 "SM" 34 "ST" 35 "STM" 36 "SW" 37 "SWM" 38 "SWT" 39 "SWTM" 40 "STh" 41 "SThM" 42 "SThT" 43 "SThTM" 44 "SThW" 45 "SThWM" 46 "SThWT" 47 "SThWTM" 48 "SF" 49 "SFM" 50 "SFT" 51 "SFTM" 52 "SFW" 53 "SFWM" 54 "SFWT" 55 "SFWTM" 56 "SFTh" 57 "SFThM" 58 "SFThT" 59 "SFThTM" 60 "SFThW" 61 "SFThWM" 62 "SFThWT" 63 "SFThWTM" 64 "Sa" 65 "SaM" 66 "SaT" 67 "SaTM" 68 "SaW" 69 "SaWM" 70 "SaWT" 71 "SaWTM" 72 "SaTh" 73 "SaThM" 74 "SaThT" 75 "SaThTM" 76 "SaThW" 77 "SaThWM" 78 "SaThWT" 79 "SaThWTM" 80 "SaF" 81 "SaFM" 82 "SaFT" 83 "SaFTM" 84 "SaFW" 85 "SaFWM" 86 "SaFWT" 87 "SaFWTM" 88 "SaFTh" 89 "SaFThM" 90 "SaFThT" 91 "SaFThTM" 92 "SaFThW" 93 "SaFThWM" 94 "SaFThWT" 95 "SaFThWTM" 96 "SaS" 97 "SaSM" 98 "SaST" 99 "SaSTM" 100 "SaSW" 101 "SaSWM" 102 "SaSWT" 103 "SaSWTM" 104 "SaSTh" 105 "SaSThM" 106 "SaSThT" 107 "SaSThTM" 108 "SaSThW" 109 "SaSThWM" 110 "SaSThWT" 111 "SaSThWTM" 112 "SaSF" 113 "SaSFM" 114 "SaSFT" 115 "SaSFTM" 116 "SaSFW" 117 "SaSFWM" 118 "SaSFWT" 119 "SaSFWTM" 120 "SaSFTh" 121 "SaSFThM" 122 "SaSFThT" 123 "SaSFThTM" 124 "SaSFThW" 125 "SaSFThWM" 126 "SaSFThWT" 127 "SaSFThWTM" 255 "SNA";
VAL_ 1475 TBM_Schedule_Type1 0 "No Selection" 1 "Departure Time" 2 "Charge Interval" 3 "SNA";
VAL_ 1475 TBM_Start_Time_Hr1 31 "SNA";
VAL_ 1475 TBM_Start_Time_Min1 15 "SNA";
VAL_ 1475 TBM_Submit_Schedule1 0 "No Change" 1 "Change in schedule 1";
VAL_ 1473 TBM_Batt_CabinPriority2 0 "Checkbox Unselected" 1 "Checkbox Selected";
VAL_ 1473 TBM_ChargeUntilFull2 0 "Charge Until Full Not selected" 1 "Charge Until Full";
VAL_ 1473 TBM_Do_Not_Repeat2 0 "Repeat (Unchecked)" 1 "Do Not Repeat (Checked)";
VAL_ 1473 TBM_Enable_Schedule2 0 "Disable schedule1" 1 "Enable schedule1";
VAL_ 1473 TBM_End_Time_Hr2 31 "SNA";
VAL_ 1473 TBM_End_Time_Min2 15 "SNA";
VAL_ 1473 TBM_Schedule_Day2 0 "No Selection" 1 "M" 2 "T" 3 "TM" 4 "W" 5 "WM" 6 "WT" 7 "WTM" 8 "Th" 9 "ThM" 10 "ThT" 11 "ThTM" 12 "ThW" 13 "ThWM" 14 "ThWT" 15 "ThWTM" 16 "F" 17 "FM" 18 "FT" 19 "FTM" 20 "FW" 21 "FWM" 22 "FWT" 23 "FWTM" 24 "FTh" 25 "FThM" 26 "FThT" 27 "FThTM" 28 "FThW" 29 "FThWM" 30 "FThWT" 31 "FThWTM" 32 "S" 33 "SM" 34 "ST" 35 "STM" 36 "SW" 37 "SWM" 38 "SWT" 39 "SWTM" 40 "STh" 41 "SThM" 42 "SThT" 43 "SThTM" 44 "SThW" 45 "SThWM" 46 "SThWT" 47 "SThWTM" 48 "SF" 49 "SFM" 50 "SFT" 51 "SFTM" 52 "SFW" 53 "SFWM" 54 "SFWT" 55 "SFWTM" 56 "SFTh" 57 "SFThM" 58 "SFThT" 59 "SFThTM" 60 "SFThW" 61 "SFThWM" 62 "SFThWT" 63 "SFThWTM" 64 "Sa" 65 "SaM" 66 "SaT" 67 "SaTM" 68 "SaW" 69 "SaWM" 70 "SaWT" 71 "SaWTM" 72 "SaTh" 73 "SaThM" 74 "SaThT" 75 "SaThTM" 76 "SaThW" 77 "SaThWM" 78 "SaThWT" 79 "SaThWTM" 80 "SaF" 81 "SaFM" 82 "SaFT" 83 "SaFTM" 84 "SaFW" 85 "SaFWM" 86 "SaFWT" 87 "SaFWTM" 88 "SaFTh" 89 "SaFThM" 90 "SaFThT" 91 "SaFThTM" 92 "SaFThW" 93 "SaFThWM" 94 "SaFThWT" 95 "SaFThWTM" 96 "SaS" 97 "SaSM" 98 "SaST" 99 "SaSTM" 100 "SaSW" 101 "SaSWM" 102 "SaSWT" 103 "SaSWTM" 104 "SaSTh" 105 "SaSThM" 106 "SaSThT" 107 "SaSThTM" 108 "SaSThW" 109 "SaSThWM" 110 "SaSThWT" 111 "SaSThWTM" 112 "SaSF" 113 "SaSFM" 114 "SaSFT" 115 "SaSFTM" 116 "SaSFW" 117 "SaSFWM" 118 "SaSFWT" 119 "SaSFWTM" 120 "SaSFTh" 121 "SaSFThM" 122 "SaSFThT" 123 "SaSFThTM" 124 "SaSFThW" 125 "SaSFThWM" 126 "SaSFThWT" 127 "SaSFThWTM" 255 "SNA";
VAL_ 1473 TBM_Schedule_Type2 0 "No Selection" 1 "Departure Time" 2 "Charge Interval" 3 "SNA";
VAL_ 1473 TBM_Start_Time_Hr2 31 "SNA";
VAL_ 1473 TBM_Start_Time_Min2 15 "SNA";
VAL_ 1473 TBM_Submit_Schedule2 0 "No Change" 1 "Change in schedule 1";
VAL_ 1474 TBM_Batt_CabinPriority3 0 "Checkbox Unselected" 1 "Checkbox Selected";
VAL_ 1474 TBM_ChargeUntilFull3 0 "Charge Until Full Not selected" 1 "Charge Until Full";
VAL_ 1474 TBM_Do_Not_Repeat3 0 "Repeat (Unchecked)" 1 "Do Not Repeat (Checked)";
VAL_ 1474 TBM_Enable_Schedule3 0 "Disable schedule1" 1 "Enable schedule1";
VAL_ 1474 TBM_End_Time_Hr3 31 "SNA";
VAL_ 1474 TBM_End_Time_Min3 15 "SNA";
VAL_ 1474 TBM_Schedule_Day3 0 "No Selection" 1 "M" 2 "T" 3 "TM" 4 "W" 5 "WM" 6 "WT" 7 "WTM" 8 "Th" 9 "ThM" 10 "ThT" 11 "ThTM" 12 "ThW" 13 "ThWM" 14 "ThWT" 15 "ThWTM" 16 "F" 17 "FM" 18 "FT" 19 "FTM" 20 "FW" 21 "FWM" 22 "FWT" 23 "FWTM" 24 "FTh" 25 "FThM" 26 "FThT" 27 "FThTM" 28 "FThW" 29 "FThWM" 30 "FThWT" 31 "FThWTM" 32 "S" 33 "SM" 34 "ST" 35 "STM" 36 "SW" 37 "SWM" 38 "SWT" 39 "SWTM" 40 "STh" 41 "SThM" 42 "SThT" 43 "SThTM" 44 "SThW" 45 "SThWM" 46 "SThWT" 47 "SThWTM" 48 "SF" 49 "SFM" 50 "SFT" 51 "SFTM" 52 "SFW" 53 "SFWM" 54 "SFWT" 55 "SFWTM" 56 "SFTh" 57 "SFThM" 58 "SFThT" 59 "SFThTM" 60 "SFThW" 61 "SFThWM" 62 "SFThWT" 63 "SFThWTM" 64 "Sa" 65 "SaM" 66 "SaT" 67 "SaTM" 68 "SaW" 69 "SaWM" 70 "SaWT" 71 "SaWTM" 72 "SaTh" 73 "SaThM" 74 "SaThT" 75 "SaThTM" 76 "SaThW" 77 "SaThWM" 78 "SaThWT" 79 "SaThWTM" 80 "SaF" 81 "SaFM" 82 "SaFT" 83 "SaFTM" 84 "SaFW" 85 "SaFWM" 86 "SaFWT" 87 "SaFWTM" 88 "SaFTh" 89 "SaFThM" 90 "SaFThT" 91 "SaFThTM" 92 "SaFThW" 93 "SaFThWM" 94 "SaFThWT" 95 "SaFThWTM" 96 "SaS" 97 "SaSM" 98 "SaST" 99 "SaSTM" 100 "SaSW" 101 "SaSWM" 102 "SaSWT" 103 "SaSWTM" 104 "SaSTh" 105 "SaSThM" 106 "SaSThT" 107 "SaSThTM" 108 "SaSThW" 109 "SaSThWM" 110 "SaSThWT" 111 "SaSThWTM" 112 "SaSF" 113 "SaSFM" 114 "SaSFT" 115 "SaSFTM" 116 "SaSFW" 117 "SaSFWM" 118 "SaSFWT" 119 "SaSFWTM" 120 "SaSFTh" 121 "SaSFThM" 122 "SaSFThT" 123 "SaSFThTM" 124 "SaSFThW" 125 "SaSFThWM" 126 "SaSFThWT" 127 "SaSFThWTM" 255 "SNA";
VAL_ 1474 TBM_Schedule_Type3 0 "No Selection" 1 "Departure Time" 2 "Charge Interval" 3 "SNA";
VAL_ 1474 TBM_Start_Time_Hr3 31 "SNA";
VAL_ 1474 TBM_Start_Time_Min3 15 "SNA";
VAL_ 1474 TBM_Submit_Schedule3 0 "No Change" 1 "Change in schedule 1";
VAL_ 1000 CalibrationAck 0 "Idle" 1 "Accepted " 2 "Rejected" 3 "Not_Used";
VAL_ 1000 CalibrationSts 0 "Calibrated" 1 "Under calibration" 2 "Not Calibrated" 3 "Not_Used";
VAL_ 1448 BuzzerReqSts_T2 0 "OFF" 1 "Reverse_Gear_Sound_ON" 2 "Others_case_Sound_ON" 3 "Not_used";
VAL_ 1448 GearIndicationSts 0 "Normal" 1 "Blinking";
VAL_ 1448 ParkingFailSts 0 "Fail_not_present" 1 "Fail_present";
VAL_ 1448 ParkingSts 0 "Not_Parking" 1 "Parking";
VAL_ 1448 ShiftLeverPosition 0 "No_Selection_Active_Or_Available" 1 "P" 2 "R" 3 "N" 4 "D" 5 "L" 6 "TIP_Autostick" 7 "Plus" 8 "Minus" 9 "Sport" 10 "Not_Used" 11 "Not_Used" 12 "Not_Used" 13 "Not_Used" 14 "Not_Used" 15 "SNA";
VAL_ 1448 TransmissionWarnings 0 "No_Warning" 1 "Press_Brake_Pedal" 2 "Tip_Not_Available" 3 "Lower_Gear_Shifts" 4 "Manual_Mode_Not_Available" 5 "Insert_N" 6 "Automatic_Mode_Not_Available" 7 "Press_Brake_Delayed_Startup_Warning" 8 "Clutch_Overtemperature" 9 "Manoeuvre_Not_Allowed" 10 "Press_Brake_Pedal_Repeat" 11 "Gear_Not_Available" 12 "Shift_Not_Allowed" 13 "Shift_to_Neutral_Then_DR" 14 "Reduce_Gear_Changes" 15 "Clutch_Overheater_Must_Cool" 16 "Service_Transmission" 17 "Service_Shifter" 18 "Engage_Park_Brake" 19 "Trans_Too_Cold_Pls_Wait" 20 "Push_Button_to_Shift" 21 "Return_Shifter_To_Home" 22 "Press_Brake_Push_Button_Shift" 23 "Service_Trans_Shut_Off" 24 "Already_in_Des_Gear" 25 "Start_Engine_to_Shift" 26 "Service_Trans_Use_Pk_Brk" 27 "Vehicle_Speed_Too_High" 28 "Tow_Haul_Not_available" 29 "Tow_Haul_Disengaged" 30 "Trans_Cool_Ready_to_Drive" 31 "Vehicle_Speed_Too_High_to_Shift_P" 32 "Vehicle_Speed_Too_High_to_Shift_R" 33 "Vehicle_Speed_Too_High_to_Shift_D" 34 "Manual_Shift_Temp_Not_Available" 35 "Vehicle_Speed_Too_High_to_Shift_L/S" 36 "Shift_to_Park_to_ obtain_drivability" 37 "Shift_to_Park_to_Start" 38 "APCM_in_Progress" 39 "Stop Vehicle to Shift" 40 "Service Transmission_Stop Vehicle to Shift" 41 "Service Transmission__Stop Vehicle_Restart Vehicle in P to Continue Driving" 42 "Service Transmission_Stop Vehicle to Shift _Restart Vehicle in P to Continue Driving" 43 "Press Brake To Prevent Vehicle From Rolling" 45 "Trans_Recover_Mode_Warning" 46 "Press_Brake_To_Start" 47 "Shift_to_Park";
VAL_ 344 Vehicle_Hold_Rq 0 "Not_Active" 1 "Active";
VAL_ 253 TxpFound 0 "Transponder_Read" 1 "Transponder_Absent";
VAL_ 253 TxpID 0 "Transponder_Not_Authenticated" 1 "Transponder_1_Authenticated" 2 "Transponder_2_Authenticated" 3 "Transponder_3_Authenticated" 4 "Transponder_4_Authenticated" 5 "Transponder_5_Authenticated" 6 "Transponder_6_Authenticated" 7 "Transponder_7_Authenticated" 8 "Transponder_8_Authenticated" 9 "Transponder_9_Authenticated" 10 "Transponder_10_Authenticated" 11 "Transponder_11_Authenticated" 12 "Transponder_12_Authenticated" 13 "Transponder_13_Authenticated" 14 "Transponder_14_Authenticated" 15 "Transponder_15_Authenticated";
VAL_ 1046 VIN_MSG 0 "VIN_LO" 1 "VIN_MID" 2 "VIN_HI" 3 "SNA";
VAL_ 2654208000 MainWakeSts_BCM 0 "Not_Active" 1 "Active";
VAL_ 2654208000 Node0 0 "Not_active" 1 "Active";
VAL_ 2654208000 Node1 0 "Not_active" 1 "Active";
VAL_ 2654208000 Node10 0 "Not_active" 1 "Active";
VAL_ 2654208000 Node11 0 "Not_active" 1 "Active";
VAL_ 2654208000 Node12 0 "Not_active" 1 "Active";
VAL_ 2654208000 Node13 0 "Not_active" 1 "Active";
VAL_ 2654208000 Node14 0 "Not_active" 1 "Active";
VAL_ 2654208000 Node15 0 "Not_active" 1 "Active";
VAL_ 2654208000 Node16 0 "Not_active" 1 "Active";
VAL_ 2654208000 Node17 0 "Not_active" 1 "Active";
VAL_ 2654208000 Node18 0 "Not_active" 1 "Active";
VAL_ 2654208000 Node19 0 "Not_active" 1 "Active";
VAL_ 2654208000 Node2 0 "Not_active" 1 "Active";
VAL_ 2654208000 Node20 0 "Not_active" 1 "Active";
VAL_ 2654208000 Node21 0 "Not_active" 1 "Active";
VAL_ 2654208000 Node22 0 "Not_active" 1 "Active";
VAL_ 2654208000 Node23 0 "Not_active" 1 "Active";
VAL_ 2654208000 Node24 0 "Not_active" 1 "Active";
VAL_ 2654208000 Node25 0 "Not_active" 1 "Active";
VAL_ 2654208000 Node26 0 "Not_active" 1 "Active";
VAL_ 2654208000 Node27 0 "Not_active" 1 "Active";
VAL_ 2654208000 Node28 0 "Not_active" 1 "Active";
VAL_ 2654208000 Node29 0 "Not_active" 1 "Active";
VAL_ 2654208000 Node3 0 "Not_active" 1 "Active";
VAL_ 2654208000 Node30 0 "Not_active" 1 "Active";
VAL_ 2654208000 Node31 0 "Not_active" 1 "Active";
VAL_ 2654208000 Node4 0 "Not_active" 1 "Active";
VAL_ 2654208000 Node5 0 "Not_active" 1 "Active";
VAL_ 2654208000 Node6 0 "Not_active" 1 "Active";
VAL_ 2654208000 Node7 0 "Not_active" 1 "Active";
VAL_ 2654208000 Node8 0 "Not_active" 1 "Active";
VAL_ 2654208000 Node9 0 "Not_active" 1 "Active";
VAL_ 2654208000 WakeRsn_BCM 0 "Diag" 1 "Network" 2 "WakeRsn2" 3 "WakeRsn3" 4 "WakeRsn4" 5 "WakeRsn5" 6 "WakeRsn6" 7 "WakeRsn7" 8 "WakeRsn8" 9 "WakeRsn9" 10 "WakeRsn10" 11 "WakeRsn11" 12 "WakeRsn12" 13 "WakeRsn13" 14 "WakeRsn14" 15 "WakeRsn15" 16 "WakeRsn16" 17 "WakeRsn17" 18 "WakeRsn18" 19 "WakeRsn19" 20 "WakeRsn20" 21 "WakeRsn21" 22 "WakeRsn22" 23 "WakeRsn23" 24 "WakeRsn24" 25 "WakeRsn25" 26 "WakeRsn26" 27 "WakeRsn27" 28 "WakeRsn28" 29 "WakeRsn29" 30 "WakeRsn30" 31 "WakeRsn31" 32 "WakeRsn32" 33 "WakeRsn33" 34 "WakeRsn34" 35 "WakeRsn35" 36 "WakeRsn36" 37 "WakeRsn37" 38 "WakeRsn38" 39 "WakeRsn39" 40 "WakeRsn40" 41 "WakeRsn41" 42 "WakeRsn42" 43 "WakeRsn43" 44 "WakeRsn44" 45 "WakeRsn45" 46 "WakeRsn46" 47 "WakeRsn47" 48 "WakeRsn48" 49 "WakeRsn49" 50 "WakeRsn50" 51 "WakeRsn51" 52 "WakeRsn52" 53 "WakeRsn53" 54 "WakeRsn54" 55 "WakeRsn55" 56 "WakeRsn56" 57 "WakeRsn57" 58 "WakeRsn58" 59 "WakeRsn59" 60 "WakeRsn60" 61 "WakeRsn61" 62 "WakeRsn62" 63 "WakeRsn63" 64 "WakeRsn64" 65 "WakeRsn65" 66 "WakeRsn66" 67 "WakeRsn67" 68 "WakeRsn68" 69 "WakeRsn69" 70 "WakeRsn70" 71 "WakeRsn71" 72 "WakeRsn72" 73 "WakeRsn73" 74 "WakeRsn74" 75 "WakeRsn75" 76 "WakeRsn76" 77 "WakeRsn77" 78 "WakeRsn78" 79 "WakeRsn79" 80 "WakeRsn80" 81 "WakeRsn81" 82 "WakeRsn82" 83 "WakeRsn83" 84 "WakeRsn84" 85 "WakeRsn85" 86 "WakeRsn86" 87 "WakeRsn87" 88 "WakeRsn88" 89 "WakeRsn89" 90 "WakeRsn90" 91 "WakeRsn91" 92 "WakeRsn92" 93 "WakeRsn93" 94 "WakeRsn94" 95 "WakeRsn95" 96 "WakeRsn96" 97 "WakeRsn97" 98 "WakeRsn98" 99 "WakeRsn99" 100 "WakeRsn100" 101 "WakeRsn101" 102 "WakeRsn102" 103 "WakeRsn103" 104 "WakeRsn104" 105 "WakeRsn105" 106 "WakeRsn106" 107 "WakeRsn107" 108 "WakeRsn108" 109 "WakeRsn109" 110 "WakeRsn110" 111 "WakeRsn111" 112 "WakeRsn112" 113 "WakeRsn113" 114 "WakeRsn114" 115 "WakeRsn115" 116 "WakeRsn116" 117 "WakeRsn117" 118 "WakeRsn118" 119 "WakeRsn119" 120 "WakeRsn120" 121 "WakeRsn121" 122 "WakeRsn122" 123 "WakeRsn123" 124 "WakeRsn124" 125 "WakeRsn125" 126 "WakeRsn126" 127 "WakeRsn127";
VAL_ 2654208006 WakeReq_BSM 0 "NotActive" 1 "Active";
VAL_ 2654208006 WakeRsn_BSM 0 "Diag" 1 "Network" 2 "WakeRsn2" 3 "WakeRsn3" 4 "WakeRsn4" 5 "WakeRsn5" 6 "WakeRsn6" 7 "WakeRsn7" 8 "WakeRsn8" 9 "WakeRsn9" 10 "WakeRsn10" 11 "WakeRsn11" 12 "WakeRsn12" 13 "WakeRsn13" 14 "WakeRsn14" 15 "WakeRsn15" 16 "WakeRsn16" 17 "WakeRsn17" 18 "WakeRsn18" 19 "WakeRsn19" 20 "WakeRsn20" 21 "WakeRsn21" 22 "WakeRsn22" 23 "WakeRsn23" 24 "WakeRsn24" 25 "WakeRsn25" 26 "WakeRsn26" 27 "WakeRsn27" 28 "WakeRsn28" 29 "WakeRsn29" 30 "WakeRsn30" 31 "WakeRsn31" 32 "WakeRsn32" 33 "WakeRsn33" 34 "WakeRsn34" 35 "WakeRsn35" 36 "WakeRsn36" 37 "WakeRsn37" 38 "WakeRsn38" 39 "WakeRsn39" 40 "WakeRsn40" 41 "WakeRsn41" 42 "WakeRsn42" 43 "WakeRsn43" 44 "WakeRsn44" 45 "WakeRsn45" 46 "WakeRsn46" 47 "WakeRsn47" 48 "WakeRsn48" 49 "WakeRsn49" 50 "WakeRsn50" 51 "WakeRsn51" 52 "WakeRsn52" 53 "WakeRsn53" 54 "WakeRsn54" 55 "WakeRsn55" 56 "WakeRsn56" 57 "WakeRsn57" 58 "WakeRsn58" 59 "WakeRsn59" 60 "WakeRsn60" 61 "WakeRsn61" 62 "WakeRsn62" 63 "WakeRsn63" 64 "WakeRsn64" 65 "WakeRsn65" 66 "WakeRsn66" 67 "WakeRsn67" 68 "WakeRsn68" 69 "WakeRsn69" 70 "WakeRsn70" 71 "WakeRsn71" 72 "WakeRsn72" 73 "WakeRsn73" 74 "WakeRsn74" 75 "WakeRsn75" 76 "WakeRsn76" 77 "WakeRsn77" 78 "WakeRsn78" 79 "WakeRsn79" 80 "WakeRsn80" 81 "WakeRsn81" 82 "WakeRsn82" 83 "WakeRsn83" 84 "WakeRsn84" 85 "WakeRsn85" 86 "WakeRsn86" 87 "WakeRsn87" 88 "WakeRsn88" 89 "WakeRsn89" 90 "WakeRsn90" 91 "WakeRsn91" 92 "WakeRsn92" 93 "WakeRsn93" 94 "WakeRsn94" 95 "WakeRsn95" 96 "WakeRsn96" 97 "WakeRsn97" 98 "WakeRsn98" 99 "WakeRsn99" 100 "WakeRsn100" 101 "WakeRsn101" 102 "WakeRsn102" 103 "WakeRsn103" 104 "WakeRsn104" 105 "WakeRsn105" 106 "WakeRsn106" 107 "WakeRsn107" 108 "WakeRsn108" 109 "WakeRsn109" 110 "WakeRsn110" 111 "WakeRsn111" 112 "WakeRsn112" 113 "WakeRsn113" 114 "WakeRsn114" 115 "WakeRsn115" 116 "WakeRsn116" 117 "WakeRsn117" 118 "WakeRsn118" 119 "WakeRsn119" 120 "WakeRsn120" 121 "WakeRsn121" 122 "WakeRsn122" 123 "WakeRsn123" 124 "WakeRsn124" 125 "WakeRsn125" 126 "WakeRsn126" 127 "WakeRsn127";
VAL_ 2654208064 WakeReq_EVCU 0 "NotActive" 1 "Active";
VAL_ 2654208064 WakeRsn_EVCU 0 "Diag" 1 "Network" 2 "WakeRsn2" 3 "WakeRsn3" 4 "WakeRsn4" 5 "WakeRsn5" 6 "WakeRsn6" 7 "WakeRsn7" 8 "WakeRsn8" 9 "WakeRsn9" 10 "WakeRsn10" 11 "WakeRsn11" 12 "WakeRsn12" 13 "WakeRsn13" 14 "WakeRsn14" 15 "WakeRsn15" 16 "WakeRsn16" 17 "WakeRsn17" 18 "WakeRsn18" 19 "WakeRsn19" 20 "WakeRsn20" 21 "WakeRsn21" 22 "WakeRsn22" 23 "WakeRsn23" 24 "WakeRsn24" 25 "WakeRsn25" 26 "WakeRsn26" 27 "WakeRsn27" 28 "WakeRsn28" 29 "WakeRsn29" 30 "WakeRsn30" 31 "WakeRsn31" 32 "WakeRsn32" 33 "WakeRsn33" 34 "WakeRsn34" 35 "WakeRsn35" 36 "WakeRsn36" 37 "WakeRsn37" 38 "WakeRsn38" 39 "WakeRsn39" 40 "WakeRsn40" 41 "WakeRsn41" 42 "WakeRsn42" 43 "WakeRsn43" 44 "WakeRsn44" 45 "WakeRsn45" 46 "WakeRsn46" 47 "WakeRsn47" 48 "WakeRsn48" 49 "WakeRsn49" 50 "WakeRsn50" 51 "WakeRsn51" 52 "WakeRsn52" 53 "WakeRsn53" 54 "WakeRsn54" 55 "WakeRsn55" 56 "WakeRsn56" 57 "WakeRsn57" 58 "WakeRsn58" 59 "WakeRsn59" 60 "WakeRsn60" 61 "WakeRsn61" 62 "WakeRsn62" 63 "WakeRsn63" 64 "WakeRsn64" 65 "WakeRsn65" 66 "WakeRsn66" 67 "WakeRsn67" 68 "WakeRsn68" 69 "WakeRsn69" 70 "WakeRsn70" 71 "WakeRsn71" 72 "WakeRsn72" 73 "WakeRsn73" 74 "WakeRsn74" 75 "WakeRsn75" 76 "WakeRsn76" 77 "WakeRsn77" 78 "WakeRsn78" 79 "WakeRsn79" 80 "WakeRsn80" 81 "WakeRsn81" 82 "WakeRsn82" 83 "WakeRsn83" 84 "WakeRsn84" 85 "WakeRsn85" 86 "WakeRsn86" 87 "WakeRsn87" 88 "WakeRsn88" 89 "WakeRsn89" 90 "WakeRsn90" 91 "WakeRsn91" 92 "WakeRsn92" 93 "WakeRsn93" 94 "WakeRsn94" 95 "WakeRsn95" 96 "WakeRsn96" 97 "WakeRsn97" 98 "WakeRsn98" 99 "WakeRsn99" 100 "WakeRsn100" 101 "WakeRsn101" 102 "WakeRsn102" 103 "WakeRsn103" 104 "WakeRsn104" 105 "WakeRsn105" 106 "WakeRsn106" 107 "WakeRsn107" 108 "WakeRsn108" 109 "WakeRsn109" 110 "WakeRsn110" 111 "WakeRsn111" 112 "WakeRsn112" 113 "WakeRsn113" 114 "WakeRsn114" 115 "WakeRsn115" 116 "WakeRsn116" 117 "WakeRsn117" 118 "WakeRsn118" 119 "WakeRsn119" 120 "WakeRsn120" 121 "WakeRsn121" 122 "WakeRsn122" 123 "WakeRsn123" 124 "WakeRsn124" 125 "WakeRsn125" 126 "WakeRsn126" 127 "WakeRsn127";
VAL_ 2654208003 WakeReq_IPC 0 "NotActive" 1 "Active";
VAL_ 2654208003 WakeRsn_IPC 0 "Diag" 1 "Network" 2 "WakeRsn2" 3 "WakeRsn3" 4 "WakeRsn4" 5 "WakeRsn5" 6 "WakeRsn6" 7 "WakeRsn7" 8 "WakeRsn8" 9 "WakeRsn9" 10 "WakeRsn10" 11 "WakeRsn11" 12 "WakeRsn12" 13 "WakeRsn13" 14 "WakeRsn14" 15 "WakeRsn15" 16 "WakeRsn16" 17 "WakeRsn17" 18 "WakeRsn18" 19 "WakeRsn19" 20 "WakeRsn20" 21 "WakeRsn21" 22 "WakeRsn22" 23 "WakeRsn23" 24 "WakeRsn24" 25 "WakeRsn25" 26 "WakeRsn26" 27 "WakeRsn27" 28 "WakeRsn28" 29 "WakeRsn29" 30 "WakeRsn30" 31 "WakeRsn31" 32 "WakeRsn32" 33 "WakeRsn33" 34 "WakeRsn34" 35 "WakeRsn35" 36 "WakeRsn36" 37 "WakeRsn37" 38 "WakeRsn38" 39 "WakeRsn39" 40 "WakeRsn40" 41 "WakeRsn41" 42 "WakeRsn42" 43 "WakeRsn43" 44 "WakeRsn44" 45 "WakeRsn45" 46 "WakeRsn46" 47 "WakeRsn47" 48 "WakeRsn48" 49 "WakeRsn49" 50 "WakeRsn50" 51 "WakeRsn51" 52 "WakeRsn52" 53 "WakeRsn53" 54 "WakeRsn54" 55 "WakeRsn55" 56 "WakeRsn56" 57 "WakeRsn57" 58 "WakeRsn58" 59 "WakeRsn59" 60 "WakeRsn60" 61 "WakeRsn61" 62 "WakeRsn62" 63 "WakeRsn63" 64 "WakeRsn64" 65 "WakeRsn65" 66 "WakeRsn66" 67 "WakeRsn67" 68 "WakeRsn68" 69 "WakeRsn69" 70 "WakeRsn70" 71 "WakeRsn71" 72 "WakeRsn72" 73 "WakeRsn73" 74 "WakeRsn74" 75 "WakeRsn75" 76 "WakeRsn76" 77 "WakeRsn77" 78 "WakeRsn78" 79 "WakeRsn79" 80 "WakeRsn80" 81 "WakeRsn81" 82 "WakeRsn82" 83 "WakeRsn83" 84 "WakeRsn84" 85 "WakeRsn85" 86 "WakeRsn86" 87 "WakeRsn87" 88 "WakeRsn88" 89 "WakeRsn89" 90 "WakeRsn90" 91 "WakeRsn91" 92 "WakeRsn92" 93 "WakeRsn93" 94 "WakeRsn94" 95 "WakeRsn95" 96 "WakeRsn96" 97 "WakeRsn97" 98 "WakeRsn98" 99 "WakeRsn99" 100 "WakeRsn100" 101 "WakeRsn101" 102 "WakeRsn102" 103 "WakeRsn103" 104 "WakeRsn104" 105 "WakeRsn105" 106 "WakeRsn106" 107 "WakeRsn107" 108 "WakeRsn108" 109 "WakeRsn109" 110 "WakeRsn110" 111 "WakeRsn111" 112 "WakeRsn112" 113 "WakeRsn113" 114 "WakeRsn114" 115 "WakeRsn115" 116 "WakeRsn116" 117 "WakeRsn117" 118 "WakeRsn118" 119 "WakeRsn119" 120 "WakeRsn120" 121 "WakeRsn121" 122 "WakeRsn122" 123 "WakeRsn123" 124 "WakeRsn124" 125 "WakeRsn125" 126 "WakeRsn126" 127 "WakeRsn127";
VAL_ 2654208022 WakeReq_SHIFTER 0 "NotActive" 1 "Active";
VAL_ 2654208022 WakeRsn_SHIFTER 0 "Diag" 1 "Network" 2 "WakeRsn2" 3 "WakeRsn3" 4 "WakeRsn4" 5 "WakeRsn5" 6 "WakeRsn6" 7 "WakeRsn7" 8 "WakeRsn8" 9 "WakeRsn9" 10 "WakeRsn10" 11 "WakeRsn11" 12 "WakeRsn12" 13 "WakeRsn13" 14 "WakeRsn14" 15 "WakeRsn15" 16 "WakeRsn16" 17 "WakeRsn17" 18 "WakeRsn18" 19 "WakeRsn19" 20 "WakeRsn20" 21 "WakeRsn21" 22 "WakeRsn22" 23 "WakeRsn23" 24 "WakeRsn24" 25 "WakeRsn25" 26 "WakeRsn26" 27 "WakeRsn27" 28 "WakeRsn28" 29 "WakeRsn29" 30 "WakeRsn30" 31 "WakeRsn31" 32 "WakeRsn32" 33 "WakeRsn33" 34 "WakeRsn34" 35 "WakeRsn35" 36 "WakeRsn36" 37 "WakeRsn37" 38 "WakeRsn38" 39 "WakeRsn39" 40 "WakeRsn40" 41 "WakeRsn41" 42 "WakeRsn42" 43 "WakeRsn43" 44 "WakeRsn44" 45 "WakeRsn45" 46 "WakeRsn46" 47 "WakeRsn47" 48 "WakeRsn48" 49 "WakeRsn49" 50 "WakeRsn50" 51 "WakeRsn51" 52 "WakeRsn52" 53 "WakeRsn53" 54 "WakeRsn54" 55 "WakeRsn55" 56 "WakeRsn56" 57 "WakeRsn57" 58 "WakeRsn58" 59 "WakeRsn59" 60 "WakeRsn60" 61 "WakeRsn61" 62 "WakeRsn62" 63 "WakeRsn63" 64 "WakeRsn64" 65 "WakeRsn65" 66 "WakeRsn66" 67 "WakeRsn67" 68 "WakeRsn68" 69 "WakeRsn69" 70 "WakeRsn70" 71 "WakeRsn71" 72 "WakeRsn72" 73 "WakeRsn73" 74 "WakeRsn74" 75 "WakeRsn75" 76 "WakeRsn76" 77 "WakeRsn77" 78 "WakeRsn78" 79 "WakeRsn79" 80 "WakeRsn80" 81 "WakeRsn81" 82 "WakeRsn82" 83 "WakeRsn83" 84 "WakeRsn84" 85 "WakeRsn85" 86 "WakeRsn86" 87 "WakeRsn87" 88 "WakeRsn88" 89 "WakeRsn89" 90 "WakeRsn90" 91 "WakeRsn91" 92 "WakeRsn92" 93 "WakeRsn93" 94 "WakeRsn94" 95 "WakeRsn95" 96 "WakeRsn96" 97 "WakeRsn97" 98 "WakeRsn98" 99 "WakeRsn99" 100 "WakeRsn100" 101 "WakeRsn101" 102 "WakeRsn102" 103 "WakeRsn103" 104 "WakeRsn104" 105 "WakeRsn105" 106 "WakeRsn106" 107 "WakeRsn107" 108 "WakeRsn108" 109 "WakeRsn109" 110 "WakeRsn110" 111 "WakeRsn111" 112 "WakeRsn112" 113 "WakeRsn113" 114 "WakeRsn114" 115 "WakeRsn115" 116 "WakeRsn116" 117 "WakeRsn117" 118 "WakeRsn118" 119 "WakeRsn119" 120 "WakeRsn120" 121 "WakeRsn121" 122 "WakeRsn122" 123 "WakeRsn123" 124 "WakeRsn124" 125 "WakeRsn125" 126 "WakeRsn126" 127 "WakeRsn127";
VAL_ 278 LHF_FastPulseCounter 255 "SNA";
VAL_ 278 LHF_Spin 0 "Stand_Still" 1 "Forward" 2 "Backward" 3 "SNA";
VAL_ 278 LHF_WheelSensorFailSts 0 "Fail_Not_Present" 1 "Fail_Present";
VAL_ 278 LHR_FastPulseCounter 255 "SNA";
VAL_ 278 LHR_Spin 0 "Stand_Still" 1 "Forward" 2 "Backward" 3 "SNA";
VAL_ 278 LHR_WheelSensorFailSts 0 "Fail_Not_Present" 1 "Fail_Present";
VAL_ 278 RHF_FastPulseCounter 255 "SNA";
VAL_ 278 RHF_Spin 0 "Stand_Still" 1 "Forward" 2 "Backward" 3 "SNA";
VAL_ 278 RHF_WheelSensorFailSts 0 "Fail_Not_Present" 1 "Fail_Present";
VAL_ 278 RHR_FastPulseCounter 255 "SNA";
VAL_ 278 RHR_Spin 0 "Stand_Still" 1 "Forward" 2 "Backward" 3 "SNA";
VAL_ 278 RHR_WheelSensorFailSts 0 "Fail_Not_Present" 1 "Fail_Present";
VAL_ 238 LHFWheelSpeed 8191 "SNA";
VAL_ 238 LHRWheelSpeed 8191 "SNA";
VAL_ 238 RHFWheelSpeed 8191 "SNA";
VAL_ 238 RHRWheelSpeed 8191 "SNA";
